[part 2 of 2: packages /MICROSAR/Csm_swc/Interfaces to /MICROSAR/Csm_swc/ComponentTypes]
AUTOSAR XML (schema 00049)
package /MICROSAR/Csm_swc/Interfaces  (continued)
  29 x client server interface, all with is-service=true, service-kind=CRYPTO-SERVICE-MANAGER:  (continued)
    CsmMacVerify_MacVerifyAesCmac  # A message authentication code (MAC) is a short piece of information used to authenticate a message. A MAC algorithm accepts as input a secret key and an arbitrary-length message to be authenticated, and outputs a MAC. The MAC value protects both a message's data integrity as well as its authenticity, by allowing verifiers (who also possess the secret key) to detect any changes to the message content.
      operation MacVerify: possible-error=[CsmMacVerify_MacVerifyAesCmac/E_NOT_OK, CsmMacVerify_MacVerifyAesCmac/CSM_E_BUSY, CsmMacVerify_MacVerifyAesCmac/CSM_E_SMALL_BUFFER, CsmMacVerify_MacVerifyAesCmac/CSM_E_KEY_NOT_VALID, CsmMacVerify_MacVerifyAesCmac/CSM_E_KEY_SIZE_MISMATCH, CsmMacVerify_MacVerifyAesCmac/CSM_E_KEY_EMPTY]  # This interface shall be used to start the MAC verification service of the CSM module.
        5 x arg:
          dataBuffer: type=Csm_MacVerifyDataType_MacVerifyAesCmac, direction=IN, server-argument-impl-policy=USE-ARRAY-BASE-TYPE  # Holds a pointer to the data for which a MAC shall be computed.
          dataLength: type=uint32, direction=IN  # Contains the number of bytes for which the MAC shall be computed.
          compareBuffer: type=Csm_MacVerifyCompareType_MacVerifyAesCmac, direction=IN, server-argument-impl-policy=USE-ARRAY-BASE-TYPE  # Contains the MAC to be verified.
          compareLength: type=uint32, direction=IN  # Contains the length of the MAC to be verified in BITS.
          verifyResult: type=Crypto_VerifyResultType, direction=OUT  # Holds a pointer to the memory location which will hold the result of the MAC verification
      operation CancelJob: possible-error=[CsmMacVerify_MacVerifyAesCmac/E_NOT_OK, CsmMacVerify_MacVerifyAesCmac/CSM_E_JOB_CANCELED]  # Cancels the Job.
      7 x error:
        E_NOT_OK: error-code=1  # The service request failed.
        CSM_E_BUSY: error-code=2  # The service request failed because the service is still busy.
        CSM_E_SMALL_BUFFER: error-code=3  # The service request failed because the provided buffer is too small to store the result.
        CSM_E_KEY_NOT_VALID: error-code=9  # The service request failed because the key is not valid.
        CSM_E_KEY_SIZE_MISMATCH: error-code=10  # The service request failed because the key element is not partially accessible and the provided key element length is too short or too long for that key element.
        CSM_E_KEY_EMPTY: error-code=13  # The service request failed because of uninitialized source key element.
        CSM_E_JOB_CANCELED: error-code=12  # The job has been marked to be aborted at the next opportunity. It will be further processed until the job finish notification.
    CsmDecrypt_AES128Decrypt  # This interface is used to perform the decryption.
      operation Decrypt: possible-error=[CsmDecrypt_AES128Decrypt/E_NOT_OK, CsmDecrypt_AES128Decrypt/CSM_E_BUSY, CsmDecrypt_AES128Decrypt/CSM_E_SMALL_BUFFER, CsmDecrypt_AES128Decrypt/CSM_E_KEY_NOT_VALID, CsmDecrypt_AES128Decrypt/CSM_E_KEY_SIZE_MISMATCH, CsmDecrypt_AES128Decrypt/CSM_E_KEY_EMPTY]  # This interface shall be used to start the Decrypt service of the CSM module.
        4 x arg:
          dataBuffer: type=Csm_DecryptDataType_AES128Decrypt, direction=IN, server-argument-impl-policy=USE-ARRAY-BASE-TYPE  # Holds a pointer to the data for which a plaintext shall be computed.
          dataLength: type=uint32, direction=IN  # Contains the number of bytes for which the plaintext shall be computed.
          resultBuffer: type=Csm_DecryptResultType_AES128Decrypt, direction=OUT, server-argument-impl-policy=USE-ARRAY-BASE-TYPE  # Holds a pointer to the memory location which will hold the plaintext. The memory location must have at least the given length.
          resultLength: type=uint32, direction=INOUT  # Holds a pointer to the memory location in which the length information is stored. On calling this function this parameter shall contain the size of the provided buffer. When the request has finished, the actual length of the returned plaintext shall be stored.
      operation CancelJob: possible-error=[CsmDecrypt_AES128Decrypt/E_NOT_OK, CsmDecrypt_AES128Decrypt/CSM_E_JOB_CANCELED]  # Cancels the Job.
      7 x error:
        E_NOT_OK: error-code=1  # The service request failed.
        CSM_E_BUSY: error-code=2  # The service request failed because the service is still busy.
        CSM_E_SMALL_BUFFER: error-code=3  # The service request failed because the provided buffer is too small to store the result.
        CSM_E_KEY_NOT_VALID: error-code=9  # The service request failed because the key is not valid.
        CSM_E_KEY_SIZE_MISMATCH: error-code=10  # The service request failed because the key element is not partially accessible and the provided key element length is too short or too long for that key element.
        CSM_E_KEY_EMPTY: error-code=13  # The service request failed because of uninitialized source key element.
        CSM_E_JOB_CANCELED: error-code=12  # The job has been marked to be aborted at the next opportunity. It will be further processed until the job finish notification.
    CsmMacGenerate_MacGenAesCmac  # A message authentication code (MAC) is a short piece of information used to authenticate a message. A MAC algorithm accepts as input a secret key and an arbitrary-length message to be authenticated, and outputs a MAC. The MAC value protects both a message's data integrity as well as its authenticity, by allowing verifiers (who also possess the secret key) to detect any changes to the message content.
      operation MacGenerate: possible-error=[CsmMacGenerate_MacGenAesCmac/E_NOT_OK, CsmMacGenerate_MacGenAesCmac/CSM_E_BUSY, CsmMacGenerate_MacGenAesCmac/CSM_E_SMALL_BUFFER, CsmMacGenerate_MacGenAesCmac/CSM_E_KEY_NOT_VALID, CsmMacGenerate_MacGenAesCmac/CSM_E_KEY_SIZE_MISMATCH, CsmMacGenerate_MacGenAesCmac/CSM_E_KEY_EMPTY]  # This interface shall be used to start the MAC generation service of the CSM module.
        4 x arg:
          dataBuffer: type=Csm_MacGenerateDataType_MacGenAesCmac, direction=IN, server-argument-impl-policy=USE-ARRAY-BASE-TYPE  # Holds a pointer to the data for which a MAC shall be computed.
          dataLength: type=uint32, direction=IN  # Contains the number of bytes for which the MAC shall be computed.
          resultBuffer: type=Csm_MacGenerateResultType_MacGenAesCmac, direction=OUT, server-argument-impl-policy=USE-ARRAY-BASE-TYPE  # Holds a pointer to the memory location which will hold the MAC. The memory location must have at least the given length.
          resultLength: type=uint32, direction=INOUT  # Holds a pointer to the memory location in which the length information is stored. On calling this function this parameter shall contain the size of the provided buffer. When the request has finished, the actual length of the returned MAC shall be stored.
      operation CancelJob: possible-error=[CsmMacGenerate_MacGenAesCmac/E_NOT_OK, CsmMacGenerate_MacGenAesCmac/CSM_E_JOB_CANCELED]  # Cancels the Job.
      7 x error:
        E_NOT_OK: error-code=1  # The service request failed.
        CSM_E_BUSY: error-code=2  # The service request failed because the service is still busy.
        CSM_E_SMALL_BUFFER: error-code=3  # The service request failed because the provided buffer is too small to store the result.
        CSM_E_KEY_NOT_VALID: error-code=9  # The service request failed because the key is not valid.
        CSM_E_KEY_SIZE_MISMATCH: error-code=10  # The service request failed because the key element is not partially accessible and the provided key element length is too short or too long for that key element.
        CSM_E_KEY_EMPTY: error-code=13  # The service request failed because of uninitialized source key element.
        CSM_E_JOB_CANCELED: error-code=12  # The job has been marked to be aborted at the next opportunity. It will be further processed until the job finish notification.
    CsmSignatureGenerate_SigGenEd25519  # A digital signature is a type of asymmetric cryptography. Digital signatures are equivalent to traditional handwritten signatures in many respects. Digital signatures can be used to authenticate the source of messages as well as to prove integrity of signed messages. If a message is digitally signed, any change in the message after signature will invalidate the signature. Furthermore, there is no efficient way to modify a message and its signature to produce a new message with a valid signature.
      operation SignatureGenerate: possible-error=[CsmSignatureGenerate_SigGenEd25519/E_NOT_OK, CsmSignatureGenerate_SigGenEd25519/CSM_E_BUSY, CsmSignatureGenerate_SigGenEd25519/CSM_E_SMALL_BUFFER, CsmSignatureGenerate_SigGenEd25519/CSM_E_KEY_NOT_VALID, CsmSignatureGenerate_SigGenEd25519/CSM_E_KEY_SIZE_MISMATCH, CsmSignatureGenerate_SigGenEd25519/CSM_E_KEY_EMPTY]  # This interface shall be used to start the signature generate service of the CSM module.
        4 x arg:
          dataBuffer: type=Csm_SignatureGenerateDataType_SigGenEd25519, direction=IN, server-argument-impl-policy=USE-ARRAY-BASE-TYPE  # Holds a pointer to the data for which a signature shall be computed.
          dataLength: type=uint32, direction=IN  # Contains the number of bytes for which the signature shall be computed.
          resultBuffer: type=Csm_SignatureGenerateResultType_SigGenEd25519, direction=OUT, server-argument-impl-policy=USE-ARRAY-BASE-TYPE  # Holds a pointer to the memory location which will hold the signature. The memory location must have at least the given length.
          resultLength: type=uint32, direction=INOUT  # Holds a pointer to the memory location in which the length information is stored. On calling this function this parameter shall contain the size of the provided buffer. When the request has finished, the actual length of the returned signature shall be stored.
      operation CancelJob: possible-error=[CsmSignatureGenerate_SigGenEd25519/E_NOT_OK, CsmSignatureGenerate_SigGenEd25519/CSM_E_JOB_CANCELED]  # Cancels the Job.
      7 x error:
        E_NOT_OK: error-code=1  # The service request failed.
        CSM_E_BUSY: error-code=2  # The service request failed because the service is still busy.
        CSM_E_SMALL_BUFFER: error-code=3  # The service request failed because the provided buffer is too small to store the result.
        CSM_E_KEY_NOT_VALID: error-code=9  # The service request failed because the key is not valid.
        CSM_E_KEY_SIZE_MISMATCH: error-code=10  # The service request failed because the key element is not partially accessible and the provided key element length is too short or too long for that key element.
        CSM_E_KEY_EMPTY: error-code=13  # The service request failed because of uninitialized source key element.
        CSM_E_JOB_CANCELED: error-code=12  # The job has been marked to be aborted at the next opportunity. It will be further processed until the job finish notification.
    CsmSignatureVerify_SigVerifyEd25519_SSA  # A digital signature is a type of asymmetric cryptography. Digital signatures are equivalent to traditional handwritten signatures in many respects. Digital signatures can be used to authenticate the source of messages as well as to prove integrity of signed messages. If a message is digitally signed, any change in the message after signature will invalidate the signature. Furthermore, there is no efficient way to modify a message and its signature to produce a new message with a valid signature.
      operation SignatureVerify: possible-error=[CsmSignatureVerify_SigVerifyEd25519_SSA/E_NOT_OK, CsmSignatureVerify_SigVerifyEd25519_SSA/CSM_E_BUSY, CsmSignatureVerify_SigVerifyEd25519_SSA/CSM_E_SMALL_BUFFER, CsmSignatureVerify_SigVerifyEd25519_SSA/CSM_E_KEY_NOT_VALID, CsmSignatureVerify_SigVerifyEd25519_SSA/CSM_E_KEY_SIZE_MISMATCH, CsmSignatureVerify_SigVerifyEd25519_SSA/CSM_E_KEY_EMPTY]  # This interface shall be used to start the signature verification service of the CSM module.
        5 x arg:
          dataBuffer: type=Csm_SignatureVerifyDataType_SigVerifyEd25519_SSA, direction=IN, server-argument-impl-policy=USE-ARRAY-BASE-TYPE  # Holds a pointer to the data for which a signature shall be computed.
          dataLength: type=uint32, direction=IN  # Contains the number of bytes for which the signature shall be computed.
          compareBuffer: type=Csm_SignatureVerifyCompareType_SigVerifyEd25519_SSA, direction=IN, server-argument-impl-policy=USE-ARRAY-BASE-TYPE  # Contains the signature to be verified.
          compareLength: type=uint32, direction=IN  # Contains the length of the signature to be verified in bytes.
          verifyResult: type=Crypto_VerifyResultType, direction=OUT  # Holds a pointer to the memory location which will hold the result of the signature verification
      operation CancelJob: possible-error=[CsmSignatureVerify_SigVerifyEd25519_SSA/E_NOT_OK, CsmSignatureVerify_SigVerifyEd25519_SSA/CSM_E_JOB_CANCELED]  # Cancels the Job.
      7 x error:
        E_NOT_OK: error-code=1  # The service request failed.
        CSM_E_BUSY: error-code=2  # The service request failed because the service is still busy.
        CSM_E_SMALL_BUFFER: error-code=3  # The service request failed because the provided buffer is too small to store the result.
        CSM_E_KEY_NOT_VALID: error-code=9  # The service request failed because the key is not valid.
        CSM_E_KEY_SIZE_MISMATCH: error-code=10  # The service request failed because the key element is not partially accessible and the provided key element length is too short or too long for that key element.
        CSM_E_KEY_EMPTY: error-code=13  # The service request failed because of uninitialized source key element.
        CSM_E_JOB_CANCELED: error-code=12  # The job has been marked to be aborted at the next opportunity. It will be further processed until the job finish notification.
    CsmKeyManagement_CsmKey_Ssa_TrustModelPrivateEcuUnique_StagingKey  # Interface to execute the key management functions.
      13 x operation:
        CertificateParse: possible-error=[CsmKeyManagement_CsmKey_Ssa_TrustModelPrivateEcuUnique_StagingKey/E_NOT_OK, CsmKeyManagement_CsmKey_Ssa_TrustModelPrivateEcuUnique_StagingKey/CSM_E_BUSY, CsmKeyManagement_CsmKey_Ssa_TrustModelPrivateEcuUnique_StagingKey/CSM_E_KEY_EMPTY]  # This function shall dispatch the certificate parse function to the CRYIF.
        CertificateVerify: possible-error=[CsmKeyManagement_CsmKey_Ssa_TrustModelPrivateEcuUnique_StagingKey/E_NOT_OK, CsmKeyManagement_CsmKey_Ssa_TrustModelPrivateEcuUnique_StagingKey/CSM_E_BUSY, CsmKeyManagement_CsmKey_Ssa_TrustModelPrivateEcuUnique_StagingKey/CSM_E_KEY_EMPTY]  # Verifies the certificate stored in the key referenced by verifyKeyId with the certificate stored in the key referenced by keyId. Note: Only certificates stored in the same Crypto Driver can be verified against each other. If the key element CRYPTO_KE_CERTIFICATE_CURRENT_TIME is used for the verification of the validity period of the certificate indentified by verifyKeyId, it shall have the same format as the timestamp in the certificate.
          arg verifyKeyId: type=uint32, direction=IN  # Holds the identifier of the key containing the certificate to be verified.
          arg verifyPtr: type=Crypto_VerifyResultType, direction=OUT  # Contains the result of the certificate verification.
        KeyCopy: possible-error=[CsmKeyManagement_CsmKey_Ssa_TrustModelPrivateEcuUnique_StagingKey/E_NOT_OK, CsmKeyManagement_CsmKey_Ssa_TrustModelPrivateEcuUnique_StagingKey/CSM_E_BUSY, CsmKeyManagement_CsmKey_Ssa_TrustModelPrivateEcuUnique_StagingKey/CSM_E_SMALL_BUFFER, CsmKeyManagement_CsmKey_Ssa_TrustModelPrivateEcuUnique_StagingKey/CSM_E_KEY_READ_FAIL, CsmKeyManagement_CsmKey_Ssa_TrustModelPrivateEcuUnique_StagingKey/CSM_E_KEY_WRITE_FAIL, CsmKeyManagement_CsmKey_Ssa_TrustModelPrivateEcuUnique_StagingKey/CSM_E_KEY_SIZE_MISMATCH, CsmKeyManagement_CsmKey_Ssa_TrustModelPrivateEcuUnique_StagingKey/CSM_E_KEY_EMPTY]  # This function shall copy all key elements from the source key to a target key.
          arg targetKeyId: type=uint32, direction=IN  # Holds the identifier of the key whose key element shall be the destination element.
        KeyDerive: possible-error=[CsmKeyManagement_CsmKey_Ssa_TrustModelPrivateEcuUnique_StagingKey/E_NOT_OK, CsmKeyManagement_CsmKey_Ssa_TrustModelPrivateEcuUnique_StagingKey/CSM_E_BUSY, CsmKeyManagement_CsmKey_Ssa_TrustModelPrivateEcuUnique_StagingKey/CSM_E_KEY_READ_FAIL, CsmKeyManagement_CsmKey_Ssa_TrustModelPrivateEcuUnique_StagingKey/CSM_E_KEY_WRITE_FAIL, CsmKeyManagement_CsmKey_Ssa_TrustModelPrivateEcuUnique_StagingKey/CSM_E_KEY_SIZE_MISMATCH, CsmKeyManagement_CsmKey_Ssa_TrustModelPrivateEcuUnique_StagingKey/CSM_E_KEY_EMPTY]  # Derives a new key by using the key elements in the given key. The given key contains the key elements for the password and salt. The derived key is stored in the key element with the id 1 of the key identified by targetCryptoKeyId.
          arg targetKeyId: type=uint32, direction=IN  # Holds the identifier of the key which is used to store the derived key.
        KeyElementCopy: possible-error=[CsmKeyManagement_CsmKey_Ssa_TrustModelPrivateEcuUnique_StagingKey/E_NOT_OK, CsmKeyManagement_CsmKey_Ssa_TrustModelPrivateEcuUnique_StagingKey/CSM_E_BUSY, CsmKeyManagement_CsmKey_Ssa_TrustModelPrivateEcuUnique_StagingKey/CSM_E_SMALL_BUFFER, CsmKeyManagement_CsmKey_Ssa_TrustModelPrivateEcuUnique_StagingKey/CSM_E_KEY_READ_FAIL, CsmKeyManagement_CsmKey_Ssa_TrustModelPrivateEcuUnique_StagingKey/CSM_E_KEY_WRITE_FAIL, CsmKeyManagement_CsmKey_Ssa_TrustModelPrivateEcuUnique_StagingKey/CSM_E_KEY_SIZE_MISMATCH, CsmKeyManagement_CsmKey_Ssa_TrustModelPrivateEcuUnique_StagingKey/CSM_E_KEY_EMPTY]  # This function shall copy a key elements from one key to a target key.
          arg keyElementId: type=uint32, direction=IN  # Holds the identifier of the key element which shall be the source for the copy operation.
          arg targetKeyId: type=uint32, direction=IN  # Holds the identifier of the key whose key element shall be the destination element.
          arg targetKeyElementId: type=uint32, direction=IN  # Holds the identifier of the key element which shall be the destination for the copy operation.
        KeyElementCopyPartial: possible-error=[CsmKeyManagement_CsmKey_Ssa_TrustModelPrivateEcuUnique_StagingKey/E_NOT_OK, CsmKeyManagement_CsmKey_Ssa_TrustModelPrivateEcuUnique_StagingKey/CSM_E_BUSY, CsmKeyManagement_CsmKey_Ssa_TrustModelPrivateEcuUnique_StagingKey/CSM_E_KEY_NOT_AVAILABLE, CsmKeyManagement_CsmKey_Ssa_TrustModelPrivateEcuUnique_StagingKey/CSM_E_KEY_READ_FAIL, CsmKeyManagement_CsmKey_Ssa_TrustModelPrivateEcuUnique_StagingKey/CSM_E_KEY_WRITE_FAIL, CsmKeyManagement_CsmKey_Ssa_TrustModelPrivateEcuUnique_StagingKey/CSM_E_KEY_SIZE_MISMATCH, CsmKeyManagement_CsmKey_Ssa_TrustModelPrivateEcuUnique_StagingKey/CSM_E_KEY_EMPTY]  # This function shall copy parts of a key element from one key to parts of a target key element of a target key.
          6 x arg, all with type=uint32, direction=IN:
            keyElementId  # Holds the identifier of the key element which shall be the source for the copy operation.
            keyElementSourceOffset  # This is the offset of the source key element indicating the start index of the copy operation.
            keyElementTargetOffset  # This is the offset of the destination key element indicating the start index of the copy operation.
            keyElementCopyLength  # Specifies the number of bytes that shall be copied.
            targetKeyId  # Holds the identifier of the key whose key element shall be the destination element.
            targetKeyElementId  # Holds the identifier of the key element which shall be the destination for the copy operation.
        KeyElementGet: possible-error=[CsmKeyManagement_CsmKey_Ssa_TrustModelPrivateEcuUnique_StagingKey/E_NOT_OK, CsmKeyManagement_CsmKey_Ssa_TrustModelPrivateEcuUnique_StagingKey/CSM_E_BUSY, CsmKeyManagement_CsmKey_Ssa_TrustModelPrivateEcuUnique_StagingKey/CSM_E_SMALL_BUFFER, CsmKeyManagement_CsmKey_Ssa_TrustModelPrivateEcuUnique_StagingKey/CSM_E_KEY_READ_FAIL, CsmKeyManagement_CsmKey_Ssa_TrustModelPrivateEcuUnique_StagingKey/CSM_E_KEY_NOT_AVAILABLE, CsmKeyManagement_CsmKey_Ssa_TrustModelPrivateEcuUnique_StagingKey/CSM_E_KEY_EMPTY]  # Retrieves the key element bytes from a specific key element of the key and stores the key element in the provided buffer.
          arg keyElementId: type=uint32, direction=IN  # Holds the identifier of the key element to be read.
          arg keyPtr: type=Csm_KeyDataType_CsmKey_Ssa_TrustModelPrivateEcuUnique_StagingKey, direction=OUT, server-argument-impl-policy=USE-ARRAY-BASE-TYPE  # Holds the data to the key element bytes to be written.
          arg keyLength: type=uint32, direction=INOUT  # Contains the number of key element bytes.
        KeyElementSet: possible-error=[CsmKeyManagement_CsmKey_Ssa_TrustModelPrivateEcuUnique_StagingKey/E_NOT_OK, CsmKeyManagement_CsmKey_Ssa_TrustModelPrivateEcuUnique_StagingKey/CSM_E_BUSY, CsmKeyManagement_CsmKey_Ssa_TrustModelPrivateEcuUnique_StagingKey/CSM_E_KEY_WRITE_FAIL, CsmKeyManagement_CsmKey_Ssa_TrustModelPrivateEcuUnique_StagingKey/CSM_E_KEY_NOT_AVAILABLE, CsmKeyManagement_CsmKey_Ssa_TrustModelPrivateEcuUnique_StagingKey/CSM_E_KEY_SIZE_MISMATCH]  # Sets the given key element bytes to the key.
          arg keyElementId: type=uint32, direction=IN  # Holds the identifier of the key element to be written.
          arg keyPtr: type=Csm_KeyDataType_CsmKey_Ssa_TrustModelPrivateEcuUnique_StagingKey, direction=IN, server-argument-impl-policy=USE-ARRAY-BASE-TYPE  # Holds the data to the key element bytes to be processed.
          arg keyLength: type=uint32, direction=IN  # Contains the number of key element bytes.
        KeyExchangeCalcPubVal: possible-error=[CsmKeyManagement_CsmKey_Ssa_TrustModelPrivateEcuUnique_StagingKey/E_NOT_OK, CsmKeyManagement_CsmKey_Ssa_TrustModelPrivateEcuUnique_StagingKey/CSM_E_BUSY, CsmKeyManagement_CsmKey_Ssa_TrustModelPrivateEcuUnique_StagingKey/CSM_E_SMALL_BUFFER, CsmKeyManagement_CsmKey_Ssa_TrustModelPrivateEcuUnique_StagingKey/CSM_E_KEY_EMPTY]  # Calculates the public value of the current user for the key exchange and stores the public key in the provided buffer.
          arg publicValuePtr: type=Csm_PublicValueDataType_CsmKey_Ssa_TrustModelPrivateEcuUnique_StagingKey, direction=OUT, server-argument-impl-policy=USE-ARRAY-BASE-TYPE  # Holds a pointer to the memory location in which the public value length in bytes is stored. On calling this function, this parameter shall contain the size of the buffer in bytes provided by publicValuePtr. When the request has finished, the actual length of the returned value shall be stored.
          arg publicValueLengthPtr: type=uint32, direction=INOUT  # Contains the pointer to the data where the public value shall be stored.
        KeyExchangeCalcSecret: possible-error=[CsmKeyManagement_CsmKey_Ssa_TrustModelPrivateEcuUnique_StagingKey/E_NOT_OK, CsmKeyManagement_CsmKey_Ssa_TrustModelPrivateEcuUnique_StagingKey/CSM_E_BUSY, CsmKeyManagement_CsmKey_Ssa_TrustModelPrivateEcuUnique_StagingKey/CSM_E_SMALL_BUFFER, CsmKeyManagement_CsmKey_Ssa_TrustModelPrivateEcuUnique_StagingKey/CSM_E_KEY_EMPTY]  # Calculates the shared secret key for the key exchange with the key material of the key identified by the keyId and the partner public key. The shared secret key is stored as a key element in the same key.
          arg partnerPublicValuePtr: type=Csm_PublicValueDataType_CsmKey_Ssa_TrustModelPrivateEcuUnique_StagingKey, direction=IN, server-argument-impl-policy=USE-ARRAY-BASE-TYPE  # Holds the pointer to the memory location containing the partner's public value.
          arg partnerPublicValueLength: type=uint32, direction=IN  # Contains the number of bytes of the partner public value.
        KeyGenerate: possible-error=[CsmKeyManagement_CsmKey_Ssa_TrustModelPrivateEcuUnique_StagingKey/E_NOT_OK, CsmKeyManagement_CsmKey_Ssa_TrustModelPrivateEcuUnique_StagingKey/CSM_E_BUSY, CsmKeyManagement_CsmKey_Ssa_TrustModelPrivateEcuUnique_StagingKey/CSM_E_KEY_EMPTY]  # Generates new key material and store it in the key identified by keyId.
        KeySetValid: possible-error=[CsmKeyManagement_CsmKey_Ssa_TrustModelPrivateEcuUnique_StagingKey/E_NOT_OK, CsmKeyManagement_CsmKey_Ssa_TrustModelPrivateEcuUnique_StagingKey/CSM_E_BUSY]  # Sets the given key element bytes to the key.
        RandomSeed: possible-error=[CsmKeyManagement_CsmKey_Ssa_TrustModelPrivateEcuUnique_StagingKey/E_NOT_OK, CsmKeyManagement_CsmKey_Ssa_TrustModelPrivateEcuUnique_StagingKey/CSM_E_BUSY]  # Feeds a key element with a random seed.
          arg seedPtr: type=Csm_SeedDataTypeCsmKey_Ssa_TrustModelPrivateEcuUnique_StagingKey, direction=IN, server-argument-impl-policy=USE-ARRAY-BASE-TYPE  # Holds the data which shall be used for the random seed initialization.
          arg seedLength: type=uint32, direction=IN  # Contains the length of the seed in bytes.
      8 x error:
        E_NOT_OK: error-code=1  # The service request failed.
        CSM_E_BUSY: error-code=2  # The service request failed because the service is still busy.
        CSM_E_SMALL_BUFFER: error-code=3  # The service request failed because the provided buffer is too small to store the result.
        CSM_E_KEY_READ_FAIL: error-code=6  # The service request failed because read access was denied.
        CSM_E_KEY_WRITE_FAIL: error-code=7  # The service request failed because write access was denied.
        CSM_E_KEY_NOT_AVAILABLE: error-code=8  # The service request failed because the key is not available.
        CSM_E_KEY_SIZE_MISMATCH: error-code=10  # The service request failed because the key element is not partially accessible and the provided key element length is too short or too long for that key element.
        CSM_E_KEY_EMPTY: error-code=13  # The service request failed because of uninitialized source key element.
    CsmKeyManagement_CsmKey_Ssa_TrustModelEcuPublic_LiveKey  # Interface to execute the key management functions.
      13 x operation:
        CertificateParse: possible-error=[CsmKeyManagement_CsmKey_Ssa_TrustModelEcuPublic_LiveKey/E_NOT_OK, CsmKeyManagement_CsmKey_Ssa_TrustModelEcuPublic_LiveKey/CSM_E_BUSY, CsmKeyManagement_CsmKey_Ssa_TrustModelEcuPublic_LiveKey/CSM_E_KEY_EMPTY]  # This function shall dispatch the certificate parse function to the CRYIF.
        CertificateVerify: possible-error=[CsmKeyManagement_CsmKey_Ssa_TrustModelEcuPublic_LiveKey/E_NOT_OK, CsmKeyManagement_CsmKey_Ssa_TrustModelEcuPublic_LiveKey/CSM_E_BUSY, CsmKeyManagement_CsmKey_Ssa_TrustModelEcuPublic_LiveKey/CSM_E_KEY_EMPTY]  # Verifies the certificate stored in the key referenced by verifyKeyId with the certificate stored in the key referenced by keyId. Note: Only certificates stored in the same Crypto Driver can be verified against each other. If the key element CRYPTO_KE_CERTIFICATE_CURRENT_TIME is used for the verification of the validity period of the certificate indentified by verifyKeyId, it shall have the same format as the timestamp in the certificate.
          arg verifyKeyId: type=uint32, direction=IN  # Holds the identifier of the key containing the certificate to be verified.
          arg verifyPtr: type=Crypto_VerifyResultType, direction=OUT  # Contains the result of the certificate verification.
        KeyCopy: possible-error=[CsmKeyManagement_CsmKey_Ssa_TrustModelEcuPublic_LiveKey/E_NOT_OK, CsmKeyManagement_CsmKey_Ssa_TrustModelEcuPublic_LiveKey/CSM_E_BUSY, CsmKeyManagement_CsmKey_Ssa_TrustModelEcuPublic_LiveKey/CSM_E_SMALL_BUFFER, CsmKeyManagement_CsmKey_Ssa_TrustModelEcuPublic_LiveKey/CSM_E_KEY_READ_FAIL, CsmKeyManagement_CsmKey_Ssa_TrustModelEcuPublic_LiveKey/CSM_E_KEY_WRITE_FAIL, CsmKeyManagement_CsmKey_Ssa_TrustModelEcuPublic_LiveKey/CSM_E_KEY_SIZE_MISMATCH, CsmKeyManagement_CsmKey_Ssa_TrustModelEcuPublic_LiveKey/CSM_E_KEY_EMPTY]  # This function shall copy all key elements from the source key to a target key.
          arg targetKeyId: type=uint32, direction=IN  # Holds the identifier of the key whose key element shall be the destination element.
        KeyDerive: possible-error=[CsmKeyManagement_CsmKey_Ssa_TrustModelEcuPublic_LiveKey/E_NOT_OK, CsmKeyManagement_CsmKey_Ssa_TrustModelEcuPublic_LiveKey/CSM_E_BUSY, CsmKeyManagement_CsmKey_Ssa_TrustModelEcuPublic_LiveKey/CSM_E_KEY_READ_FAIL, CsmKeyManagement_CsmKey_Ssa_TrustModelEcuPublic_LiveKey/CSM_E_KEY_WRITE_FAIL, CsmKeyManagement_CsmKey_Ssa_TrustModelEcuPublic_LiveKey/CSM_E_KEY_SIZE_MISMATCH, CsmKeyManagement_CsmKey_Ssa_TrustModelEcuPublic_LiveKey/CSM_E_KEY_EMPTY]  # Derives a new key by using the key elements in the given key. The given key contains the key elements for the password and salt. The derived key is stored in the key element with the id 1 of the key identified by targetCryptoKeyId.
          arg targetKeyId: type=uint32, direction=IN  # Holds the identifier of the key which is used to store the derived key.
        KeyElementCopy: possible-error=[CsmKeyManagement_CsmKey_Ssa_TrustModelEcuPublic_LiveKey/E_NOT_OK, CsmKeyManagement_CsmKey_Ssa_TrustModelEcuPublic_LiveKey/CSM_E_BUSY, CsmKeyManagement_CsmKey_Ssa_TrustModelEcuPublic_LiveKey/CSM_E_SMALL_BUFFER, CsmKeyManagement_CsmKey_Ssa_TrustModelEcuPublic_LiveKey/CSM_E_KEY_READ_FAIL, CsmKeyManagement_CsmKey_Ssa_TrustModelEcuPublic_LiveKey/CSM_E_KEY_WRITE_FAIL, CsmKeyManagement_CsmKey_Ssa_TrustModelEcuPublic_LiveKey/CSM_E_KEY_SIZE_MISMATCH, CsmKeyManagement_CsmKey_Ssa_TrustModelEcuPublic_LiveKey/CSM_E_KEY_EMPTY]  # This function shall copy a key elements from one key to a target key.
          arg keyElementId: type=uint32, direction=IN  # Holds the identifier of the key element which shall be the source for the copy operation.
          arg targetKeyId: type=uint32, direction=IN  # Holds the identifier of the key whose key element shall be the destination element.
          arg targetKeyElementId: type=uint32, direction=IN  # Holds the identifier of the key element which shall be the destination for the copy operation.
        KeyElementCopyPartial: possible-error=[CsmKeyManagement_CsmKey_Ssa_TrustModelEcuPublic_LiveKey/E_NOT_OK, CsmKeyManagement_CsmKey_Ssa_TrustModelEcuPublic_LiveKey/CSM_E_BUSY, CsmKeyManagement_CsmKey_Ssa_TrustModelEcuPublic_LiveKey/CSM_E_KEY_NOT_AVAILABLE, CsmKeyManagement_CsmKey_Ssa_TrustModelEcuPublic_LiveKey/CSM_E_KEY_READ_FAIL, CsmKeyManagement_CsmKey_Ssa_TrustModelEcuPublic_LiveKey/CSM_E_KEY_WRITE_FAIL, CsmKeyManagement_CsmKey_Ssa_TrustModelEcuPublic_LiveKey/CSM_E_KEY_SIZE_MISMATCH, CsmKeyManagement_CsmKey_Ssa_TrustModelEcuPublic_LiveKey/CSM_E_KEY_EMPTY]  # This function shall copy parts of a key element from one key to parts of a target key element of a target key.
          6 x arg, all with type=uint32, direction=IN:
            keyElementId  # Holds the identifier of the key element which shall be the source for the copy operation.
            keyElementSourceOffset  # This is the offset of the source key element indicating the start index of the copy operation.
            keyElementTargetOffset  # This is the offset of the destination key element indicating the start index of the copy operation.
            keyElementCopyLength  # Specifies the number of bytes that shall be copied.
            targetKeyId  # Holds the identifier of the key whose key element shall be the destination element.
            targetKeyElementId  # Holds the identifier of the key element which shall be the destination for the copy operation.
        KeyElementGet: possible-error=[CsmKeyManagement_CsmKey_Ssa_TrustModelEcuPublic_LiveKey/E_NOT_OK, CsmKeyManagement_CsmKey_Ssa_TrustModelEcuPublic_LiveKey/CSM_E_BUSY, CsmKeyManagement_CsmKey_Ssa_TrustModelEcuPublic_LiveKey/CSM_E_SMALL_BUFFER, CsmKeyManagement_CsmKey_Ssa_TrustModelEcuPublic_LiveKey/CSM_E_KEY_READ_FAIL, CsmKeyManagement_CsmKey_Ssa_TrustModelEcuPublic_LiveKey/CSM_E_KEY_NOT_AVAILABLE, CsmKeyManagement_CsmKey_Ssa_TrustModelEcuPublic_LiveKey/CSM_E_KEY_EMPTY]  # Retrieves the key element bytes from a specific key element of the key and stores the key element in the provided buffer.
          arg keyElementId: type=uint32, direction=IN  # Holds the identifier of the key element to be read.
          arg keyPtr: type=Csm_KeyDataType_CsmKey_Ssa_TrustModelEcuPublic_LiveKey, direction=OUT, server-argument-impl-policy=USE-ARRAY-BASE-TYPE  # Holds the data to the key element bytes to be written.
          arg keyLength: type=uint32, direction=INOUT  # Contains the number of key element bytes.
        KeyElementSet: possible-error=[CsmKeyManagement_CsmKey_Ssa_TrustModelEcuPublic_LiveKey/E_NOT_OK, CsmKeyManagement_CsmKey_Ssa_TrustModelEcuPublic_LiveKey/CSM_E_BUSY, CsmKeyManagement_CsmKey_Ssa_TrustModelEcuPublic_LiveKey/CSM_E_KEY_WRITE_FAIL, CsmKeyManagement_CsmKey_Ssa_TrustModelEcuPublic_LiveKey/CSM_E_KEY_NOT_AVAILABLE, CsmKeyManagement_CsmKey_Ssa_TrustModelEcuPublic_LiveKey/CSM_E_KEY_SIZE_MISMATCH]  # Sets the given key element bytes to the key.
          arg keyElementId: type=uint32, direction=IN  # Holds the identifier of the key element to be written.
          arg keyPtr: type=Csm_KeyDataType_CsmKey_Ssa_TrustModelEcuPublic_LiveKey, direction=IN, server-argument-impl-policy=USE-ARRAY-BASE-TYPE  # Holds the data to the key element bytes to be processed.
          arg keyLength: type=uint32, direction=IN  # Contains the number of key element bytes.
        KeyExchangeCalcPubVal: possible-error=[CsmKeyManagement_CsmKey_Ssa_TrustModelEcuPublic_LiveKey/E_NOT_OK, CsmKeyManagement_CsmKey_Ssa_TrustModelEcuPublic_LiveKey/CSM_E_BUSY, CsmKeyManagement_CsmKey_Ssa_TrustModelEcuPublic_LiveKey/CSM_E_SMALL_BUFFER, CsmKeyManagement_CsmKey_Ssa_TrustModelEcuPublic_LiveKey/CSM_E_KEY_EMPTY]  # Calculates the public value of the current user for the key exchange and stores the public key in the provided buffer.
          arg publicValuePtr: type=Csm_PublicValueDataType_CsmKey_Ssa_TrustModelEcuPublic_LiveKey, direction=OUT, server-argument-impl-policy=USE-ARRAY-BASE-TYPE  # Holds a pointer to the memory location in which the public value length in bytes is stored. On calling this function, this parameter shall contain the size of the buffer in bytes provided by publicValuePtr. When the request has finished, the actual length of the returned value shall be stored.
          arg publicValueLengthPtr: type=uint32, direction=INOUT  # Contains the pointer to the data where the public value shall be stored.
        KeyExchangeCalcSecret: possible-error=[CsmKeyManagement_CsmKey_Ssa_TrustModelEcuPublic_LiveKey/E_NOT_OK, CsmKeyManagement_CsmKey_Ssa_TrustModelEcuPublic_LiveKey/CSM_E_BUSY, CsmKeyManagement_CsmKey_Ssa_TrustModelEcuPublic_LiveKey/CSM_E_SMALL_BUFFER, CsmKeyManagement_CsmKey_Ssa_TrustModelEcuPublic_LiveKey/CSM_E_KEY_EMPTY]  # Calculates the shared secret key for the key exchange with the key material of the key identified by the keyId and the partner public key. The shared secret key is stored as a key element in the same key.
          arg partnerPublicValuePtr: type=Csm_PublicValueDataType_CsmKey_Ssa_TrustModelEcuPublic_LiveKey, direction=IN, server-argument-impl-policy=USE-ARRAY-BASE-TYPE  # Holds the pointer to the memory location containing the partner's public value.
          arg partnerPublicValueLength: type=uint32, direction=IN  # Contains the number of bytes of the partner public value.
        KeyGenerate: possible-error=[CsmKeyManagement_CsmKey_Ssa_TrustModelEcuPublic_LiveKey/E_NOT_OK, CsmKeyManagement_CsmKey_Ssa_TrustModelEcuPublic_LiveKey/CSM_E_BUSY, CsmKeyManagement_CsmKey_Ssa_TrustModelEcuPublic_LiveKey/CSM_E_KEY_EMPTY]  # Generates new key material and store it in the key identified by keyId.
        KeySetValid: possible-error=[CsmKeyManagement_CsmKey_Ssa_TrustModelEcuPublic_LiveKey/E_NOT_OK, CsmKeyManagement_CsmKey_Ssa_TrustModelEcuPublic_LiveKey/CSM_E_BUSY]  # Sets the given key element bytes to the key.
        RandomSeed: possible-error=[CsmKeyManagement_CsmKey_Ssa_TrustModelEcuPublic_LiveKey/E_NOT_OK, CsmKeyManagement_CsmKey_Ssa_TrustModelEcuPublic_LiveKey/CSM_E_BUSY]  # Feeds a key element with a random seed.
          arg seedPtr: type=Csm_SeedDataTypeCsmKey_Ssa_TrustModelEcuPublic_LiveKey, direction=IN, server-argument-impl-policy=USE-ARRAY-BASE-TYPE  # Holds the data which shall be used for the random seed initialization.
          arg seedLength: type=uint32, direction=IN  # Contains the length of the seed in bytes.
      8 x error:
        E_NOT_OK: error-code=1  # The service request failed.
        CSM_E_BUSY: error-code=2  # The service request failed because the service is still busy.
        CSM_E_SMALL_BUFFER: error-code=3  # The service request failed because the provided buffer is too small to store the result.
        CSM_E_KEY_READ_FAIL: error-code=6  # The service request failed because read access was denied.
        CSM_E_KEY_WRITE_FAIL: error-code=7  # The service request failed because write access was denied.
        CSM_E_KEY_NOT_AVAILABLE: error-code=8  # The service request failed because the key is not available.
        CSM_E_KEY_SIZE_MISMATCH: error-code=10  # The service request failed because the key element is not partially accessible and the provided key element length is too short or too long for that key element.
        CSM_E_KEY_EMPTY: error-code=13  # The service request failed because of uninitialized source key element.
    CsmKeyManagement_CsmKey_Ssa_TrustModelEcuPublicCsr_StagingKey  # Interface to execute the key management functions.
      13 x operation:
        CertificateParse: possible-error=[CsmKeyManagement_CsmKey_Ssa_TrustModelEcuPublicCsr_StagingKey/E_NOT_OK, CsmKeyManagement_CsmKey_Ssa_TrustModelEcuPublicCsr_StagingKey/CSM_E_BUSY, CsmKeyManagement_CsmKey_Ssa_TrustModelEcuPublicCsr_StagingKey/CSM_E_KEY_EMPTY]  # This function shall dispatch the certificate parse function to the CRYIF.
        CertificateVerify: possible-error=[CsmKeyManagement_CsmKey_Ssa_TrustModelEcuPublicCsr_StagingKey/E_NOT_OK, CsmKeyManagement_CsmKey_Ssa_TrustModelEcuPublicCsr_StagingKey/CSM_E_BUSY, CsmKeyManagement_CsmKey_Ssa_TrustModelEcuPublicCsr_StagingKey/CSM_E_KEY_EMPTY]  # Verifies the certificate stored in the key referenced by verifyKeyId with the certificate stored in the key referenced by keyId. Note: Only certificates stored in the same Crypto Driver can be verified against each other. If the key element CRYPTO_KE_CERTIFICATE_CURRENT_TIME is used for the verification of the validity period of the certificate indentified by verifyKeyId, it shall have the same format as the timestamp in the certificate.
          arg verifyKeyId: type=uint32, direction=IN  # Holds the identifier of the key containing the certificate to be verified.
          arg verifyPtr: type=Crypto_VerifyResultType, direction=OUT  # Contains the result of the certificate verification.
        KeyCopy: possible-error=[CsmKeyManagement_CsmKey_Ssa_TrustModelEcuPublicCsr_StagingKey/E_NOT_OK, CsmKeyManagement_CsmKey_Ssa_TrustModelEcuPublicCsr_StagingKey/CSM_E_BUSY, CsmKeyManagement_CsmKey_Ssa_TrustModelEcuPublicCsr_StagingKey/CSM_E_SMALL_BUFFER, CsmKeyManagement_CsmKey_Ssa_TrustModelEcuPublicCsr_StagingKey/CSM_E_KEY_READ_FAIL, CsmKeyManagement_CsmKey_Ssa_TrustModelEcuPublicCsr_StagingKey/CSM_E_KEY_WRITE_FAIL, CsmKeyManagement_CsmKey_Ssa_TrustModelEcuPublicCsr_StagingKey/CSM_E_KEY_SIZE_MISMATCH, CsmKeyManagement_CsmKey_Ssa_TrustModelEcuPublicCsr_StagingKey/CSM_E_KEY_EMPTY]  # This function shall copy all key elements from the source key to a target key.
          arg targetKeyId: type=uint32, direction=IN  # Holds the identifier of the key whose key element shall be the destination element.
        KeyDerive: possible-error=[CsmKeyManagement_CsmKey_Ssa_TrustModelEcuPublicCsr_StagingKey/E_NOT_OK, CsmKeyManagement_CsmKey_Ssa_TrustModelEcuPublicCsr_StagingKey/CSM_E_BUSY, CsmKeyManagement_CsmKey_Ssa_TrustModelEcuPublicCsr_StagingKey/CSM_E_KEY_READ_FAIL, CsmKeyManagement_CsmKey_Ssa_TrustModelEcuPublicCsr_StagingKey/CSM_E_KEY_WRITE_FAIL, CsmKeyManagement_CsmKey_Ssa_TrustModelEcuPublicCsr_StagingKey/CSM_E_KEY_SIZE_MISMATCH, CsmKeyManagement_CsmKey_Ssa_TrustModelEcuPublicCsr_StagingKey/CSM_E_KEY_EMPTY]  # Derives a new key by using the key elements in the given key. The given key contains the key elements for the password and salt. The derived key is stored in the key element with the id 1 of the key identified by targetCryptoKeyId.
          arg targetKeyId: type=uint32, direction=IN  # Holds the identifier of the key which is used to store the derived key.
        KeyElementCopy: possible-error=[CsmKeyManagement_CsmKey_Ssa_TrustModelEcuPublicCsr_StagingKey/E_NOT_OK, CsmKeyManagement_CsmKey_Ssa_TrustModelEcuPublicCsr_StagingKey/CSM_E_BUSY, CsmKeyManagement_CsmKey_Ssa_TrustModelEcuPublicCsr_StagingKey/CSM_E_SMALL_BUFFER, CsmKeyManagement_CsmKey_Ssa_TrustModelEcuPublicCsr_StagingKey/CSM_E_KEY_READ_FAIL, CsmKeyManagement_CsmKey_Ssa_TrustModelEcuPublicCsr_StagingKey/CSM_E_KEY_WRITE_FAIL, CsmKeyManagement_CsmKey_Ssa_TrustModelEcuPublicCsr_StagingKey/CSM_E_KEY_SIZE_MISMATCH, CsmKeyManagement_CsmKey_Ssa_TrustModelEcuPublicCsr_StagingKey/CSM_E_KEY_EMPTY]  # This function shall copy a key elements from one key to a target key.
          arg keyElementId: type=uint32, direction=IN  # Holds the identifier of the key element which shall be the source for the copy operation.
          arg targetKeyId: type=uint32, direction=IN  # Holds the identifier of the key whose key element shall be the destination element.
          arg targetKeyElementId: type=uint32, direction=IN  # Holds the identifier of the key element which shall be the destination for the copy operation.
        KeyElementCopyPartial: possible-error=[CsmKeyManagement_CsmKey_Ssa_TrustModelEcuPublicCsr_StagingKey/E_NOT_OK, CsmKeyManagement_CsmKey_Ssa_TrustModelEcuPublicCsr_StagingKey/CSM_E_BUSY, CsmKeyManagement_CsmKey_Ssa_TrustModelEcuPublicCsr_StagingKey/CSM_E_KEY_NOT_AVAILABLE, CsmKeyManagement_CsmKey_Ssa_TrustModelEcuPublicCsr_StagingKey/CSM_E_KEY_READ_FAIL, CsmKeyManagement_CsmKey_Ssa_TrustModelEcuPublicCsr_StagingKey/CSM_E_KEY_WRITE_FAIL, CsmKeyManagement_CsmKey_Ssa_TrustModelEcuPublicCsr_StagingKey/CSM_E_KEY_SIZE_MISMATCH, CsmKeyManagement_CsmKey_Ssa_TrustModelEcuPublicCsr_StagingKey/CSM_E_KEY_EMPTY]  # This function shall copy parts of a key element from one key to parts of a target key element of a target key.
          6 x arg, all with type=uint32, direction=IN:
            keyElementId  # Holds the identifier of the key element which shall be the source for the copy operation.
            keyElementSourceOffset  # This is the offset of the source key element indicating the start index of the copy operation.
            keyElementTargetOffset  # This is the offset of the destination key element indicating the start index of the copy operation.
            keyElementCopyLength  # Specifies the number of bytes that shall be copied.
            targetKeyId  # Holds the identifier of the key whose key element shall be the destination element.
            targetKeyElementId  # Holds the identifier of the key element which shall be the destination for the copy operation.
        KeyElementGet: possible-error=[CsmKeyManagement_CsmKey_Ssa_TrustModelEcuPublicCsr_StagingKey/E_NOT_OK, CsmKeyManagement_CsmKey_Ssa_TrustModelEcuPublicCsr_StagingKey/CSM_E_BUSY, CsmKeyManagement_CsmKey_Ssa_TrustModelEcuPublicCsr_StagingKey/CSM_E_SMALL_BUFFER, CsmKeyManagement_CsmKey_Ssa_TrustModelEcuPublicCsr_StagingKey/CSM_E_KEY_READ_FAIL, CsmKeyManagement_CsmKey_Ssa_TrustModelEcuPublicCsr_StagingKey/CSM_E_KEY_NOT_AVAILABLE, CsmKeyManagement_CsmKey_Ssa_TrustModelEcuPublicCsr_StagingKey/CSM_E_KEY_EMPTY]  # Retrieves the key element bytes from a specific key element of the key and stores the key element in the provided buffer.
          arg keyElementId: type=uint32, direction=IN  # Holds the identifier of the key element to be read.
          arg keyPtr: type=Csm_KeyDataType_CsmKey_Ssa_TrustModelEcuPublicCsr_StagingKey, direction=OUT, server-argument-impl-policy=USE-ARRAY-BASE-TYPE  # Holds the data to the key element bytes to be written.
          arg keyLength: type=uint32, direction=INOUT  # Contains the number of key element bytes.
        KeyElementSet: possible-error=[CsmKeyManagement_CsmKey_Ssa_TrustModelEcuPublicCsr_StagingKey/E_NOT_OK, CsmKeyManagement_CsmKey_Ssa_TrustModelEcuPublicCsr_StagingKey/CSM_E_BUSY, CsmKeyManagement_CsmKey_Ssa_TrustModelEcuPublicCsr_StagingKey/CSM_E_KEY_WRITE_FAIL, CsmKeyManagement_CsmKey_Ssa_TrustModelEcuPublicCsr_StagingKey/CSM_E_KEY_NOT_AVAILABLE, CsmKeyManagement_CsmKey_Ssa_TrustModelEcuPublicCsr_StagingKey/CSM_E_KEY_SIZE_MISMATCH]  # Sets the given key element bytes to the key.
          arg keyElementId: type=uint32, direction=IN  # Holds the identifier of the key element to be written.
          arg keyPtr: type=Csm_KeyDataType_CsmKey_Ssa_TrustModelEcuPublicCsr_StagingKey, direction=IN, server-argument-impl-policy=USE-ARRAY-BASE-TYPE  # Holds the data to the key element bytes to be processed.
          arg keyLength: type=uint32, direction=IN  # Contains the number of key element bytes.
        KeyExchangeCalcPubVal: possible-error=[CsmKeyManagement_CsmKey_Ssa_TrustModelEcuPublicCsr_StagingKey/E_NOT_OK, CsmKeyManagement_CsmKey_Ssa_TrustModelEcuPublicCsr_StagingKey/CSM_E_BUSY, CsmKeyManagement_CsmKey_Ssa_TrustModelEcuPublicCsr_StagingKey/CSM_E_SMALL_BUFFER, CsmKeyManagement_CsmKey_Ssa_TrustModelEcuPublicCsr_StagingKey/CSM_E_KEY_EMPTY]  # Calculates the public value of the current user for the key exchange and stores the public key in the provided buffer.
          arg publicValuePtr: type=Csm_PublicValueDataType_CsmKey_Ssa_TrustModelEcuPublicCsr_StagingKey, direction=OUT, server-argument-impl-policy=USE-ARRAY-BASE-TYPE  # Holds a pointer to the memory location in which the public value length in bytes is stored. On calling this function, this parameter shall contain the size of the buffer in bytes provided by publicValuePtr. When the request has finished, the actual length of the returned value shall be stored.
          arg publicValueLengthPtr: type=uint32, direction=INOUT  # Contains the pointer to the data where the public value shall be stored.
        KeyExchangeCalcSecret: possible-error=[CsmKeyManagement_CsmKey_Ssa_TrustModelEcuPublicCsr_StagingKey/E_NOT_OK, CsmKeyManagement_CsmKey_Ssa_TrustModelEcuPublicCsr_StagingKey/CSM_E_BUSY, CsmKeyManagement_CsmKey_Ssa_TrustModelEcuPublicCsr_StagingKey/CSM_E_SMALL_BUFFER, CsmKeyManagement_CsmKey_Ssa_TrustModelEcuPublicCsr_StagingKey/CSM_E_KEY_EMPTY]  # Calculates the shared secret key for the key exchange with the key material of the key identified by the keyId and the partner public key. The shared secret key is stored as a key element in the same key.
          arg partnerPublicValuePtr: type=Csm_PublicValueDataType_CsmKey_Ssa_TrustModelEcuPublicCsr_StagingKey, direction=IN, server-argument-impl-policy=USE-ARRAY-BASE-TYPE  # Holds the pointer to the memory location containing the partner's public value.
          arg partnerPublicValueLength: type=uint32, direction=IN  # Contains the number of bytes of the partner public value.
        KeyGenerate: possible-error=[CsmKeyManagement_CsmKey_Ssa_TrustModelEcuPublicCsr_StagingKey/E_NOT_OK, CsmKeyManagement_CsmKey_Ssa_TrustModelEcuPublicCsr_StagingKey/CSM_E_BUSY, CsmKeyManagement_CsmKey_Ssa_TrustModelEcuPublicCsr_StagingKey/CSM_E_KEY_EMPTY]  # Generates new key material and store it in the key identified by keyId.
        KeySetValid: possible-error=[CsmKeyManagement_CsmKey_Ssa_TrustModelEcuPublicCsr_StagingKey/E_NOT_OK, CsmKeyManagement_CsmKey_Ssa_TrustModelEcuPublicCsr_StagingKey/CSM_E_BUSY]  # Sets the given key element bytes to the key.
        RandomSeed: possible-error=[CsmKeyManagement_CsmKey_Ssa_TrustModelEcuPublicCsr_StagingKey/E_NOT_OK, CsmKeyManagement_CsmKey_Ssa_TrustModelEcuPublicCsr_StagingKey/CSM_E_BUSY]  # Feeds a key element with a random seed.
          arg seedPtr: type=Csm_SeedDataTypeCsmKey_Ssa_TrustModelEcuPublicCsr_StagingKey, direction=IN, server-argument-impl-policy=USE-ARRAY-BASE-TYPE  # Holds the data which shall be used for the random seed initialization.
          arg seedLength: type=uint32, direction=IN  # Contains the length of the seed in bytes.
      8 x error:
        E_NOT_OK: error-code=1  # The service request failed.
        CSM_E_BUSY: error-code=2  # The service request failed because the service is still busy.
        CSM_E_SMALL_BUFFER: error-code=3  # The service request failed because the provided buffer is too small to store the result.
        CSM_E_KEY_READ_FAIL: error-code=6  # The service request failed because read access was denied.
        CSM_E_KEY_WRITE_FAIL: error-code=7  # The service request failed because write access was denied.
        CSM_E_KEY_NOT_AVAILABLE: error-code=8  # The service request failed because the key is not available.
        CSM_E_KEY_SIZE_MISMATCH: error-code=10  # The service request failed because the key element is not partially accessible and the provided key element length is too short or too long for that key element.
        CSM_E_KEY_EMPTY: error-code=13  # The service request failed because of uninitialized source key element.
    CsmKeyManagement_CsmKey_Ssa_TrustModelPrivateEcu_LiveKey  # Interface to execute the key management functions.
      13 x operation:
        CertificateParse: possible-error=[CsmKeyManagement_CsmKey_Ssa_TrustModelPrivateEcu_LiveKey/E_NOT_OK, CsmKeyManagement_CsmKey_Ssa_TrustModelPrivateEcu_LiveKey/CSM_E_BUSY, CsmKeyManagement_CsmKey_Ssa_TrustModelPrivateEcu_LiveKey/CSM_E_KEY_EMPTY]  # This function shall dispatch the certificate parse function to the CRYIF.
        CertificateVerify: possible-error=[CsmKeyManagement_CsmKey_Ssa_TrustModelPrivateEcu_LiveKey/E_NOT_OK, CsmKeyManagement_CsmKey_Ssa_TrustModelPrivateEcu_LiveKey/CSM_E_BUSY, CsmKeyManagement_CsmKey_Ssa_TrustModelPrivateEcu_LiveKey/CSM_E_KEY_EMPTY]  # Verifies the certificate stored in the key referenced by verifyKeyId with the certificate stored in the key referenced by keyId. Note: Only certificates stored in the same Crypto Driver can be verified against each other. If the key element CRYPTO_KE_CERTIFICATE_CURRENT_TIME is used for the verification of the validity period of the certificate indentified by verifyKeyId, it shall have the same format as the timestamp in the certificate.
          arg verifyKeyId: type=uint32, direction=IN  # Holds the identifier of the key containing the certificate to be verified.
          arg verifyPtr: type=Crypto_VerifyResultType, direction=OUT  # Contains the result of the certificate verification.
        KeyCopy: possible-error=[CsmKeyManagement_CsmKey_Ssa_TrustModelPrivateEcu_LiveKey/E_NOT_OK, CsmKeyManagement_CsmKey_Ssa_TrustModelPrivateEcu_LiveKey/CSM_E_BUSY, CsmKeyManagement_CsmKey_Ssa_TrustModelPrivateEcu_LiveKey/CSM_E_SMALL_BUFFER, CsmKeyManagement_CsmKey_Ssa_TrustModelPrivateEcu_LiveKey/CSM_E_KEY_READ_FAIL, CsmKeyManagement_CsmKey_Ssa_TrustModelPrivateEcu_LiveKey/CSM_E_KEY_WRITE_FAIL, CsmKeyManagement_CsmKey_Ssa_TrustModelPrivateEcu_LiveKey/CSM_E_KEY_SIZE_MISMATCH, CsmKeyManagement_CsmKey_Ssa_TrustModelPrivateEcu_LiveKey/CSM_E_KEY_EMPTY]  # This function shall copy all key elements from the source key to a target key.
          arg targetKeyId: type=uint32, direction=IN  # Holds the identifier of the key whose key element shall be the destination element.
        KeyDerive: possible-error=[CsmKeyManagement_CsmKey_Ssa_TrustModelPrivateEcu_LiveKey/E_NOT_OK, CsmKeyManagement_CsmKey_Ssa_TrustModelPrivateEcu_LiveKey/CSM_E_BUSY, CsmKeyManagement_CsmKey_Ssa_TrustModelPrivateEcu_LiveKey/CSM_E_KEY_READ_FAIL, CsmKeyManagement_CsmKey_Ssa_TrustModelPrivateEcu_LiveKey/CSM_E_KEY_WRITE_FAIL, CsmKeyManagement_CsmKey_Ssa_TrustModelPrivateEcu_LiveKey/CSM_E_KEY_SIZE_MISMATCH, CsmKeyManagement_CsmKey_Ssa_TrustModelPrivateEcu_LiveKey/CSM_E_KEY_EMPTY]  # Derives a new key by using the key elements in the given key. The given key contains the key elements for the password and salt. The derived key is stored in the key element with the id 1 of the key identified by targetCryptoKeyId.
          arg targetKeyId: type=uint32, direction=IN  # Holds the identifier of the key which is used to store the derived key.
        KeyElementCopy: possible-error=[CsmKeyManagement_CsmKey_Ssa_TrustModelPrivateEcu_LiveKey/E_NOT_OK, CsmKeyManagement_CsmKey_Ssa_TrustModelPrivateEcu_LiveKey/CSM_E_BUSY, CsmKeyManagement_CsmKey_Ssa_TrustModelPrivateEcu_LiveKey/CSM_E_SMALL_BUFFER, CsmKeyManagement_CsmKey_Ssa_TrustModelPrivateEcu_LiveKey/CSM_E_KEY_READ_FAIL, CsmKeyManagement_CsmKey_Ssa_TrustModelPrivateEcu_LiveKey/CSM_E_KEY_WRITE_FAIL, CsmKeyManagement_CsmKey_Ssa_TrustModelPrivateEcu_LiveKey/CSM_E_KEY_SIZE_MISMATCH, CsmKeyManagement_CsmKey_Ssa_TrustModelPrivateEcu_LiveKey/CSM_E_KEY_EMPTY]  # This function shall copy a key elements from one key to a target key.
          arg keyElementId: type=uint32, direction=IN  # Holds the identifier of the key element which shall be the source for the copy operation.
          arg targetKeyId: type=uint32, direction=IN  # Holds the identifier of the key whose key element shall be the destination element.
          arg targetKeyElementId: type=uint32, direction=IN  # Holds the identifier of the key element which shall be the destination for the copy operation.
        KeyElementCopyPartial: possible-error=[CsmKeyManagement_CsmKey_Ssa_TrustModelPrivateEcu_LiveKey/E_NOT_OK, CsmKeyManagement_CsmKey_Ssa_TrustModelPrivateEcu_LiveKey/CSM_E_BUSY, CsmKeyManagement_CsmKey_Ssa_TrustModelPrivateEcu_LiveKey/CSM_E_KEY_NOT_AVAILABLE, CsmKeyManagement_CsmKey_Ssa_TrustModelPrivateEcu_LiveKey/CSM_E_KEY_READ_FAIL, CsmKeyManagement_CsmKey_Ssa_TrustModelPrivateEcu_LiveKey/CSM_E_KEY_WRITE_FAIL, CsmKeyManagement_CsmKey_Ssa_TrustModelPrivateEcu_LiveKey/CSM_E_KEY_SIZE_MISMATCH, CsmKeyManagement_CsmKey_Ssa_TrustModelPrivateEcu_LiveKey/CSM_E_KEY_EMPTY]  # This function shall copy parts of a key element from one key to parts of a target key element of a target key.
          6 x arg, all with type=uint32, direction=IN:
            keyElementId  # Holds the identifier of the key element which shall be the source for the copy operation.
            keyElementSourceOffset  # This is the offset of the source key element indicating the start index of the copy operation.
            keyElementTargetOffset  # This is the offset of the destination key element indicating the start index of the copy operation.
            keyElementCopyLength  # Specifies the number of bytes that shall be copied.
            targetKeyId  # Holds the identifier of the key whose key element shall be the destination element.
            targetKeyElementId  # Holds the identifier of the key element which shall be the destination for the copy operation.
        KeyElementGet: possible-error=[CsmKeyManagement_CsmKey_Ssa_TrustModelPrivateEcu_LiveKey/E_NOT_OK, CsmKeyManagement_CsmKey_Ssa_TrustModelPrivateEcu_LiveKey/CSM_E_BUSY, CsmKeyManagement_CsmKey_Ssa_TrustModelPrivateEcu_LiveKey/CSM_E_SMALL_BUFFER, CsmKeyManagement_CsmKey_Ssa_TrustModelPrivateEcu_LiveKey/CSM_E_KEY_READ_FAIL, CsmKeyManagement_CsmKey_Ssa_TrustModelPrivateEcu_LiveKey/CSM_E_KEY_NOT_AVAILABLE, CsmKeyManagement_CsmKey_Ssa_TrustModelPrivateEcu_LiveKey/CSM_E_KEY_EMPTY]  # Retrieves the key element bytes from a specific key element of the key and stores the key element in the provided buffer.
          arg keyElementId: type=uint32, direction=IN  # Holds the identifier of the key element to be read.
          arg keyPtr: type=Csm_KeyDataType_CsmKey_Ssa_TrustModelPrivateEcu_LiveKey, direction=OUT, server-argument-impl-policy=USE-ARRAY-BASE-TYPE  # Holds the data to the key element bytes to be written.
          arg keyLength: type=uint32, direction=INOUT  # Contains the number of key element bytes.
        KeyElementSet: possible-error=[CsmKeyManagement_CsmKey_Ssa_TrustModelPrivateEcu_LiveKey/E_NOT_OK, CsmKeyManagement_CsmKey_Ssa_TrustModelPrivateEcu_LiveKey/CSM_E_BUSY, CsmKeyManagement_CsmKey_Ssa_TrustModelPrivateEcu_LiveKey/CSM_E_KEY_WRITE_FAIL, CsmKeyManagement_CsmKey_Ssa_TrustModelPrivateEcu_LiveKey/CSM_E_KEY_NOT_AVAILABLE, CsmKeyManagement_CsmKey_Ssa_TrustModelPrivateEcu_LiveKey/CSM_E_KEY_SIZE_MISMATCH]  # Sets the given key element bytes to the key.
          arg keyElementId: type=uint32, direction=IN  # Holds the identifier of the key element to be written.
          arg keyPtr: type=Csm_KeyDataType_CsmKey_Ssa_TrustModelPrivateEcu_LiveKey, direction=IN, server-argument-impl-policy=USE-ARRAY-BASE-TYPE  # Holds the data to the key element bytes to be processed.
          arg keyLength: type=uint32, direction=IN  # Contains the number of key element bytes.
        KeyExchangeCalcPubVal: possible-error=[CsmKeyManagement_CsmKey_Ssa_TrustModelPrivateEcu_LiveKey/E_NOT_OK, CsmKeyManagement_CsmKey_Ssa_TrustModelPrivateEcu_LiveKey/CSM_E_BUSY, CsmKeyManagement_CsmKey_Ssa_TrustModelPrivateEcu_LiveKey/CSM_E_SMALL_BUFFER, CsmKeyManagement_CsmKey_Ssa_TrustModelPrivateEcu_LiveKey/CSM_E_KEY_EMPTY]  # Calculates the public value of the current user for the key exchange and stores the public key in the provided buffer.
          arg publicValuePtr: type=Csm_PublicValueDataType_CsmKey_Ssa_TrustModelPrivateEcu_LiveKey, direction=OUT, server-argument-impl-policy=USE-ARRAY-BASE-TYPE  # Holds a pointer to the memory location in which the public value length in bytes is stored. On calling this function, this parameter shall contain the size of the buffer in bytes provided by publicValuePtr. When the request has finished, the actual length of the returned value shall be stored.
          arg publicValueLengthPtr: type=uint32, direction=INOUT  # Contains the pointer to the data where the public value shall be stored.
        KeyExchangeCalcSecret: possible-error=[CsmKeyManagement_CsmKey_Ssa_TrustModelPrivateEcu_LiveKey/E_NOT_OK, CsmKeyManagement_CsmKey_Ssa_TrustModelPrivateEcu_LiveKey/CSM_E_BUSY, CsmKeyManagement_CsmKey_Ssa_TrustModelPrivateEcu_LiveKey/CSM_E_SMALL_BUFFER, CsmKeyManagement_CsmKey_Ssa_TrustModelPrivateEcu_LiveKey/CSM_E_KEY_EMPTY]  # Calculates the shared secret key for the key exchange with the key material of the key identified by the keyId and the partner public key. The shared secret key is stored as a key element in the same key.
          arg partnerPublicValuePtr: type=Csm_PublicValueDataType_CsmKey_Ssa_TrustModelPrivateEcu_LiveKey, direction=IN, server-argument-impl-policy=USE-ARRAY-BASE-TYPE  # Holds the pointer to the memory location containing the partner's public value.
          arg partnerPublicValueLength: type=uint32, direction=IN  # Contains the number of bytes of the partner public value.
        KeyGenerate: possible-error=[CsmKeyManagement_CsmKey_Ssa_TrustModelPrivateEcu_LiveKey/E_NOT_OK, CsmKeyManagement_CsmKey_Ssa_TrustModelPrivateEcu_LiveKey/CSM_E_BUSY, CsmKeyManagement_CsmKey_Ssa_TrustModelPrivateEcu_LiveKey/CSM_E_KEY_EMPTY]  # Generates new key material and store it in the key identified by keyId.
        KeySetValid: possible-error=[CsmKeyManagement_CsmKey_Ssa_TrustModelPrivateEcu_LiveKey/E_NOT_OK, CsmKeyManagement_CsmKey_Ssa_TrustModelPrivateEcu_LiveKey/CSM_E_BUSY]  # Sets the given key element bytes to the key.
        RandomSeed: possible-error=[CsmKeyManagement_CsmKey_Ssa_TrustModelPrivateEcu_LiveKey/E_NOT_OK, CsmKeyManagement_CsmKey_Ssa_TrustModelPrivateEcu_LiveKey/CSM_E_BUSY]  # Feeds a key element with a random seed.
          arg seedPtr: type=Csm_SeedDataTypeCsmKey_Ssa_TrustModelPrivateEcu_LiveKey, direction=IN, server-argument-impl-policy=USE-ARRAY-BASE-TYPE  # Holds the data which shall be used for the random seed initialization.
          arg seedLength: type=uint32, direction=IN  # Contains the length of the seed in bytes.
      8 x error:
        E_NOT_OK: error-code=1  # The service request failed.
        CSM_E_BUSY: error-code=2  # The service request failed because the service is still busy.
        CSM_E_SMALL_BUFFER: error-code=3  # The service request failed because the provided buffer is too small to store the result.
        CSM_E_KEY_READ_FAIL: error-code=6  # The service request failed because read access was denied.
        CSM_E_KEY_WRITE_FAIL: error-code=7  # The service request failed because write access was denied.
        CSM_E_KEY_NOT_AVAILABLE: error-code=8  # The service request failed because the key is not available.
        CSM_E_KEY_SIZE_MISMATCH: error-code=10  # The service request failed because the key element is not partially accessible and the provided key element length is too short or too long for that key element.
        CSM_E_KEY_EMPTY: error-code=13  # The service request failed because of uninitialized source key element.
    CsmKeyManagement_CsmKey_Ssa_TrustModel_Ecu_CsrPrivateKey  # Interface to execute the key management functions.
      13 x operation:
        CertificateParse: possible-error=[CsmKeyManagement_CsmKey_Ssa_TrustModel_Ecu_CsrPrivateKey/E_NOT_OK, CsmKeyManagement_CsmKey_Ssa_TrustModel_Ecu_CsrPrivateKey/CSM_E_BUSY, CsmKeyManagement_CsmKey_Ssa_TrustModel_Ecu_CsrPrivateKey/CSM_E_KEY_EMPTY]  # This function shall dispatch the certificate parse function to the CRYIF.
        CertificateVerify: possible-error=[CsmKeyManagement_CsmKey_Ssa_TrustModel_Ecu_CsrPrivateKey/E_NOT_OK, CsmKeyManagement_CsmKey_Ssa_TrustModel_Ecu_CsrPrivateKey/CSM_E_BUSY, CsmKeyManagement_CsmKey_Ssa_TrustModel_Ecu_CsrPrivateKey/CSM_E_KEY_EMPTY]  # Verifies the certificate stored in the key referenced by verifyKeyId with the certificate stored in the key referenced by keyId. Note: Only certificates stored in the same Crypto Driver can be verified against each other. If the key element CRYPTO_KE_CERTIFICATE_CURRENT_TIME is used for the verification of the validity period of the certificate indentified by verifyKeyId, it shall have the same format as the timestamp in the certificate.
          arg verifyKeyId: type=uint32, direction=IN  # Holds the identifier of the key containing the certificate to be verified.
          arg verifyPtr: type=Crypto_VerifyResultType, direction=OUT  # Contains the result of the certificate verification.
        KeyCopy: possible-error=[CsmKeyManagement_CsmKey_Ssa_TrustModel_Ecu_CsrPrivateKey/E_NOT_OK, CsmKeyManagement_CsmKey_Ssa_TrustModel_Ecu_CsrPrivateKey/CSM_E_BUSY, CsmKeyManagement_CsmKey_Ssa_TrustModel_Ecu_CsrPrivateKey/CSM_E_SMALL_BUFFER, CsmKeyManagement_CsmKey_Ssa_TrustModel_Ecu_CsrPrivateKey/CSM_E_KEY_READ_FAIL, CsmKeyManagement_CsmKey_Ssa_TrustModel_Ecu_CsrPrivateKey/CSM_E_KEY_WRITE_FAIL, CsmKeyManagement_CsmKey_Ssa_TrustModel_Ecu_CsrPrivateKey/CSM_E_KEY_SIZE_MISMATCH, CsmKeyManagement_CsmKey_Ssa_TrustModel_Ecu_CsrPrivateKey/CSM_E_KEY_EMPTY]  # This function shall copy all key elements from the source key to a target key.
          arg targetKeyId: type=uint32, direction=IN  # Holds the identifier of the key whose key element shall be the destination element.
        KeyDerive: possible-error=[CsmKeyManagement_CsmKey_Ssa_TrustModel_Ecu_CsrPrivateKey/E_NOT_OK, CsmKeyManagement_CsmKey_Ssa_TrustModel_Ecu_CsrPrivateKey/CSM_E_BUSY, CsmKeyManagement_CsmKey_Ssa_TrustModel_Ecu_CsrPrivateKey/CSM_E_KEY_READ_FAIL, CsmKeyManagement_CsmKey_Ssa_TrustModel_Ecu_CsrPrivateKey/CSM_E_KEY_WRITE_FAIL, CsmKeyManagement_CsmKey_Ssa_TrustModel_Ecu_CsrPrivateKey/CSM_E_KEY_SIZE_MISMATCH, CsmKeyManagement_CsmKey_Ssa_TrustModel_Ecu_CsrPrivateKey/CSM_E_KEY_EMPTY]  # Derives a new key by using the key elements in the given key. The given key contains the key elements for the password and salt. The derived key is stored in the key element with the id 1 of the key identified by targetCryptoKeyId.
          arg targetKeyId: type=uint32, direction=IN  # Holds the identifier of the key which is used to store the derived key.
        KeyElementCopy: possible-error=[CsmKeyManagement_CsmKey_Ssa_TrustModel_Ecu_CsrPrivateKey/E_NOT_OK, CsmKeyManagement_CsmKey_Ssa_TrustModel_Ecu_CsrPrivateKey/CSM_E_BUSY, CsmKeyManagement_CsmKey_Ssa_TrustModel_Ecu_CsrPrivateKey/CSM_E_SMALL_BUFFER, CsmKeyManagement_CsmKey_Ssa_TrustModel_Ecu_CsrPrivateKey/CSM_E_KEY_READ_FAIL, CsmKeyManagement_CsmKey_Ssa_TrustModel_Ecu_CsrPrivateKey/CSM_E_KEY_WRITE_FAIL, CsmKeyManagement_CsmKey_Ssa_TrustModel_Ecu_CsrPrivateKey/CSM_E_KEY_SIZE_MISMATCH, CsmKeyManagement_CsmKey_Ssa_TrustModel_Ecu_CsrPrivateKey/CSM_E_KEY_EMPTY]  # This function shall copy a key elements from one key to a target key.
          arg keyElementId: type=uint32, direction=IN  # Holds the identifier of the key element which shall be the source for the copy operation.
          arg targetKeyId: type=uint32, direction=IN  # Holds the identifier of the key whose key element shall be the destination element.
          arg targetKeyElementId: type=uint32, direction=IN  # Holds the identifier of the key element which shall be the destination for the copy operation.
        KeyElementCopyPartial: possible-error=[CsmKeyManagement_CsmKey_Ssa_TrustModel_Ecu_CsrPrivateKey/E_NOT_OK, CsmKeyManagement_CsmKey_Ssa_TrustModel_Ecu_CsrPrivateKey/CSM_E_BUSY, CsmKeyManagement_CsmKey_Ssa_TrustModel_Ecu_CsrPrivateKey/CSM_E_KEY_NOT_AVAILABLE, CsmKeyManagement_CsmKey_Ssa_TrustModel_Ecu_CsrPrivateKey/CSM_E_KEY_READ_FAIL, CsmKeyManagement_CsmKey_Ssa_TrustModel_Ecu_CsrPrivateKey/CSM_E_KEY_WRITE_FAIL, CsmKeyManagement_CsmKey_Ssa_TrustModel_Ecu_CsrPrivateKey/CSM_E_KEY_SIZE_MISMATCH, CsmKeyManagement_CsmKey_Ssa_TrustModel_Ecu_CsrPrivateKey/CSM_E_KEY_EMPTY]  # This function shall copy parts of a key element from one key to parts of a target key element of a target key.
          6 x arg, all with type=uint32, direction=IN:
            keyElementId  # Holds the identifier of the key element which shall be the source for the copy operation.
            keyElementSourceOffset  # This is the offset of the source key element indicating the start index of the copy operation.
            keyElementTargetOffset  # This is the offset of the destination key element indicating the start index of the copy operation.
            keyElementCopyLength  # Specifies the number of bytes that shall be copied.
            targetKeyId  # Holds the identifier of the key whose key element shall be the destination element.
            targetKeyElementId  # Holds the identifier of the key element which shall be the destination for the copy operation.
        KeyElementGet: possible-error=[CsmKeyManagement_CsmKey_Ssa_TrustModel_Ecu_CsrPrivateKey/E_NOT_OK, CsmKeyManagement_CsmKey_Ssa_TrustModel_Ecu_CsrPrivateKey/CSM_E_BUSY, CsmKeyManagement_CsmKey_Ssa_TrustModel_Ecu_CsrPrivateKey/CSM_E_SMALL_BUFFER, CsmKeyManagement_CsmKey_Ssa_TrustModel_Ecu_CsrPrivateKey/CSM_E_KEY_READ_FAIL, CsmKeyManagement_CsmKey_Ssa_TrustModel_Ecu_CsrPrivateKey/CSM_E_KEY_NOT_AVAILABLE, CsmKeyManagement_CsmKey_Ssa_TrustModel_Ecu_CsrPrivateKey/CSM_E_KEY_EMPTY]  # Retrieves the key element bytes from a specific key element of the key and stores the key element in the provided buffer.
          arg keyElementId: type=uint32, direction=IN  # Holds the identifier of the key element to be read.
          arg keyPtr: type=Csm_KeyDataType_CsmKey_Ssa_TrustModel_Ecu_CsrPrivateKey, direction=OUT, server-argument-impl-policy=USE-ARRAY-BASE-TYPE  # Holds the data to the key element bytes to be written.
          arg keyLength: type=uint32, direction=INOUT  # Contains the number of key element bytes.
        KeyElementSet: possible-error=[CsmKeyManagement_CsmKey_Ssa_TrustModel_Ecu_CsrPrivateKey/E_NOT_OK, CsmKeyManagement_CsmKey_Ssa_TrustModel_Ecu_CsrPrivateKey/CSM_E_BUSY, CsmKeyManagement_CsmKey_Ssa_TrustModel_Ecu_CsrPrivateKey/CSM_E_KEY_WRITE_FAIL, CsmKeyManagement_CsmKey_Ssa_TrustModel_Ecu_CsrPrivateKey/CSM_E_KEY_NOT_AVAILABLE, CsmKeyManagement_CsmKey_Ssa_TrustModel_Ecu_CsrPrivateKey/CSM_E_KEY_SIZE_MISMATCH]  # Sets the given key element bytes to the key.
          arg keyElementId: type=uint32, direction=IN  # Holds the identifier of the key element to be written.
          arg keyPtr: type=Csm_KeyDataType_CsmKey_Ssa_TrustModel_Ecu_CsrPrivateKey, direction=IN, server-argument-impl-policy=USE-ARRAY-BASE-TYPE  # Holds the data to the key element bytes to be processed.
          arg keyLength: type=uint32, direction=IN  # Contains the number of key element bytes.
        KeyExchangeCalcPubVal: possible-error=[CsmKeyManagement_CsmKey_Ssa_TrustModel_Ecu_CsrPrivateKey/E_NOT_OK, CsmKeyManagement_CsmKey_Ssa_TrustModel_Ecu_CsrPrivateKey/CSM_E_BUSY, CsmKeyManagement_CsmKey_Ssa_TrustModel_Ecu_CsrPrivateKey/CSM_E_SMALL_BUFFER, CsmKeyManagement_CsmKey_Ssa_TrustModel_Ecu_CsrPrivateKey/CSM_E_KEY_EMPTY]  # Calculates the public value of the current user for the key exchange and stores the public key in the provided buffer.
          arg publicValuePtr: type=Csm_PublicValueDataType_CsmKey_Ssa_TrustModel_Ecu_CsrPrivateKey, direction=OUT, server-argument-impl-policy=USE-ARRAY-BASE-TYPE  # Holds a pointer to the memory location in which the public value length in bytes is stored. On calling this function, this parameter shall contain the size of the buffer in bytes provided by publicValuePtr. When the request has finished, the actual length of the returned value shall be stored.
          arg publicValueLengthPtr: type=uint32, direction=INOUT  # Contains the pointer to the data where the public value shall be stored.
        KeyExchangeCalcSecret: possible-error=[CsmKeyManagement_CsmKey_Ssa_TrustModel_Ecu_CsrPrivateKey/E_NOT_OK, CsmKeyManagement_CsmKey_Ssa_TrustModel_Ecu_CsrPrivateKey/CSM_E_BUSY, CsmKeyManagement_CsmKey_Ssa_TrustModel_Ecu_CsrPrivateKey/CSM_E_SMALL_BUFFER, CsmKeyManagement_CsmKey_Ssa_TrustModel_Ecu_CsrPrivateKey/CSM_E_KEY_EMPTY]  # Calculates the shared secret key for the key exchange with the key material of the key identified by the keyId and the partner public key. The shared secret key is stored as a key element in the same key.
          arg partnerPublicValuePtr: type=Csm_PublicValueDataType_CsmKey_Ssa_TrustModel_Ecu_CsrPrivateKey, direction=IN, server-argument-impl-policy=USE-ARRAY-BASE-TYPE  # Holds the pointer to the memory location containing the partner's public value.
          arg partnerPublicValueLength: type=uint32, direction=IN  # Contains the number of bytes of the partner public value.
        KeyGenerate: possible-error=[CsmKeyManagement_CsmKey_Ssa_TrustModel_Ecu_CsrPrivateKey/E_NOT_OK, CsmKeyManagement_CsmKey_Ssa_TrustModel_Ecu_CsrPrivateKey/CSM_E_BUSY, CsmKeyManagement_CsmKey_Ssa_TrustModel_Ecu_CsrPrivateKey/CSM_E_KEY_EMPTY]  # Generates new key material and store it in the key identified by keyId.
        KeySetValid: possible-error=[CsmKeyManagement_CsmKey_Ssa_TrustModel_Ecu_CsrPrivateKey/E_NOT_OK, CsmKeyManagement_CsmKey_Ssa_TrustModel_Ecu_CsrPrivateKey/CSM_E_BUSY]  # Sets the given key element bytes to the key.
        RandomSeed: possible-error=[CsmKeyManagement_CsmKey_Ssa_TrustModel_Ecu_CsrPrivateKey/E_NOT_OK, CsmKeyManagement_CsmKey_Ssa_TrustModel_Ecu_CsrPrivateKey/CSM_E_BUSY]  # Feeds a key element with a random seed.
          arg seedPtr: type=Csm_SeedDataTypeCsmKey_Ssa_TrustModel_Ecu_CsrPrivateKey, direction=IN, server-argument-impl-policy=USE-ARRAY-BASE-TYPE  # Holds the data which shall be used for the random seed initialization.
          arg seedLength: type=uint32, direction=IN  # Contains the length of the seed in bytes.
      8 x error:
        E_NOT_OK: error-code=1  # The service request failed.
        CSM_E_BUSY: error-code=2  # The service request failed because the service is still busy.
        CSM_E_SMALL_BUFFER: error-code=3  # The service request failed because the provided buffer is too small to store the result.
        CSM_E_KEY_READ_FAIL: error-code=6  # The service request failed because read access was denied.
        CSM_E_KEY_WRITE_FAIL: error-code=7  # The service request failed because write access was denied.
        CSM_E_KEY_NOT_AVAILABLE: error-code=8  # The service request failed because the key is not available.
        CSM_E_KEY_SIZE_MISMATCH: error-code=10  # The service request failed because the key element is not partially accessible and the provided key element length is too short or too long for that key element.
        CSM_E_KEY_EMPTY: error-code=13  # The service request failed because of uninitialized source key element.
    CsmKeyManagement_CsmKey_Ssa_TrustModel_Ecu_CsrPublicKey  # Interface to execute the key management functions.
      13 x operation:
        CertificateParse: possible-error=[CsmKeyManagement_CsmKey_Ssa_TrustModel_Ecu_CsrPublicKey/E_NOT_OK, CsmKeyManagement_CsmKey_Ssa_TrustModel_Ecu_CsrPublicKey/CSM_E_BUSY, CsmKeyManagement_CsmKey_Ssa_TrustModel_Ecu_CsrPublicKey/CSM_E_KEY_EMPTY]  # This function shall dispatch the certificate parse function to the CRYIF.
        CertificateVerify: possible-error=[CsmKeyManagement_CsmKey_Ssa_TrustModel_Ecu_CsrPublicKey/E_NOT_OK, CsmKeyManagement_CsmKey_Ssa_TrustModel_Ecu_CsrPublicKey/CSM_E_BUSY, CsmKeyManagement_CsmKey_Ssa_TrustModel_Ecu_CsrPublicKey/CSM_E_KEY_EMPTY]  # Verifies the certificate stored in the key referenced by verifyKeyId with the certificate stored in the key referenced by keyId. Note: Only certificates stored in the same Crypto Driver can be verified against each other. If the key element CRYPTO_KE_CERTIFICATE_CURRENT_TIME is used for the verification of the validity period of the certificate indentified by verifyKeyId, it shall have the same format as the timestamp in the certificate.
          arg verifyKeyId: type=uint32, direction=IN  # Holds the identifier of the key containing the certificate to be verified.
          arg verifyPtr: type=Crypto_VerifyResultType, direction=OUT  # Contains the result of the certificate verification.
        KeyCopy: possible-error=[CsmKeyManagement_CsmKey_Ssa_TrustModel_Ecu_CsrPublicKey/E_NOT_OK, CsmKeyManagement_CsmKey_Ssa_TrustModel_Ecu_CsrPublicKey/CSM_E_BUSY, CsmKeyManagement_CsmKey_Ssa_TrustModel_Ecu_CsrPublicKey/CSM_E_SMALL_BUFFER, CsmKeyManagement_CsmKey_Ssa_TrustModel_Ecu_CsrPublicKey/CSM_E_KEY_READ_FAIL, CsmKeyManagement_CsmKey_Ssa_TrustModel_Ecu_CsrPublicKey/CSM_E_KEY_WRITE_FAIL, CsmKeyManagement_CsmKey_Ssa_TrustModel_Ecu_CsrPublicKey/CSM_E_KEY_SIZE_MISMATCH, CsmKeyManagement_CsmKey_Ssa_TrustModel_Ecu_CsrPublicKey/CSM_E_KEY_EMPTY]  # This function shall copy all key elements from the source key to a target key.
          arg targetKeyId: type=uint32, direction=IN  # Holds the identifier of the key whose key element shall be the destination element.
        KeyDerive: possible-error=[CsmKeyManagement_CsmKey_Ssa_TrustModel_Ecu_CsrPublicKey/E_NOT_OK, CsmKeyManagement_CsmKey_Ssa_TrustModel_Ecu_CsrPublicKey/CSM_E_BUSY, CsmKeyManagement_CsmKey_Ssa_TrustModel_Ecu_CsrPublicKey/CSM_E_KEY_READ_FAIL, CsmKeyManagement_CsmKey_Ssa_TrustModel_Ecu_CsrPublicKey/CSM_E_KEY_WRITE_FAIL, CsmKeyManagement_CsmKey_Ssa_TrustModel_Ecu_CsrPublicKey/CSM_E_KEY_SIZE_MISMATCH, CsmKeyManagement_CsmKey_Ssa_TrustModel_Ecu_CsrPublicKey/CSM_E_KEY_EMPTY]  # Derives a new key by using the key elements in the given key. The given key contains the key elements for the password and salt. The derived key is stored in the key element with the id 1 of the key identified by targetCryptoKeyId.
          arg targetKeyId: type=uint32, direction=IN  # Holds the identifier of the key which is used to store the derived key.
        KeyElementCopy: possible-error=[CsmKeyManagement_CsmKey_Ssa_TrustModel_Ecu_CsrPublicKey/E_NOT_OK, CsmKeyManagement_CsmKey_Ssa_TrustModel_Ecu_CsrPublicKey/CSM_E_BUSY, CsmKeyManagement_CsmKey_Ssa_TrustModel_Ecu_CsrPublicKey/CSM_E_SMALL_BUFFER, CsmKeyManagement_CsmKey_Ssa_TrustModel_Ecu_CsrPublicKey/CSM_E_KEY_READ_FAIL, CsmKeyManagement_CsmKey_Ssa_TrustModel_Ecu_CsrPublicKey/CSM_E_KEY_WRITE_FAIL, CsmKeyManagement_CsmKey_Ssa_TrustModel_Ecu_CsrPublicKey/CSM_E_KEY_SIZE_MISMATCH, CsmKeyManagement_CsmKey_Ssa_TrustModel_Ecu_CsrPublicKey/CSM_E_KEY_EMPTY]  # This function shall copy a key elements from one key to a target key.
          arg keyElementId: type=uint32, direction=IN  # Holds the identifier of the key element which shall be the source for the copy operation.
          arg targetKeyId: type=uint32, direction=IN  # Holds the identifier of the key whose key element shall be the destination element.
          arg targetKeyElementId: type=uint32, direction=IN  # Holds the identifier of the key element which shall be the destination for the copy operation.
        KeyElementCopyPartial: possible-error=[CsmKeyManagement_CsmKey_Ssa_TrustModel_Ecu_CsrPublicKey/E_NOT_OK, CsmKeyManagement_CsmKey_Ssa_TrustModel_Ecu_CsrPublicKey/CSM_E_BUSY, CsmKeyManagement_CsmKey_Ssa_TrustModel_Ecu_CsrPublicKey/CSM_E_KEY_NOT_AVAILABLE, CsmKeyManagement_CsmKey_Ssa_TrustModel_Ecu_CsrPublicKey/CSM_E_KEY_READ_FAIL, CsmKeyManagement_CsmKey_Ssa_TrustModel_Ecu_CsrPublicKey/CSM_E_KEY_WRITE_FAIL, CsmKeyManagement_CsmKey_Ssa_TrustModel_Ecu_CsrPublicKey/CSM_E_KEY_SIZE_MISMATCH, CsmKeyManagement_CsmKey_Ssa_TrustModel_Ecu_CsrPublicKey/CSM_E_KEY_EMPTY]  # This function shall copy parts of a key element from one key to parts of a target key element of a target key.
          6 x arg, all with type=uint32, direction=IN:
            keyElementId  # Holds the identifier of the key element which shall be the source for the copy operation.
            keyElementSourceOffset  # This is the offset of the source key element indicating the start index of the copy operation.
            keyElementTargetOffset  # This is the offset of the destination key element indicating the start index of the copy operation.
            keyElementCopyLength  # Specifies the number of bytes that shall be copied.
            targetKeyId  # Holds the identifier of the key whose key element shall be the destination element.
            targetKeyElementId  # Holds the identifier of the key element which shall be the destination for the copy operation.
        KeyElementGet: possible-error=[CsmKeyManagement_CsmKey_Ssa_TrustModel_Ecu_CsrPublicKey/E_NOT_OK, CsmKeyManagement_CsmKey_Ssa_TrustModel_Ecu_CsrPublicKey/CSM_E_BUSY, CsmKeyManagement_CsmKey_Ssa_TrustModel_Ecu_CsrPublicKey/CSM_E_SMALL_BUFFER, CsmKeyManagement_CsmKey_Ssa_TrustModel_Ecu_CsrPublicKey/CSM_E_KEY_READ_FAIL, CsmKeyManagement_CsmKey_Ssa_TrustModel_Ecu_CsrPublicKey/CSM_E_KEY_NOT_AVAILABLE, CsmKeyManagement_CsmKey_Ssa_TrustModel_Ecu_CsrPublicKey/CSM_E_KEY_EMPTY]  # Retrieves the key element bytes from a specific key element of the key and stores the key element in the provided buffer.
          arg keyElementId: type=uint32, direction=IN  # Holds the identifier of the key element to be read.
          arg keyPtr: type=Csm_KeyDataType_CsmKey_Ssa_TrustModel_Ecu_CsrPublicKey, direction=OUT, server-argument-impl-policy=USE-ARRAY-BASE-TYPE  # Holds the data to the key element bytes to be written.
          arg keyLength: type=uint32, direction=INOUT  # Contains the number of key element bytes.
        KeyElementSet: possible-error=[CsmKeyManagement_CsmKey_Ssa_TrustModel_Ecu_CsrPublicKey/E_NOT_OK, CsmKeyManagement_CsmKey_Ssa_TrustModel_Ecu_CsrPublicKey/CSM_E_BUSY, CsmKeyManagement_CsmKey_Ssa_TrustModel_Ecu_CsrPublicKey/CSM_E_KEY_WRITE_FAIL, CsmKeyManagement_CsmKey_Ssa_TrustModel_Ecu_CsrPublicKey/CSM_E_KEY_NOT_AVAILABLE, CsmKeyManagement_CsmKey_Ssa_TrustModel_Ecu_CsrPublicKey/CSM_E_KEY_SIZE_MISMATCH]  # Sets the given key element bytes to the key.
          arg keyElementId: type=uint32, direction=IN  # Holds the identifier of the key element to be written.
          arg keyPtr: type=Csm_KeyDataType_CsmKey_Ssa_TrustModel_Ecu_CsrPublicKey, direction=IN, server-argument-impl-policy=USE-ARRAY-BASE-TYPE  # Holds the data to the key element bytes to be processed.
          arg keyLength: type=uint32, direction=IN  # Contains the number of key element bytes.
        KeyExchangeCalcPubVal: possible-error=[CsmKeyManagement_CsmKey_Ssa_TrustModel_Ecu_CsrPublicKey/E_NOT_OK, CsmKeyManagement_CsmKey_Ssa_TrustModel_Ecu_CsrPublicKey/CSM_E_BUSY, CsmKeyManagement_CsmKey_Ssa_TrustModel_Ecu_CsrPublicKey/CSM_E_SMALL_BUFFER, CsmKeyManagement_CsmKey_Ssa_TrustModel_Ecu_CsrPublicKey/CSM_E_KEY_EMPTY]  # Calculates the public value of the current user for the key exchange and stores the public key in the provided buffer.
          arg publicValuePtr: type=Csm_PublicValueDataType_CsmKey_Ssa_TrustModel_Ecu_CsrPublicKey, direction=OUT, server-argument-impl-policy=USE-ARRAY-BASE-TYPE  # Holds a pointer to the memory location in which the public value length in bytes is stored. On calling this function, this parameter shall contain the size of the buffer in bytes provided by publicValuePtr. When the request has finished, the actual length of the returned value shall be stored.
          arg publicValueLengthPtr: type=uint32, direction=INOUT  # Contains the pointer to the data where the public value shall be stored.
        KeyExchangeCalcSecret: possible-error=[CsmKeyManagement_CsmKey_Ssa_TrustModel_Ecu_CsrPublicKey/E_NOT_OK, CsmKeyManagement_CsmKey_Ssa_TrustModel_Ecu_CsrPublicKey/CSM_E_BUSY, CsmKeyManagement_CsmKey_Ssa_TrustModel_Ecu_CsrPublicKey/CSM_E_SMALL_BUFFER, CsmKeyManagement_CsmKey_Ssa_TrustModel_Ecu_CsrPublicKey/CSM_E_KEY_EMPTY]  # Calculates the shared secret key for the key exchange with the key material of the key identified by the keyId and the partner public key. The shared secret key is stored as a key element in the same key.
          arg partnerPublicValuePtr: type=Csm_PublicValueDataType_CsmKey_Ssa_TrustModel_Ecu_CsrPublicKey, direction=IN, server-argument-impl-policy=USE-ARRAY-BASE-TYPE  # Holds the pointer to the memory location containing the partner's public value.
          arg partnerPublicValueLength: type=uint32, direction=IN  # Contains the number of bytes of the partner public value.
        KeyGenerate: possible-error=[CsmKeyManagement_CsmKey_Ssa_TrustModel_Ecu_CsrPublicKey/E_NOT_OK, CsmKeyManagement_CsmKey_Ssa_TrustModel_Ecu_CsrPublicKey/CSM_E_BUSY, CsmKeyManagement_CsmKey_Ssa_TrustModel_Ecu_CsrPublicKey/CSM_E_KEY_EMPTY]  # Generates new key material and store it in the key identified by keyId.
        KeySetValid: possible-error=[CsmKeyManagement_CsmKey_Ssa_TrustModel_Ecu_CsrPublicKey/E_NOT_OK, CsmKeyManagement_CsmKey_Ssa_TrustModel_Ecu_CsrPublicKey/CSM_E_BUSY]  # Sets the given key element bytes to the key.
        RandomSeed: possible-error=[CsmKeyManagement_CsmKey_Ssa_TrustModel_Ecu_CsrPublicKey/E_NOT_OK, CsmKeyManagement_CsmKey_Ssa_TrustModel_Ecu_CsrPublicKey/CSM_E_BUSY]  # Feeds a key element with a random seed.
          arg seedPtr: type=Csm_SeedDataTypeCsmKey_Ssa_TrustModel_Ecu_CsrPublicKey, direction=IN, server-argument-impl-policy=USE-ARRAY-BASE-TYPE  # Holds the data which shall be used for the random seed initialization.
          arg seedLength: type=uint32, direction=IN  # Contains the length of the seed in bytes.
      8 x error:
        E_NOT_OK: error-code=1  # The service request failed.
        CSM_E_BUSY: error-code=2  # The service request failed because the service is still busy.
        CSM_E_SMALL_BUFFER: error-code=3  # The service request failed because the provided buffer is too small to store the result.
        CSM_E_KEY_READ_FAIL: error-code=6  # The service request failed because read access was denied.
        CSM_E_KEY_WRITE_FAIL: error-code=7  # The service request failed because write access was denied.
        CSM_E_KEY_NOT_AVAILABLE: error-code=8  # The service request failed because the key is not available.
        CSM_E_KEY_SIZE_MISMATCH: error-code=10  # The service request failed because the key element is not partially accessible and the provided key element length is too short or too long for that key element.
        CSM_E_KEY_EMPTY: error-code=13  # The service request failed because of uninitialized source key element.
    CsmKeyManagement_CsmKey_Ssa_SignatureRamKey_replacementAuthority  # Interface to execute the key management functions.
      13 x operation:
        CertificateParse: possible-error=[CsmKeyManagement_CsmKey_Ssa_SignatureRamKey_replacementAuthority/E_NOT_OK, CsmKeyManagement_CsmKey_Ssa_SignatureRamKey_replacementAuthority/CSM_E_BUSY, CsmKeyManagement_CsmKey_Ssa_SignatureRamKey_replacementAuthority/CSM_E_KEY_EMPTY]  # This function shall dispatch the certificate parse function to the CRYIF.
        CertificateVerify: possible-error=[CsmKeyManagement_CsmKey_Ssa_SignatureRamKey_replacementAuthority/E_NOT_OK, CsmKeyManagement_CsmKey_Ssa_SignatureRamKey_replacementAuthority/CSM_E_BUSY, CsmKeyManagement_CsmKey_Ssa_SignatureRamKey_replacementAuthority/CSM_E_KEY_EMPTY]  # Verifies the certificate stored in the key referenced by verifyKeyId with the certificate stored in the key referenced by keyId. Note: Only certificates stored in the same Crypto Driver can be verified against each other. If the key element CRYPTO_KE_CERTIFICATE_CURRENT_TIME is used for the verification of the validity period of the certificate indentified by verifyKeyId, it shall have the same format as the timestamp in the certificate.
          arg verifyKeyId: type=uint32, direction=IN  # Holds the identifier of the key containing the certificate to be verified.
          arg verifyPtr: type=Crypto_VerifyResultType, direction=OUT  # Contains the result of the certificate verification.
        KeyCopy: possible-error=[CsmKeyManagement_CsmKey_Ssa_SignatureRamKey_replacementAuthority/E_NOT_OK, CsmKeyManagement_CsmKey_Ssa_SignatureRamKey_replacementAuthority/CSM_E_BUSY, CsmKeyManagement_CsmKey_Ssa_SignatureRamKey_replacementAuthority/CSM_E_SMALL_BUFFER, CsmKeyManagement_CsmKey_Ssa_SignatureRamKey_replacementAuthority/CSM_E_KEY_READ_FAIL, CsmKeyManagement_CsmKey_Ssa_SignatureRamKey_replacementAuthority/CSM_E_KEY_WRITE_FAIL, CsmKeyManagement_CsmKey_Ssa_SignatureRamKey_replacementAuthority/CSM_E_KEY_SIZE_MISMATCH, CsmKeyManagement_CsmKey_Ssa_SignatureRamKey_replacementAuthority/CSM_E_KEY_EMPTY]  # This function shall copy all key elements from the source key to a target key.
          arg targetKeyId: type=uint32, direction=IN  # Holds the identifier of the key whose key element shall be the destination element.
        KeyDerive: possible-error=[CsmKeyManagement_CsmKey_Ssa_SignatureRamKey_replacementAuthority/E_NOT_OK, CsmKeyManagement_CsmKey_Ssa_SignatureRamKey_replacementAuthority/CSM_E_BUSY, CsmKeyManagement_CsmKey_Ssa_SignatureRamKey_replacementAuthority/CSM_E_KEY_READ_FAIL, CsmKeyManagement_CsmKey_Ssa_SignatureRamKey_replacementAuthority/CSM_E_KEY_WRITE_FAIL, CsmKeyManagement_CsmKey_Ssa_SignatureRamKey_replacementAuthority/CSM_E_KEY_SIZE_MISMATCH, CsmKeyManagement_CsmKey_Ssa_SignatureRamKey_replacementAuthority/CSM_E_KEY_EMPTY]  # Derives a new key by using the key elements in the given key. The given key contains the key elements for the password and salt. The derived key is stored in the key element with the id 1 of the key identified by targetCryptoKeyId.
          arg targetKeyId: type=uint32, direction=IN  # Holds the identifier of the key which is used to store the derived key.
        KeyElementCopy: possible-error=[CsmKeyManagement_CsmKey_Ssa_SignatureRamKey_replacementAuthority/E_NOT_OK, CsmKeyManagement_CsmKey_Ssa_SignatureRamKey_replacementAuthority/CSM_E_BUSY, CsmKeyManagement_CsmKey_Ssa_SignatureRamKey_replacementAuthority/CSM_E_SMALL_BUFFER, CsmKeyManagement_CsmKey_Ssa_SignatureRamKey_replacementAuthority/CSM_E_KEY_READ_FAIL, CsmKeyManagement_CsmKey_Ssa_SignatureRamKey_replacementAuthority/CSM_E_KEY_WRITE_FAIL, CsmKeyManagement_CsmKey_Ssa_SignatureRamKey_replacementAuthority/CSM_E_KEY_SIZE_MISMATCH, CsmKeyManagement_CsmKey_Ssa_SignatureRamKey_replacementAuthority/CSM_E_KEY_EMPTY]  # This function shall copy a key elements from one key to a target key.
          arg keyElementId: type=uint32, direction=IN  # Holds the identifier of the key element which shall be the source for the copy operation.
          arg targetKeyId: type=uint32, direction=IN  # Holds the identifier of the key whose key element shall be the destination element.
          arg targetKeyElementId: type=uint32, direction=IN  # Holds the identifier of the key element which shall be the destination for the copy operation.
        KeyElementCopyPartial: possible-error=[CsmKeyManagement_CsmKey_Ssa_SignatureRamKey_replacementAuthority/E_NOT_OK, CsmKeyManagement_CsmKey_Ssa_SignatureRamKey_replacementAuthority/CSM_E_BUSY, CsmKeyManagement_CsmKey_Ssa_SignatureRamKey_replacementAuthority/CSM_E_KEY_NOT_AVAILABLE, CsmKeyManagement_CsmKey_Ssa_SignatureRamKey_replacementAuthority/CSM_E_KEY_READ_FAIL, CsmKeyManagement_CsmKey_Ssa_SignatureRamKey_replacementAuthority/CSM_E_KEY_WRITE_FAIL, CsmKeyManagement_CsmKey_Ssa_SignatureRamKey_replacementAuthority/CSM_E_KEY_SIZE_MISMATCH, CsmKeyManagement_CsmKey_Ssa_SignatureRamKey_replacementAuthority/CSM_E_KEY_EMPTY]  # This function shall copy parts of a key element from one key to parts of a target key element of a target key.
          6 x arg, all with type=uint32, direction=IN:
            keyElementId  # Holds the identifier of the key element which shall be the source for the copy operation.
            keyElementSourceOffset  # This is the offset of the source key element indicating the start index of the copy operation.
            keyElementTargetOffset  # This is the offset of the destination key element indicating the start index of the copy operation.
            keyElementCopyLength  # Specifies the number of bytes that shall be copied.
            targetKeyId  # Holds the identifier of the key whose key element shall be the destination element.
            targetKeyElementId  # Holds the identifier of the key element which shall be the destination for the copy operation.
        KeyElementGet: possible-error=[CsmKeyManagement_CsmKey_Ssa_SignatureRamKey_replacementAuthority/E_NOT_OK, CsmKeyManagement_CsmKey_Ssa_SignatureRamKey_replacementAuthority/CSM_E_BUSY, CsmKeyManagement_CsmKey_Ssa_SignatureRamKey_replacementAuthority/CSM_E_SMALL_BUFFER, CsmKeyManagement_CsmKey_Ssa_SignatureRamKey_replacementAuthority/CSM_E_KEY_READ_FAIL, CsmKeyManagement_CsmKey_Ssa_SignatureRamKey_replacementAuthority/CSM_E_KEY_NOT_AVAILABLE, CsmKeyManagement_CsmKey_Ssa_SignatureRamKey_replacementAuthority/CSM_E_KEY_EMPTY]  # Retrieves the key element bytes from a specific key element of the key and stores the key element in the provided buffer.
          arg keyElementId: type=uint32, direction=IN  # Holds the identifier of the key element to be read.
          arg keyPtr: type=Csm_KeyDataType_CsmKey_Ssa_SignatureRamKey_replacementAuthority, direction=OUT, server-argument-impl-policy=USE-ARRAY-BASE-TYPE  # Holds the data to the key element bytes to be written.
          arg keyLength: type=uint32, direction=INOUT  # Contains the number of key element bytes.
        KeyElementSet: possible-error=[CsmKeyManagement_CsmKey_Ssa_SignatureRamKey_replacementAuthority/E_NOT_OK, CsmKeyManagement_CsmKey_Ssa_SignatureRamKey_replacementAuthority/CSM_E_BUSY, CsmKeyManagement_CsmKey_Ssa_SignatureRamKey_replacementAuthority/CSM_E_KEY_WRITE_FAIL, CsmKeyManagement_CsmKey_Ssa_SignatureRamKey_replacementAuthority/CSM_E_KEY_NOT_AVAILABLE, CsmKeyManagement_CsmKey_Ssa_SignatureRamKey_replacementAuthority/CSM_E_KEY_SIZE_MISMATCH]  # Sets the given key element bytes to the key.
          arg keyElementId: type=uint32, direction=IN  # Holds the identifier of the key element to be written.
          arg keyPtr: type=Csm_KeyDataType_CsmKey_Ssa_SignatureRamKey_replacementAuthority, direction=IN, server-argument-impl-policy=USE-ARRAY-BASE-TYPE  # Holds the data to the key element bytes to be processed.
          arg keyLength: type=uint32, direction=IN  # Contains the number of key element bytes.
        KeyExchangeCalcPubVal: possible-error=[CsmKeyManagement_CsmKey_Ssa_SignatureRamKey_replacementAuthority/E_NOT_OK, CsmKeyManagement_CsmKey_Ssa_SignatureRamKey_replacementAuthority/CSM_E_BUSY, CsmKeyManagement_CsmKey_Ssa_SignatureRamKey_replacementAuthority/CSM_E_SMALL_BUFFER, CsmKeyManagement_CsmKey_Ssa_SignatureRamKey_replacementAuthority/CSM_E_KEY_EMPTY]  # Calculates the public value of the current user for the key exchange and stores the public key in the provided buffer.
          arg publicValuePtr: type=Csm_PublicValueDataType_CsmKey_Ssa_SignatureRamKey_replacementAuthority, direction=OUT, server-argument-impl-policy=USE-ARRAY-BASE-TYPE  # Holds a pointer to the memory location in which the public value length in bytes is stored. On calling this function, this parameter shall contain the size of the buffer in bytes provided by publicValuePtr. When the request has finished, the actual length of the returned value shall be stored.
          arg publicValueLengthPtr: type=uint32, direction=INOUT  # Contains the pointer to the data where the public value shall be stored.
        KeyExchangeCalcSecret: possible-error=[CsmKeyManagement_CsmKey_Ssa_SignatureRamKey_replacementAuthority/E_NOT_OK, CsmKeyManagement_CsmKey_Ssa_SignatureRamKey_replacementAuthority/CSM_E_BUSY, CsmKeyManagement_CsmKey_Ssa_SignatureRamKey_replacementAuthority/CSM_E_SMALL_BUFFER, CsmKeyManagement_CsmKey_Ssa_SignatureRamKey_replacementAuthority/CSM_E_KEY_EMPTY]  # Calculates the shared secret key for the key exchange with the key material of the key identified by the keyId and the partner public key. The shared secret key is stored as a key element in the same key.
          arg partnerPublicValuePtr: type=Csm_PublicValueDataType_CsmKey_Ssa_SignatureRamKey_replacementAuthority, direction=IN, server-argument-impl-policy=USE-ARRAY-BASE-TYPE  # Holds the pointer to the memory location containing the partner's public value.
          arg partnerPublicValueLength: type=uint32, direction=IN  # Contains the number of bytes of the partner public value.
        KeyGenerate: possible-error=[CsmKeyManagement_CsmKey_Ssa_SignatureRamKey_replacementAuthority/E_NOT_OK, CsmKeyManagement_CsmKey_Ssa_SignatureRamKey_replacementAuthority/CSM_E_BUSY, CsmKeyManagement_CsmKey_Ssa_SignatureRamKey_replacementAuthority/CSM_E_KEY_EMPTY]  # Generates new key material and store it in the key identified by keyId.
        KeySetValid: possible-error=[CsmKeyManagement_CsmKey_Ssa_SignatureRamKey_replacementAuthority/E_NOT_OK, CsmKeyManagement_CsmKey_Ssa_SignatureRamKey_replacementAuthority/CSM_E_BUSY]  # Sets the given key element bytes to the key.
        RandomSeed: possible-error=[CsmKeyManagement_CsmKey_Ssa_SignatureRamKey_replacementAuthority/E_NOT_OK, CsmKeyManagement_CsmKey_Ssa_SignatureRamKey_replacementAuthority/CSM_E_BUSY]  # Feeds a key element with a random seed.
          arg seedPtr: type=Csm_SeedDataTypeCsmKey_Ssa_SignatureRamKey_replacementAuthority, direction=IN, server-argument-impl-policy=USE-ARRAY-BASE-TYPE  # Holds the data which shall be used for the random seed initialization.
          arg seedLength: type=uint32, direction=IN  # Contains the length of the seed in bytes.
      8 x error:
        E_NOT_OK: error-code=1  # The service request failed.
        CSM_E_BUSY: error-code=2  # The service request failed because the service is still busy.
        CSM_E_SMALL_BUFFER: error-code=3  # The service request failed because the provided buffer is too small to store the result.
        CSM_E_KEY_READ_FAIL: error-code=6  # The service request failed because read access was denied.
        CSM_E_KEY_WRITE_FAIL: error-code=7  # The service request failed because write access was denied.
        CSM_E_KEY_NOT_AVAILABLE: error-code=8  # The service request failed because the key is not available.
        CSM_E_KEY_SIZE_MISMATCH: error-code=10  # The service request failed because the key element is not partially accessible and the provided key element length is too short or too long for that key element.
        CSM_E_KEY_EMPTY: error-code=13  # The service request failed because of uninitialized source key element.
    CsmRandomGenerate_Random_TRNG  # Starts the random number generation service of the CSM module.
      operation RandomGenerate: possible-error=[CsmRandomGenerate_Random_TRNG/E_NOT_OK, CsmRandomGenerate_Random_TRNG/CSM_E_BUSY, CSM_E_ENTROPY_EXHAUSTION]  # This interface shall be used to start the random generate service of the CSM module.
        arg resultBuffer: type=Csm_RandomGenerateResultType_Random_TRNG, direction=OUT, server-argument-impl-policy=USE-ARRAY-BASE-TYPE  # Holds a pointer to the memory location which will hold the random number. The memory location must have at least the given length.
        arg resultLength: type=uint32, direction=INOUT  # Holds a pointer to the memory location in which the length information is stored. On calling this function this parameter shall contain the size of the provided buffer. When the request has finished, the actual length of the returned random number shall be stored.
      operation CancelJob: possible-error=[CsmRandomGenerate_Random_TRNG/E_NOT_OK, CsmRandomGenerate_Random_TRNG/CSM_E_JOB_CANCELED]  # Cancels the Job.
      4 x error:
        E_NOT_OK: error-code=1  # The service request failed.
        CSM_E_BUSY: error-code=2  # The service request failed because the service is still busy.
        CSM_E_ENTROPY_EXHAUSTION: error-code=4  # The service request failed because the entropy of the random number generator is exhausted.
        CSM_E_JOB_CANCELED: error-code=12  # The job has been marked to be aborted at the next opportunity. It will be further processed until the job finish notification.
    CsmSignatureVerify_SigVerifyEd25519ph_SyncAsync_HWA  # A digital signature is a type of asymmetric cryptography. Digital signatures are equivalent to traditional handwritten signatures in many respects. Digital signatures can be used to authenticate the source of messages as well as to prove integrity of signed messages. If a message is digitally signed, any change in the message after signature will invalidate the signature. Furthermore, there is no efficient way to modify a message and its signature to produce a new message with a valid signature.
      operation SignatureVerify: possible-error=[CsmSignatureVerify_SigVerifyEd25519ph_SyncAsync_HWA/E_NOT_OK, CsmSignatureVerify_SigVerifyEd25519ph_SyncAsync_HWA/CSM_E_BUSY, CsmSignatureVerify_SigVerifyEd25519ph_SyncAsync_HWA/CSM_E_SMALL_BUFFER, CsmSignatureVerify_SigVerifyEd25519ph_SyncAsync_HWA/CSM_E_KEY_NOT_VALID, CsmSignatureVerify_SigVerifyEd25519ph_SyncAsync_HWA/CSM_E_KEY_SIZE_MISMATCH, CsmSignatureVerify_SigVerifyEd25519ph_SyncAsync_HWA/CSM_E_KEY_EMPTY]  # This interface shall be used to start the signature verification service of the CSM module.
        5 x arg:
          dataBuffer: type=Csm_SignatureVerifyDataType_SigVerifyEd25519ph_SyncAsync_HWA, direction=IN, server-argument-impl-policy=USE-ARRAY-BASE-TYPE  # Holds a pointer to the data for which a signature shall be computed.
          dataLength: type=uint32, direction=IN  # Contains the number of bytes for which the signature shall be computed.
          compareBuffer: type=Csm_SignatureVerifyCompareType_SigVerifyEd25519ph_SyncAsync_HWA, direction=IN, server-argument-impl-policy=USE-ARRAY-BASE-TYPE  # Contains the signature to be verified.
          compareLength: type=uint32, direction=IN  # Contains the length of the signature to be verified in bytes.
          verifyResult: type=Crypto_VerifyResultType, direction=OUT  # Holds a pointer to the memory location which will hold the result of the signature verification
      operation CancelJob: possible-error=[CsmSignatureVerify_SigVerifyEd25519ph_SyncAsync_HWA/E_NOT_OK, CsmSignatureVerify_SigVerifyEd25519ph_SyncAsync_HWA/CSM_E_JOB_CANCELED]  # Cancels the Job.
      7 x error:
        E_NOT_OK: error-code=1  # The service request failed.
        CSM_E_BUSY: error-code=2  # The service request failed because the service is still busy.
        CSM_E_SMALL_BUFFER: error-code=3  # The service request failed because the provided buffer is too small to store the result.
        CSM_E_KEY_NOT_VALID: error-code=9  # The service request failed because the key is not valid.
        CSM_E_KEY_SIZE_MISMATCH: error-code=10  # The service request failed because the key element is not partially accessible and the provided key element length is too short or too long for that key element.
        CSM_E_KEY_EMPTY: error-code=13  # The service request failed because of uninitialized source key element.
        CSM_E_JOB_CANCELED: error-code=12  # The job has been marked to be aborted at the next opportunity. It will be further processed until the job finish notification.
package /MICROSAR/Csm_swc/ComponentTypes
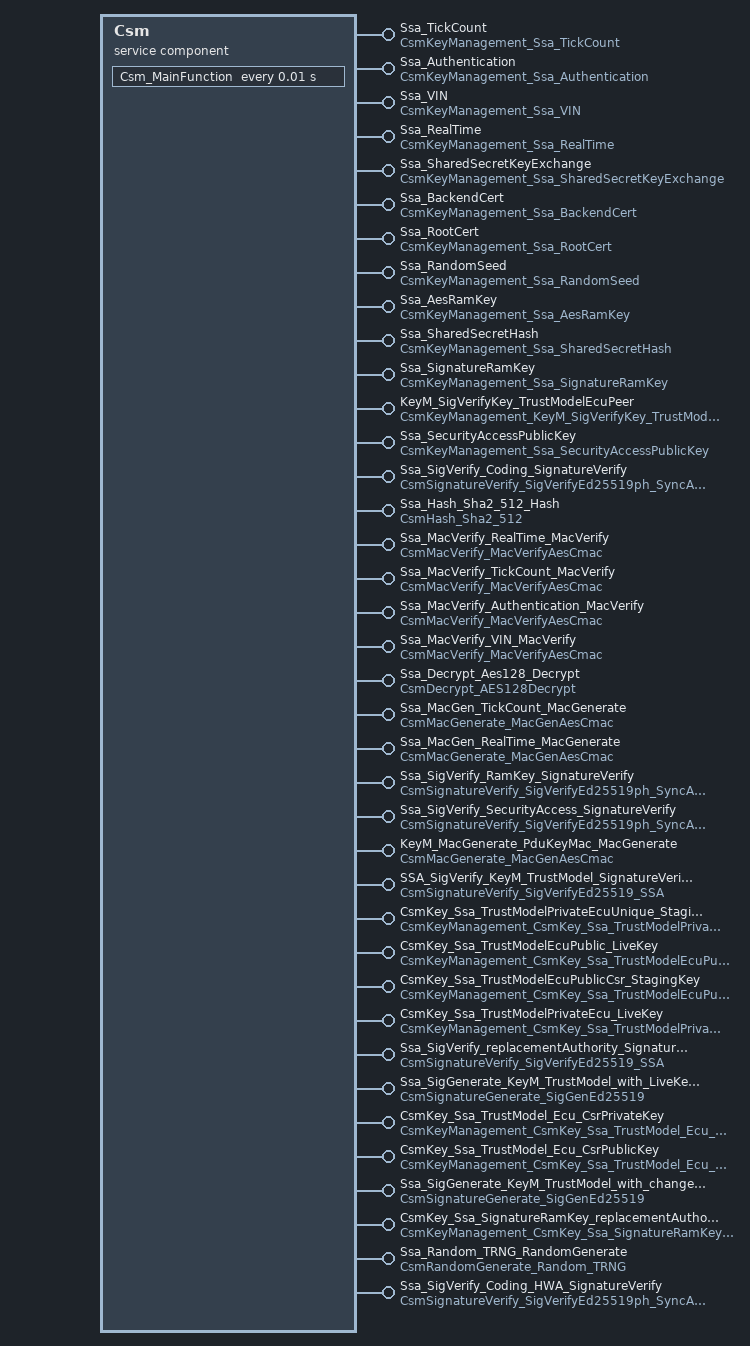
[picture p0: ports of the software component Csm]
  service sw component type Csm: category=SERVICE_COMPONENT
    38 x provide port:
      Ssa_TickCount: provided-interface=CsmKeyManagement_Ssa_TickCount
      Ssa_Authentication: provided-interface=CsmKeyManagement_Ssa_Authentication
      Ssa_VIN: provided-interface=CsmKeyManagement_Ssa_VIN
      Ssa_RealTime: provided-interface=CsmKeyManagement_Ssa_RealTime
      Ssa_SharedSecretKeyExchange: provided-interface=CsmKeyManagement_Ssa_SharedSecretKeyExchange
      Ssa_BackendCert: provided-interface=CsmKeyManagement_Ssa_BackendCert
      Ssa_RootCert: provided-interface=CsmKeyManagement_Ssa_RootCert
      Ssa_RandomSeed: provided-interface=CsmKeyManagement_Ssa_RandomSeed
      Ssa_AesRamKey: provided-interface=CsmKeyManagement_Ssa_AesRamKey
      Ssa_SharedSecretHash: provided-interface=CsmKeyManagement_Ssa_SharedSecretHash
      Ssa_SignatureRamKey: provided-interface=CsmKeyManagement_Ssa_SignatureRamKey
      KeyM_SigVerifyKey_TrustModelEcuPeer: provided-interface=CsmKeyManagement_KeyM_SigVerifyKey_TrustModelEcuPeer
      Ssa_SecurityAccessPublicKey: provided-interface=CsmKeyManagement_Ssa_SecurityAccessPublicKey
      Ssa_SigVerify_Coding_SignatureVerify: provided-interface=CsmSignatureVerify_SigVerifyEd25519ph_SyncAsync
      Ssa_Hash_Sha2_512_Hash: provided-interface=CsmHash_Sha2_512
      Ssa_MacVerify_RealTime_MacVerify: provided-interface=CsmMacVerify_MacVerifyAesCmac
      Ssa_MacVerify_TickCount_MacVerify: provided-interface=CsmMacVerify_MacVerifyAesCmac
      Ssa_MacVerify_Authentication_MacVerify: provided-interface=CsmMacVerify_MacVerifyAesCmac
      Ssa_MacVerify_VIN_MacVerify: provided-interface=CsmMacVerify_MacVerifyAesCmac
      Ssa_Decrypt_Aes128_Decrypt: provided-interface=CsmDecrypt_AES128Decrypt
      Ssa_MacGen_TickCount_MacGenerate: provided-interface=CsmMacGenerate_MacGenAesCmac
      Ssa_MacGen_RealTime_MacGenerate: provided-interface=CsmMacGenerate_MacGenAesCmac
      Ssa_SigVerify_RamKey_SignatureVerify: provided-interface=CsmSignatureVerify_SigVerifyEd25519ph_SyncAsync
      Ssa_SigVerify_SecurityAccess_SignatureVerify: provided-interface=CsmSignatureVerify_SigVerifyEd25519ph_SyncAsync
      KeyM_MacGenerate_PduKeyMac_MacGenerate: provided-interface=CsmMacGenerate_MacGenAesCmac
      SSA_SigVerify_KeyM_TrustModel_SignatureVerify: provided-interface=CsmSignatureVerify_SigVerifyEd25519_SSA
      CsmKey_Ssa_TrustModelPrivateEcuUnique_StagingKey: provided-interface=CsmKeyManagement_CsmKey_Ssa_TrustModelPrivateEcuUnique_StagingKey
      CsmKey_Ssa_TrustModelEcuPublic_LiveKey: provided-interface=CsmKeyManagement_CsmKey_Ssa_TrustModelEcuPublic_LiveKey
      CsmKey_Ssa_TrustModelEcuPublicCsr_StagingKey: provided-interface=CsmKeyManagement_CsmKey_Ssa_TrustModelEcuPublicCsr_StagingKey
      CsmKey_Ssa_TrustModelPrivateEcu_LiveKey: provided-interface=CsmKeyManagement_CsmKey_Ssa_TrustModelPrivateEcu_LiveKey
      Ssa_SigVerify_replacementAuthority_SignatureVerify: provided-interface=CsmSignatureVerify_SigVerifyEd25519_SSA
      Ssa_SigGenerate_KeyM_TrustModel_with_LiveKey_SignatureGenerate: provided-interface=CsmSignatureGenerate_SigGenEd25519
      CsmKey_Ssa_TrustModel_Ecu_CsrPrivateKey: provided-interface=CsmKeyManagement_CsmKey_Ssa_TrustModel_Ecu_CsrPrivateKey
      CsmKey_Ssa_TrustModel_Ecu_CsrPublicKey: provided-interface=CsmKeyManagement_CsmKey_Ssa_TrustModel_Ecu_CsrPublicKey
      Ssa_SigGenerate_KeyM_TrustModel_with_changeableKey_SignatureGenerate: provided-interface=CsmSignatureGenerate_SigGenEd25519
      CsmKey_Ssa_SignatureRamKey_replacementAuthority: provided-interface=CsmKeyManagement_CsmKey_Ssa_SignatureRamKey_replacementAuthority
      Ssa_Random_TRNG_RandomGenerate: provided-interface=CsmRandomGenerate_Random_TRNG
      Ssa_SigVerify_Coding_HWA_SignatureVerify: provided-interface=CsmSignatureVerify_SigVerifyEd25519ph_SyncAsync_HWA
    behavior CsmInternalBehavior: handle-termination-and-restart=NO-SUPPORT, included-data-type-set=data-type=[Csm_VerifyResultType, Csm_ConfigIdType, Crypto_OperationModeType, Crypto_VerifyResultType, Csm_KeyElementEnumType, Csm_ResultType, Crypto_ResultType, Csm_KeyDataType_Ssa_TickCount, Csm_PublicValueDataType_Ssa_TickCount, Csm_SeedDataTypeSsa_TickCount, Csm_KeyDataType_Ssa_Authentication, Csm_PublicValueDataType_Ssa_Authentication, Csm_SeedDataTypeSsa_Authentication, Csm_KeyDataType_Ssa_VIN, Csm_PublicValueDataType_Ssa_VIN, Csm_SeedDataTypeSsa_VIN, Csm_KeyDataType_Ssa_RealTime, Csm_PublicValueDataType_Ssa_RealTime, Csm_SeedDataTypeSsa_RealTime, Csm_KeyDataType_Ssa_SharedSecretKeyExchange, Csm_PublicValueDataType_Ssa_SharedSecretKeyExchange, Csm_SeedDataTypeSsa_SharedSecretKeyExchange, Csm_KeyDataType_Ssa_BackendCert, Csm_PublicValueDataType_Ssa_BackendCert, Csm_SeedDataTypeSsa_BackendCert, Csm_KeyDataType_Ssa_RootCert, Csm_PublicValueDataType_Ssa_RootCert, Csm_SeedDataTypeSsa_RootCert, Csm_KeyDataType_Ssa_RandomSeed, Csm_PublicValueDataType_Ssa_RandomSeed, Csm_SeedDataTypeSsa_RandomSeed, Csm_KeyDataType_Ssa_AesRamKey, Csm_PublicValueDataType_Ssa_AesRamKey, Csm_SeedDataTypeSsa_AesRamKey, Csm_KeyDataType_Ssa_SharedSecretHash, Csm_PublicValueDataType_Ssa_SharedSecretHash, Csm_SeedDataTypeSsa_SharedSecretHash, Csm_KeyDataType_Ssa_SignatureRamKey, Csm_PublicValueDataType_Ssa_SignatureRamKey, Csm_SeedDataTypeSsa_SignatureRamKey, Csm_KeyDataType_KeyM_SigVerifyKey_TrustModelEcuPeer, Csm_PublicValueDataType_KeyM_SigVerifyKey_TrustModelEcuPeer, Csm_SeedDataTypeKeyM_SigVerifyKey_TrustModelEcuPeer, Csm_KeyDataType_Ssa_SecurityAccessPublicKey, Csm_PublicValueDataType_Ssa_SecurityAccessPublicKey, Csm_SeedDataTypeSsa_SecurityAccessPublicKey, Csm_KeyDataType_CsmKey_Ssa_SignatureRamKey_replacementAuthority, Csm_PublicValueDataType_CsmKey_Ssa_SignatureRamKey_replacementAuthority, Csm_SeedDataTypeCsmKey_Ssa_SignatureRamKey_replacementAuthority, Csm_KeyDataType_CsmKey_Ssa_TrustModelPrivateEcuUnique_StagingKey, Csm_PublicValueDataType_CsmKey_Ssa_TrustModelPrivateEcuUnique_StagingKey, Csm_SeedDataTypeCsmKey_Ssa_TrustModelPrivateEcuUnique_StagingKey, Csm_KeyDataType_CsmKey_Ssa_TrustModelEcuPublic_LiveKey, Csm_PublicValueDataType_CsmKey_Ssa_TrustModelEcuPublic_LiveKey, Csm_SeedDataTypeCsmKey_Ssa_TrustModelEcuPublic_LiveKey, Csm_KeyDataType_CsmKey_Ssa_TrustModelEcuPublicCsr_StagingKey, Csm_PublicValueDataType_CsmKey_Ssa_TrustModelEcuPublicCsr_StagingKey, Csm_SeedDataTypeCsmKey_Ssa_TrustModelEcuPublicCsr_StagingKey, Csm_KeyDataType_CsmKey_Ssa_TrustModelPrivateEcu_LiveKey, Csm_PublicValueDataType_CsmKey_Ssa_TrustModelPrivateEcu_LiveKey, Csm_SeedDataTypeCsmKey_Ssa_TrustModelPrivateEcu_LiveKey, Csm_KeyDataType_CsmKey_Ssa_TrustModel_Ecu_CsrPrivateKey, Csm_PublicValueDataType_CsmKey_Ssa_TrustModel_Ecu_CsrPrivateKey, Csm_SeedDataTypeCsmKey_Ssa_TrustModel_Ecu_CsrPrivateKey, Csm_KeyDataType_CsmKey_Ssa_TrustModel_Ecu_CsrPublicKey, Csm_PublicValueDataType_CsmKey_Ssa_TrustModel_Ecu_CsrPublicKey, Csm_SeedDataTypeCsmKey_Ssa_TrustModel_Ecu_CsrPublicKey, Csm_SignatureVerifyDataType_SigVerifyEd25519ph_SyncAsync, Csm_SignatureVerifyCompareType_SigVerifyEd25519ph_SyncAsync, Csm_HashDataType_Sha2_512, Csm_HashResultType_Sha2_512, Csm_MacVerifyDataType_MacVerifyAesCmac, Csm_MacVerifyCompareType_MacVerifyAesCmac, Csm_DecryptDataType_AES128Decrypt, Csm_DecryptResultType_AES128Decrypt, Csm_MacGenerateDataType_MacGenAesCmac, Csm_MacGenerateResultType_MacGenAesCmac, Csm_SignatureVerifyDataType_SigVerifyEd25519_SSA, Csm_SignatureVerifyCompareType_SigVerifyEd25519_SSA, Csm_SignatureGenerateDataType_SigGenEd25519, Csm_SignatureGenerateResultType_SigGenEd25519, Csm_RandomGenerateResultType_Random_TRNG, Csm_SignatureVerifyDataType_SigVerifyEd25519ph_SyncAsync_HWA, Csm_SignatureVerifyCompareType_SigVerifyEd25519ph_SyncAsync_HWA]
      timing event Timer_Csm_MainFunction: start-on-event=Csm_MainFunction, period=0.01
      296 x operation invoked event:
        OpEventKeySetValid_KeySetValid_Ssa_RootCert: start-on-event=KeySetValid, operation=Ssa_RootCert.KeySetValid
        OpEventKeySetValid_KeySetValid_Ssa_TickCount: start-on-event=KeySetValid, operation=Ssa_TickCount.KeySetValid
        OpEventKeySetValid_KeySetValid_Ssa_SecurityAccessPublicKey: start-on-event=KeySetValid, operation=Ssa_SecurityAccessPublicKey.KeySetValid
        OpEventKeySetValid_KeySetValid_Ssa_VIN: start-on-event=KeySetValid, operation=Ssa_VIN.KeySetValid
        OpEventKeySetValid_KeySetValid_KeyM_SigVerifyKey_TrustModelEcuPeer: start-on-event=KeySetValid, operation=KeyM_SigVerifyKey_TrustModelEcuPeer.KeySetValid
        OpEventKeySetValid_KeySetValid_Ssa_SharedSecretHash: start-on-event=KeySetValid, operation=Ssa_SharedSecretHash.KeySetValid
        OpEventKeySetValid_KeySetValid_Ssa_SignatureRamKey: start-on-event=KeySetValid, operation=Ssa_SignatureRamKey.KeySetValid
        OpEventKeySetValid_KeySetValid_Ssa_Authentication: start-on-event=KeySetValid, operation=Ssa_Authentication.KeySetValid
        OpEventKeySetValid_KeySetValid_Ssa_RealTime: start-on-event=KeySetValid, operation=Ssa_RealTime.KeySetValid
        OpEventKeySetValid_KeySetValid_Ssa_AesRamKey: start-on-event=KeySetValid, operation=Ssa_AesRamKey.KeySetValid
        OpEventKeySetValid_KeySetValid_Ssa_SharedSecretKeyExchange: start-on-event=KeySetValid, operation=Ssa_SharedSecretKeyExchange.KeySetValid
        OpEventKeySetValid_KeySetValid_Ssa_RandomSeed: start-on-event=KeySetValid, operation=Ssa_RandomSeed.KeySetValid
        OpEventKeySetValid_KeySetValid_Ssa_BackendCert: start-on-event=KeySetValid, operation=Ssa_BackendCert.KeySetValid
        OpEventRandomSeed_RandomSeed_Ssa_BackendCert: start-on-event=RandomSeed, operation=Ssa_BackendCert.RandomSeed
        OpEventRandomSeed_RandomSeed_Ssa_RootCert: start-on-event=RandomSeed, operation=Ssa_RootCert.RandomSeed
        OpEventRandomSeed_RandomSeed_Ssa_VIN: start-on-event=RandomSeed, operation=Ssa_VIN.RandomSeed
        OpEventRandomSeed_RandomSeed_Ssa_RealTime: start-on-event=RandomSeed, operation=Ssa_RealTime.RandomSeed
        OpEventRandomSeed_RandomSeed_Ssa_SharedSecretKeyExchange: start-on-event=RandomSeed, operation=Ssa_SharedSecretKeyExchange.RandomSeed
        OpEventRandomSeed_RandomSeed_Ssa_TickCount: start-on-event=RandomSeed, operation=Ssa_TickCount.RandomSeed
        OpEventRandomSeed_RandomSeed_Ssa_SharedSecretHash: start-on-event=RandomSeed, operation=Ssa_SharedSecretHash.RandomSeed
        OpEventRandomSeed_RandomSeed_Ssa_Authentication: start-on-event=RandomSeed, operation=Ssa_Authentication.RandomSeed
        OpEventRandomSeed_RandomSeed_Ssa_AesRamKey: start-on-event=RandomSeed, operation=Ssa_AesRamKey.RandomSeed
        OpEventRandomSeed_RandomSeed_Ssa_RandomSeed: start-on-event=RandomSeed, operation=Ssa_RandomSeed.RandomSeed
        OpEventRandomSeed_RandomSeed_Ssa_SecurityAccessPublicKey: start-on-event=RandomSeed, operation=Ssa_SecurityAccessPublicKey.RandomSeed
        OpEventRandomSeed_RandomSeed_KeyM_SigVerifyKey_TrustModelEcuPeer: start-on-event=RandomSeed, operation=KeyM_SigVerifyKey_TrustModelEcuPeer.RandomSeed
        OpEventRandomSeed_RandomSeed_Ssa_SignatureRamKey: start-on-event=RandomSeed, operation=Ssa_SignatureRamKey.RandomSeed
        OpEventKeyElementCopyPartial_KeyElementCopyPartial_Ssa_SignatureRamKey: start-on-event=KeyElementCopyPartial, operation=Ssa_SignatureRamKey.KeyElementCopyPartial
        OpEventKeyElementCopyPartial_KeyElementCopyPartial_Ssa_SharedSecretKeyExchange: start-on-event=KeyElementCopyPartial, operation=Ssa_SharedSecretKeyExchange.KeyElementCopyPartial
        OpEventKeyElementCopyPartial_KeyElementCopyPartial_Ssa_SharedSecretHash: start-on-event=KeyElementCopyPartial, operation=Ssa_SharedSecretHash.KeyElementCopyPartial
        OpEventKeyElementCopyPartial_KeyElementCopyPartial_Ssa_RootCert: start-on-event=KeyElementCopyPartial, operation=Ssa_RootCert.KeyElementCopyPartial
        OpEventKeyElementCopyPartial_KeyElementCopyPartial_Ssa_SecurityAccessPublicKey: start-on-event=KeyElementCopyPartial, operation=Ssa_SecurityAccessPublicKey.KeyElementCopyPartial
        OpEventKeyElementCopyPartial_KeyElementCopyPartial_Ssa_Authentication: start-on-event=KeyElementCopyPartial, operation=Ssa_Authentication.KeyElementCopyPartial
        OpEventKeyElementCopyPartial_KeyElementCopyPartial_Ssa_VIN: start-on-event=KeyElementCopyPartial, operation=Ssa_VIN.KeyElementCopyPartial
        OpEventKeyElementCopyPartial_KeyElementCopyPartial_Ssa_RealTime: start-on-event=KeyElementCopyPartial, operation=Ssa_RealTime.KeyElementCopyPartial
        OpEventKeyElementCopyPartial_KeyElementCopyPartial_Ssa_TickCount: start-on-event=KeyElementCopyPartial, operation=Ssa_TickCount.KeyElementCopyPartial
        OpEventKeyElementCopyPartial_KeyElementCopyPartial_Ssa_RandomSeed: start-on-event=KeyElementCopyPartial, operation=Ssa_RandomSeed.KeyElementCopyPartial
        OpEventKeyElementCopyPartial_KeyElementCopyPartial_KeyM_SigVerifyKey_TrustModelEcuPeer: start-on-event=KeyElementCopyPartial, operation=KeyM_SigVerifyKey_TrustModelEcuPeer.KeyElementCopyPartial
        OpEventKeyElementCopyPartial_KeyElementCopyPartial_Ssa_AesRamKey: start-on-event=KeyElementCopyPartial, operation=Ssa_AesRamKey.KeyElementCopyPartial
        OpEventKeyElementCopyPartial_KeyElementCopyPartial_Ssa_BackendCert: start-on-event=KeyElementCopyPartial, operation=Ssa_BackendCert.KeyElementCopyPartial
        OpEventKeyElementSet_KeyElementSet_Ssa_TickCount: start-on-event=KeyElementSet, operation=Ssa_TickCount.KeyElementSet
        OpEventKeyElementSet_KeyElementSet_KeyM_SigVerifyKey_TrustModelEcuPeer: start-on-event=KeyElementSet, operation=KeyM_SigVerifyKey_TrustModelEcuPeer.KeyElementSet
        OpEventKeyElementSet_KeyElementSet_Ssa_SharedSecretKeyExchange: start-on-event=KeyElementSet, operation=Ssa_SharedSecretKeyExchange.KeyElementSet
        OpEventKeyElementSet_KeyElementSet_Ssa_AesRamKey: start-on-event=KeyElementSet, operation=Ssa_AesRamKey.KeyElementSet
        OpEventKeyElementSet_KeyElementSet_Ssa_SignatureRamKey: start-on-event=KeyElementSet, operation=Ssa_SignatureRamKey.KeyElementSet
        OpEventKeyElementSet_KeyElementSet_Ssa_VIN: start-on-event=KeyElementSet, operation=Ssa_VIN.KeyElementSet
        OpEventKeyElementSet_KeyElementSet_Ssa_RealTime: start-on-event=KeyElementSet, operation=Ssa_RealTime.KeyElementSet
        OpEventKeyElementSet_KeyElementSet_Ssa_RandomSeed: start-on-event=KeyElementSet, operation=Ssa_RandomSeed.KeyElementSet
        OpEventKeyElementSet_KeyElementSet_Ssa_RootCert: start-on-event=KeyElementSet, operation=Ssa_RootCert.KeyElementSet
        OpEventKeyElementSet_KeyElementSet_Ssa_SecurityAccessPublicKey: start-on-event=KeyElementSet, operation=Ssa_SecurityAccessPublicKey.KeyElementSet
        OpEventKeyElementSet_KeyElementSet_Ssa_Authentication: start-on-event=KeyElementSet, operation=Ssa_Authentication.KeyElementSet
        OpEventKeyElementSet_KeyElementSet_Ssa_BackendCert: start-on-event=KeyElementSet, operation=Ssa_BackendCert.KeyElementSet
        OpEventKeyElementSet_KeyElementSet_Ssa_SharedSecretHash: start-on-event=KeyElementSet, operation=Ssa_SharedSecretHash.KeyElementSet
        OpEventHash_Hash_Ssa_Hash_Sha2_512_Hash: start-on-event=Hash, operation=Ssa_Hash_Sha2_512_Hash.Hash
        OpEventKeyCopy_KeyCopy_Ssa_BackendCert: start-on-event=KeyCopy, operation=Ssa_BackendCert.KeyCopy
        OpEventKeyCopy_KeyCopy_Ssa_SharedSecretKeyExchange: start-on-event=KeyCopy, operation=Ssa_SharedSecretKeyExchange.KeyCopy
        OpEventKeyCopy_KeyCopy_Ssa_RootCert: start-on-event=KeyCopy, operation=Ssa_RootCert.KeyCopy
        OpEventKeyCopy_KeyCopy_Ssa_RandomSeed: start-on-event=KeyCopy, operation=Ssa_RandomSeed.KeyCopy
        OpEventKeyCopy_KeyCopy_Ssa_AesRamKey: start-on-event=KeyCopy, operation=Ssa_AesRamKey.KeyCopy
        OpEventKeyCopy_KeyCopy_Ssa_SignatureRamKey: start-on-event=KeyCopy, operation=Ssa_SignatureRamKey.KeyCopy
        OpEventKeyCopy_KeyCopy_KeyM_SigVerifyKey_TrustModelEcuPeer: start-on-event=KeyCopy, operation=KeyM_SigVerifyKey_TrustModelEcuPeer.KeyCopy
        OpEventKeyCopy_KeyCopy_Ssa_VIN: start-on-event=KeyCopy, operation=Ssa_VIN.KeyCopy
        OpEventKeyCopy_KeyCopy_Ssa_SharedSecretHash: start-on-event=KeyCopy, operation=Ssa_SharedSecretHash.KeyCopy
        OpEventKeyCopy_KeyCopy_Ssa_SecurityAccessPublicKey: start-on-event=KeyCopy, operation=Ssa_SecurityAccessPublicKey.KeyCopy
        OpEventKeyCopy_KeyCopy_Ssa_RealTime: start-on-event=KeyCopy, operation=Ssa_RealTime.KeyCopy
        OpEventKeyCopy_KeyCopy_Ssa_Authentication: start-on-event=KeyCopy, operation=Ssa_Authentication.KeyCopy
        OpEventKeyCopy_KeyCopy_Ssa_TickCount: start-on-event=KeyCopy, operation=Ssa_TickCount.KeyCopy
        OpEventCertificateParse_CertificateParse_Ssa_TickCount: start-on-event=CertificateParse, operation=Ssa_TickCount.CertificateParse
        OpEventCertificateParse_CertificateParse_Ssa_SignatureRamKey: start-on-event=CertificateParse, operation=Ssa_SignatureRamKey.CertificateParse
        OpEventCertificateParse_CertificateParse_Ssa_VIN: start-on-event=CertificateParse, operation=Ssa_VIN.CertificateParse
        OpEventCertificateParse_CertificateParse_Ssa_Authentication: start-on-event=CertificateParse, operation=Ssa_Authentication.CertificateParse
        OpEventCertificateParse_CertificateParse_Ssa_RandomSeed: start-on-event=CertificateParse, operation=Ssa_RandomSeed.CertificateParse
        OpEventCertificateParse_CertificateParse_Ssa_RealTime: start-on-event=CertificateParse, operation=Ssa_RealTime.CertificateParse
        OpEventCertificateParse_CertificateParse_KeyM_SigVerifyKey_TrustModelEcuPeer: start-on-event=CertificateParse, operation=KeyM_SigVerifyKey_TrustModelEcuPeer.CertificateParse
        OpEventCertificateParse_CertificateParse_Ssa_SharedSecretKeyExchange: start-on-event=CertificateParse, operation=Ssa_SharedSecretKeyExchange.CertificateParse
        OpEventCertificateParse_CertificateParse_Ssa_RootCert: start-on-event=CertificateParse, operation=Ssa_RootCert.CertificateParse
        OpEventCertificateParse_CertificateParse_Ssa_AesRamKey: start-on-event=CertificateParse, operation=Ssa_AesRamKey.CertificateParse
        OpEventCertificateParse_CertificateParse_Ssa_SharedSecretHash: start-on-event=CertificateParse, operation=Ssa_SharedSecretHash.CertificateParse
        OpEventCertificateParse_CertificateParse_Ssa_BackendCert: start-on-event=CertificateParse, operation=Ssa_BackendCert.CertificateParse
        OpEventCertificateParse_CertificateParse_Ssa_SecurityAccessPublicKey: start-on-event=CertificateParse, operation=Ssa_SecurityAccessPublicKey.CertificateParse
        OpEventCertificateVerify_CertificateVerify_Ssa_RandomSeed: start-on-event=CertificateVerify, operation=Ssa_RandomSeed.CertificateVerify
        OpEventCertificateVerify_CertificateVerify_Ssa_SharedSecretKeyExchange: start-on-event=CertificateVerify, operation=Ssa_SharedSecretKeyExchange.CertificateVerify
        OpEventCertificateVerify_CertificateVerify_Ssa_TickCount: start-on-event=CertificateVerify, operation=Ssa_TickCount.CertificateVerify
        OpEventCertificateVerify_CertificateVerify_Ssa_AesRamKey: start-on-event=CertificateVerify, operation=Ssa_AesRamKey.CertificateVerify
        OpEventCertificateVerify_CertificateVerify_Ssa_SharedSecretHash: start-on-event=CertificateVerify, operation=Ssa_SharedSecretHash.CertificateVerify
        OpEventCertificateVerify_CertificateVerify_Ssa_RealTime: start-on-event=CertificateVerify, operation=Ssa_RealTime.CertificateVerify
        OpEventCertificateVerify_CertificateVerify_Ssa_VIN: start-on-event=CertificateVerify, operation=Ssa_VIN.CertificateVerify
        OpEventCertificateVerify_CertificateVerify_Ssa_SecurityAccessPublicKey: start-on-event=CertificateVerify, operation=Ssa_SecurityAccessPublicKey.CertificateVerify
        OpEventCertificateVerify_CertificateVerify_Ssa_Authentication: start-on-event=CertificateVerify, operation=Ssa_Authentication.CertificateVerify
        OpEventCertificateVerify_CertificateVerify_KeyM_SigVerifyKey_TrustModelEcuPeer: start-on-event=CertificateVerify, operation=KeyM_SigVerifyKey_TrustModelEcuPeer.CertificateVerify
        OpEventCertificateVerify_CertificateVerify_Ssa_SignatureRamKey: start-on-event=CertificateVerify, operation=Ssa_SignatureRamKey.CertificateVerify
        OpEventCertificateVerify_CertificateVerify_Ssa_BackendCert: start-on-event=CertificateVerify, operation=Ssa_BackendCert.CertificateVerify
        OpEventCertificateVerify_CertificateVerify_Ssa_RootCert: start-on-event=CertificateVerify, operation=Ssa_RootCert.CertificateVerify
        OpEventKeyDerive_KeyDerive_KeyM_SigVerifyKey_TrustModelEcuPeer: start-on-event=KeyDerive, operation=KeyM_SigVerifyKey_TrustModelEcuPeer.KeyDerive
        OpEventKeyDerive_KeyDerive_Ssa_SharedSecretHash: start-on-event=KeyDerive, operation=Ssa_SharedSecretHash.KeyDerive
        OpEventKeyDerive_KeyDerive_Ssa_SharedSecretKeyExchange: start-on-event=KeyDerive, operation=Ssa_SharedSecretKeyExchange.KeyDerive
        OpEventKeyDerive_KeyDerive_Ssa_RootCert: start-on-event=KeyDerive, operation=Ssa_RootCert.KeyDerive
        OpEventKeyDerive_KeyDerive_Ssa_RandomSeed: start-on-event=KeyDerive, operation=Ssa_RandomSeed.KeyDerive
        OpEventKeyDerive_KeyDerive_Ssa_BackendCert: start-on-event=KeyDerive, operation=Ssa_BackendCert.KeyDerive
        OpEventKeyDerive_KeyDerive_Ssa_SecurityAccessPublicKey: start-on-event=KeyDerive, operation=Ssa_SecurityAccessPublicKey.KeyDerive
        OpEventKeyDerive_KeyDerive_Ssa_SignatureRamKey: start-on-event=KeyDerive, operation=Ssa_SignatureRamKey.KeyDerive
        OpEventKeyDerive_KeyDerive_Ssa_Authentication: start-on-event=KeyDerive, operation=Ssa_Authentication.KeyDerive
        OpEventKeyDerive_KeyDerive_Ssa_RealTime: start-on-event=KeyDerive, operation=Ssa_RealTime.KeyDerive
        OpEventKeyDerive_KeyDerive_Ssa_TickCount: start-on-event=KeyDerive, operation=Ssa_TickCount.KeyDerive
        OpEventKeyDerive_KeyDerive_Ssa_AesRamKey: start-on-event=KeyDerive, operation=Ssa_AesRamKey.KeyDerive
        OpEventKeyDerive_KeyDerive_Ssa_VIN: start-on-event=KeyDerive, operation=Ssa_VIN.KeyDerive
        OpEventKeyGenerate_KeyGenerate_Ssa_VIN: start-on-event=KeyGenerate, operation=Ssa_VIN.KeyGenerate
        OpEventKeyGenerate_KeyGenerate_Ssa_RealTime: start-on-event=KeyGenerate, operation=Ssa_RealTime.KeyGenerate
        OpEventKeyGenerate_KeyGenerate_Ssa_RandomSeed: start-on-event=KeyGenerate, operation=Ssa_RandomSeed.KeyGenerate
        OpEventKeyGenerate_KeyGenerate_Ssa_AesRamKey: start-on-event=KeyGenerate, operation=Ssa_AesRamKey.KeyGenerate
        OpEventKeyGenerate_KeyGenerate_Ssa_TickCount: start-on-event=KeyGenerate, operation=Ssa_TickCount.KeyGenerate
        OpEventKeyGenerate_KeyGenerate_Ssa_SharedSecretKeyExchange: start-on-event=KeyGenerate, operation=Ssa_SharedSecretKeyExchange.KeyGenerate
        OpEventKeyGenerate_KeyGenerate_KeyM_SigVerifyKey_TrustModelEcuPeer: start-on-event=KeyGenerate, operation=KeyM_SigVerifyKey_TrustModelEcuPeer.KeyGenerate
        OpEventKeyGenerate_KeyGenerate_Ssa_SignatureRamKey: start-on-event=KeyGenerate, operation=Ssa_SignatureRamKey.KeyGenerate
        OpEventKeyGenerate_KeyGenerate_Ssa_Authentication: start-on-event=KeyGenerate, operation=Ssa_Authentication.KeyGenerate
        OpEventKeyGenerate_KeyGenerate_Ssa_SecurityAccessPublicKey: start-on-event=KeyGenerate, operation=Ssa_SecurityAccessPublicKey.KeyGenerate
        OpEventKeyGenerate_KeyGenerate_Ssa_BackendCert: start-on-event=KeyGenerate, operation=Ssa_BackendCert.KeyGenerate
        OpEventKeyGenerate_KeyGenerate_Ssa_RootCert: start-on-event=KeyGenerate, operation=Ssa_RootCert.KeyGenerate
        OpEventKeyGenerate_KeyGenerate_Ssa_SharedSecretHash: start-on-event=KeyGenerate, operation=Ssa_SharedSecretHash.KeyGenerate
        OpEventCancelJob_CancelJob_Ssa_MacGen_TickCount_MacGenerate: start-on-event=CancelJob, operation=Ssa_MacGen_TickCount_MacGenerate.CancelJob
        OpEventCancelJob_CancelJob_Ssa_MacGen_RealTime_MacGenerate: start-on-event=CancelJob, operation=Ssa_MacGen_RealTime_MacGenerate.CancelJob
        OpEventCancelJob_CancelJob_KeyM_MacGenerate_PduKeyMac_MacGenerate: start-on-event=CancelJob, operation=KeyM_MacGenerate_PduKeyMac_MacGenerate.CancelJob
        OpEventCancelJob_CancelJob_SSA_SigVerify_KeyM_TrustModel_SignatureVerify: start-on-event=CancelJob, operation=SSA_SigVerify_KeyM_TrustModel_SignatureVerify.CancelJob
        OpEventCancelJob_CancelJob_Ssa_Hash_Sha2_512_Hash: start-on-event=CancelJob, operation=Ssa_Hash_Sha2_512_Hash.CancelJob
        OpEventCancelJob_CancelJob_Ssa_MacVerify_RealTime_MacVerify: start-on-event=CancelJob, operation=Ssa_MacVerify_RealTime_MacVerify.CancelJob
        OpEventCancelJob_CancelJob_Ssa_MacVerify_TickCount_MacVerify: start-on-event=CancelJob, operation=Ssa_MacVerify_TickCount_MacVerify.CancelJob
        OpEventCancelJob_CancelJob_Ssa_MacVerify_Authentication_MacVerify: start-on-event=CancelJob, operation=Ssa_MacVerify_Authentication_MacVerify.CancelJob
        OpEventCancelJob_CancelJob_Ssa_MacVerify_VIN_MacVerify: start-on-event=CancelJob, operation=Ssa_MacVerify_VIN_MacVerify.CancelJob
        OpEventCancelJob_CancelJob_Ssa_Decrypt_Aes128_Decrypt: start-on-event=CancelJob, operation=Ssa_Decrypt_Aes128_Decrypt.CancelJob
        OpEventCancelJob_CancelJob_Ssa_SigVerify_Coding_SignatureVerify: start-on-event=CancelJob, operation=Ssa_SigVerify_Coding_SignatureVerify.CancelJob
        OpEventCancelJob_CancelJob_Ssa_SigVerify_RamKey_SignatureVerify: start-on-event=CancelJob, operation=Ssa_SigVerify_RamKey_SignatureVerify.CancelJob
        OpEventCancelJob_CancelJob_Ssa_SigVerify_SecurityAccess_SignatureVerify: start-on-event=CancelJob, operation=Ssa_SigVerify_SecurityAccess_SignatureVerify.CancelJob
        OpEventKeyElementGet_KeyElementGet_Ssa_RandomSeed: start-on-event=KeyElementGet, operation=Ssa_RandomSeed.KeyElementGet
        OpEventKeyElementGet_KeyElementGet_Ssa_SignatureRamKey: start-on-event=KeyElementGet, operation=Ssa_SignatureRamKey.KeyElementGet
        OpEventKeyElementGet_KeyElementGet_Ssa_TickCount: start-on-event=KeyElementGet, operation=Ssa_TickCount.KeyElementGet
        OpEventKeyElementGet_KeyElementGet_Ssa_SharedSecretKeyExchange: start-on-event=KeyElementGet, operation=Ssa_SharedSecretKeyExchange.KeyElementGet
        OpEventKeyElementGet_KeyElementGet_Ssa_RootCert: start-on-event=KeyElementGet, operation=Ssa_RootCert.KeyElementGet
        OpEventKeyElementGet_KeyElementGet_KeyM_SigVerifyKey_TrustModelEcuPeer: start-on-event=KeyElementGet, operation=KeyM_SigVerifyKey_TrustModelEcuPeer.KeyElementGet
        OpEventKeyElementGet_KeyElementGet_Ssa_AesRamKey: start-on-event=KeyElementGet, operation=Ssa_AesRamKey.KeyElementGet
        OpEventKeyElementGet_KeyElementGet_Ssa_SharedSecretHash: start-on-event=KeyElementGet, operation=Ssa_SharedSecretHash.KeyElementGet
        OpEventKeyElementGet_KeyElementGet_Ssa_BackendCert: start-on-event=KeyElementGet, operation=Ssa_BackendCert.KeyElementGet
        OpEventKeyElementGet_KeyElementGet_Ssa_Authentication: start-on-event=KeyElementGet, operation=Ssa_Authentication.KeyElementGet
        OpEventKeyElementGet_KeyElementGet_Ssa_SecurityAccessPublicKey: start-on-event=KeyElementGet, operation=Ssa_SecurityAccessPublicKey.KeyElementGet
        OpEventKeyElementGet_KeyElementGet_Ssa_VIN: start-on-event=KeyElementGet, operation=Ssa_VIN.KeyElementGet
        OpEventKeyElementGet_KeyElementGet_Ssa_RealTime: start-on-event=KeyElementGet, operation=Ssa_RealTime.KeyElementGet
        OpEventKeyExchangeCalcSecret_KeyExchangeCalcSecret_Ssa_AesRamKey: start-on-event=KeyExchangeCalcSecret, operation=Ssa_AesRamKey.KeyExchangeCalcSecret
        OpEventKeyExchangeCalcSecret_KeyExchangeCalcSecret_Ssa_SecurityAccessPublicKey: start-on-event=KeyExchangeCalcSecret, operation=Ssa_SecurityAccessPublicKey.KeyExchangeCalcSecret
        OpEventKeyExchangeCalcSecret_KeyExchangeCalcSecret_Ssa_SharedSecretKeyExchange: start-on-event=KeyExchangeCalcSecret, operation=Ssa_SharedSecretKeyExchange.KeyExchangeCalcSecret
        OpEventKeyExchangeCalcSecret_KeyExchangeCalcSecret_Ssa_RootCert: start-on-event=KeyExchangeCalcSecret, operation=Ssa_RootCert.KeyExchangeCalcSecret
        OpEventKeyExchangeCalcSecret_KeyExchangeCalcSecret_Ssa_Authentication: start-on-event=KeyExchangeCalcSecret, operation=Ssa_Authentication.KeyExchangeCalcSecret
        OpEventKeyExchangeCalcSecret_KeyExchangeCalcSecret_Ssa_RandomSeed: start-on-event=KeyExchangeCalcSecret, operation=Ssa_RandomSeed.KeyExchangeCalcSecret
        OpEventKeyExchangeCalcSecret_KeyExchangeCalcSecret_Ssa_SharedSecretHash: start-on-event=KeyExchangeCalcSecret, operation=Ssa_SharedSecretHash.KeyExchangeCalcSecret
        OpEventKeyExchangeCalcSecret_KeyExchangeCalcSecret_Ssa_RealTime: start-on-event=KeyExchangeCalcSecret, operation=Ssa_RealTime.KeyExchangeCalcSecret
        OpEventKeyExchangeCalcSecret_KeyExchangeCalcSecret_Ssa_SignatureRamKey: start-on-event=KeyExchangeCalcSecret, operation=Ssa_SignatureRamKey.KeyExchangeCalcSecret
        OpEventKeyExchangeCalcSecret_KeyExchangeCalcSecret_Ssa_TickCount: start-on-event=KeyExchangeCalcSecret, operation=Ssa_TickCount.KeyExchangeCalcSecret
        OpEventKeyExchangeCalcSecret_KeyExchangeCalcSecret_KeyM_SigVerifyKey_TrustModelEcuPeer: start-on-event=KeyExchangeCalcSecret, operation=KeyM_SigVerifyKey_TrustModelEcuPeer.KeyExchangeCalcSecret
        OpEventKeyExchangeCalcSecret_KeyExchangeCalcSecret_Ssa_BackendCert: start-on-event=KeyExchangeCalcSecret, operation=Ssa_BackendCert.KeyExchangeCalcSecret
        OpEventKeyExchangeCalcSecret_KeyExchangeCalcSecret_Ssa_VIN: start-on-event=KeyExchangeCalcSecret, operation=Ssa_VIN.KeyExchangeCalcSecret
        OpEventKeyExchangeCalcPubVal_KeyExchangeCalcPubVal_Ssa_RandomSeed: start-on-event=KeyExchangeCalcPubVal, operation=Ssa_RandomSeed.KeyExchangeCalcPubVal
        OpEventKeyExchangeCalcPubVal_KeyExchangeCalcPubVal_Ssa_AesRamKey: start-on-event=KeyExchangeCalcPubVal, operation=Ssa_AesRamKey.KeyExchangeCalcPubVal
        OpEventKeyExchangeCalcPubVal_KeyExchangeCalcPubVal_Ssa_SharedSecretKeyExchange: start-on-event=KeyExchangeCalcPubVal, operation=Ssa_SharedSecretKeyExchange.KeyExchangeCalcPubVal
        OpEventKeyExchangeCalcPubVal_KeyExchangeCalcPubVal_Ssa_BackendCert: start-on-event=KeyExchangeCalcPubVal, operation=Ssa_BackendCert.KeyExchangeCalcPubVal
        OpEventKeyExchangeCalcPubVal_KeyExchangeCalcPubVal_Ssa_RealTime: start-on-event=KeyExchangeCalcPubVal, operation=Ssa_RealTime.KeyExchangeCalcPubVal
        OpEventKeyExchangeCalcPubVal_KeyExchangeCalcPubVal_Ssa_SharedSecretHash: start-on-event=KeyExchangeCalcPubVal, operation=Ssa_SharedSecretHash.KeyExchangeCalcPubVal
        OpEventKeyExchangeCalcPubVal_KeyExchangeCalcPubVal_Ssa_SignatureRamKey: start-on-event=KeyExchangeCalcPubVal, operation=Ssa_SignatureRamKey.KeyExchangeCalcPubVal
        OpEventKeyExchangeCalcPubVal_KeyExchangeCalcPubVal_Ssa_Authentication: start-on-event=KeyExchangeCalcPubVal, operation=Ssa_Authentication.KeyExchangeCalcPubVal
        OpEventKeyExchangeCalcPubVal_KeyExchangeCalcPubVal_KeyM_SigVerifyKey_TrustModelEcuPeer: start-on-event=KeyExchangeCalcPubVal, operation=KeyM_SigVerifyKey_TrustModelEcuPeer.KeyExchangeCalcPubVal
        OpEventKeyExchangeCalcPubVal_KeyExchangeCalcPubVal_Ssa_RootCert: start-on-event=KeyExchangeCalcPubVal, operation=Ssa_RootCert.KeyExchangeCalcPubVal
        OpEventKeyExchangeCalcPubVal_KeyExchangeCalcPubVal_Ssa_VIN: start-on-event=KeyExchangeCalcPubVal, operation=Ssa_VIN.KeyExchangeCalcPubVal
        OpEventKeyExchangeCalcPubVal_KeyExchangeCalcPubVal_Ssa_SecurityAccessPublicKey: start-on-event=KeyExchangeCalcPubVal, operation=Ssa_SecurityAccessPublicKey.KeyExchangeCalcPubVal
        OpEventKeyExchangeCalcPubVal_KeyExchangeCalcPubVal_Ssa_TickCount: start-on-event=KeyExchangeCalcPubVal, operation=Ssa_TickCount.KeyExchangeCalcPubVal
        OpEventKeyElementCopy_KeyElementCopy_Ssa_AesRamKey: start-on-event=KeyElementCopy, operation=Ssa_AesRamKey.KeyElementCopy
        OpEventKeyElementCopy_KeyElementCopy_Ssa_RealTime: start-on-event=KeyElementCopy, operation=Ssa_RealTime.KeyElementCopy
        OpEventKeyElementCopy_KeyElementCopy_Ssa_RandomSeed: start-on-event=KeyElementCopy, operation=Ssa_RandomSeed.KeyElementCopy
        OpEventKeyElementCopy_KeyElementCopy_Ssa_SharedSecretKeyExchange: start-on-event=KeyElementCopy, operation=Ssa_SharedSecretKeyExchange.KeyElementCopy
        OpEventKeyElementCopy_KeyElementCopy_KeyM_SigVerifyKey_TrustModelEcuPeer: start-on-event=KeyElementCopy, operation=KeyM_SigVerifyKey_TrustModelEcuPeer.KeyElementCopy
        OpEventKeyElementCopy_KeyElementCopy_Ssa_SecurityAccessPublicKey: start-on-event=KeyElementCopy, operation=Ssa_SecurityAccessPublicKey.KeyElementCopy
        OpEventKeyElementCopy_KeyElementCopy_Ssa_SignatureRamKey: start-on-event=KeyElementCopy, operation=Ssa_SignatureRamKey.KeyElementCopy
        OpEventKeyElementCopy_KeyElementCopy_Ssa_TickCount: start-on-event=KeyElementCopy, operation=Ssa_TickCount.KeyElementCopy
        OpEventKeyElementCopy_KeyElementCopy_Ssa_Authentication: start-on-event=KeyElementCopy, operation=Ssa_Authentication.KeyElementCopy
        OpEventKeyElementCopy_KeyElementCopy_Ssa_SharedSecretHash: start-on-event=KeyElementCopy, operation=Ssa_SharedSecretHash.KeyElementCopy
        OpEventKeyElementCopy_KeyElementCopy_Ssa_BackendCert: start-on-event=KeyElementCopy, operation=Ssa_BackendCert.KeyElementCopy
        OpEventKeyElementCopy_KeyElementCopy_Ssa_VIN: start-on-event=KeyElementCopy, operation=Ssa_VIN.KeyElementCopy
        OpEventKeyElementCopy_KeyElementCopy_Ssa_RootCert: start-on-event=KeyElementCopy, operation=Ssa_RootCert.KeyElementCopy
        OpEventMacGenerate_MacGenerate_Ssa_MacGen_TickCount_MacGenerate: start-on-event=MacGenerate, operation=Ssa_MacGen_TickCount_MacGenerate.MacGenerate
        OpEventMacGenerate_MacGenerate_Ssa_MacGen_RealTime_MacGenerate: start-on-event=MacGenerate, operation=Ssa_MacGen_RealTime_MacGenerate.MacGenerate
        OpEventMacGenerate_MacGenerate_KeyM_MacGenerate_PduKeyMac_MacGenerate: start-on-event=MacGenerate, operation=KeyM_MacGenerate_PduKeyMac_MacGenerate.MacGenerate
        OpEventDecrypt_Decrypt_Ssa_Decrypt_Aes128_Decrypt: start-on-event=Decrypt, operation=Ssa_Decrypt_Aes128_Decrypt.Decrypt
        OpEventSignatureVerify_SignatureVerify_Ssa_SigVerify_Coding_SignatureVerify: start-on-event=SignatureVerify, operation=Ssa_SigVerify_Coding_SignatureVerify.SignatureVerify
        OpEventSignatureVerify_SignatureVerify_Ssa_SigVerify_RamKey_SignatureVerify: start-on-event=SignatureVerify, operation=Ssa_SigVerify_RamKey_SignatureVerify.SignatureVerify
        OpEventSignatureVerify_SignatureVerify_Ssa_SigVerify_SecurityAccess_SignatureVerify: start-on-event=SignatureVerify, operation=Ssa_SigVerify_SecurityAccess_SignatureVerify.SignatureVerify
        OpEventSignatureVerify_SignatureVerify_SSA_SigVerify_KeyM_TrustModel_SignatureVerify: start-on-event=SignatureVerify, operation=SSA_SigVerify_KeyM_TrustModel_SignatureVerify.SignatureVerify
        OpEventMacVerify_MacVerify_Ssa_MacVerify_RealTime_MacVerify: start-on-event=MacVerify, operation=Ssa_MacVerify_RealTime_MacVerify.MacVerify
        OpEventMacVerify_MacVerify_Ssa_MacVerify_TickCount_MacVerify: start-on-event=MacVerify, operation=Ssa_MacVerify_TickCount_MacVerify.MacVerify
        OpEventMacVerify_MacVerify_Ssa_MacVerify_Authentication_MacVerify: start-on-event=MacVerify, operation=Ssa_MacVerify_Authentication_MacVerify.MacVerify
        OpEventMacVerify_MacVerify_Ssa_MacVerify_VIN_MacVerify: start-on-event=MacVerify, operation=Ssa_MacVerify_VIN_MacVerify.MacVerify
        OpEventRandomSeed_RandomSeed_CsmKey_Ssa_TrustModelPrivateEcu_LiveKey: start-on-event=RandomSeed, operation=CsmKey_Ssa_TrustModelPrivateEcu_LiveKey.RandomSeed
        OpEventRandomSeed_RandomSeed_CsmKey_Ssa_TrustModelEcuPublic_LiveKey: start-on-event=RandomSeed, operation=CsmKey_Ssa_TrustModelEcuPublic_LiveKey.RandomSeed
        OpEventRandomSeed_RandomSeed_CsmKey_Ssa_TrustModelPrivateEcuUnique_StagingKey: start-on-event=RandomSeed, operation=CsmKey_Ssa_TrustModelPrivateEcuUnique_StagingKey.RandomSeed
        OpEventRandomSeed_RandomSeed_CsmKey_Ssa_TrustModelEcuPublicCsr_StagingKey: start-on-event=RandomSeed, operation=CsmKey_Ssa_TrustModelEcuPublicCsr_StagingKey.RandomSeed
        OpEventKeyExchangeCalcSecret_KeyExchangeCalcSecret_CsmKey_Ssa_TrustModelEcuPublicCsr_StagingKey: start-on-event=KeyExchangeCalcSecret, operation=CsmKey_Ssa_TrustModelEcuPublicCsr_StagingKey.KeyExchangeCalcSecret
        OpEventKeyExchangeCalcSecret_KeyExchangeCalcSecret_CsmKey_Ssa_TrustModelPrivateEcuUnique_StagingKey: start-on-event=KeyExchangeCalcSecret, operation=CsmKey_Ssa_TrustModelPrivateEcuUnique_StagingKey.KeyExchangeCalcSecret
        OpEventKeyExchangeCalcSecret_KeyExchangeCalcSecret_CsmKey_Ssa_TrustModelEcuPublic_LiveKey: start-on-event=KeyExchangeCalcSecret, operation=CsmKey_Ssa_TrustModelEcuPublic_LiveKey.KeyExchangeCalcSecret
        OpEventKeyExchangeCalcSecret_KeyExchangeCalcSecret_CsmKey_Ssa_TrustModelPrivateEcu_LiveKey: start-on-event=KeyExchangeCalcSecret, operation=CsmKey_Ssa_TrustModelPrivateEcu_LiveKey.KeyExchangeCalcSecret
        OpEventKeySetValid_KeySetValid_CsmKey_Ssa_TrustModelEcuPublic_LiveKey: start-on-event=KeySetValid, operation=CsmKey_Ssa_TrustModelEcuPublic_LiveKey.KeySetValid
        OpEventKeySetValid_KeySetValid_CsmKey_Ssa_TrustModelPrivateEcu_LiveKey: start-on-event=KeySetValid, operation=CsmKey_Ssa_TrustModelPrivateEcu_LiveKey.KeySetValid
        OpEventKeySetValid_KeySetValid_CsmKey_Ssa_TrustModelEcuPublicCsr_StagingKey: start-on-event=KeySetValid, operation=CsmKey_Ssa_TrustModelEcuPublicCsr_StagingKey.KeySetValid
        OpEventKeySetValid_KeySetValid_CsmKey_Ssa_TrustModelPrivateEcuUnique_StagingKey: start-on-event=KeySetValid, operation=CsmKey_Ssa_TrustModelPrivateEcuUnique_StagingKey.KeySetValid
        OpEventKeyCopy_KeyCopy_CsmKey_Ssa_TrustModelPrivateEcuUnique_StagingKey: start-on-event=KeyCopy, operation=CsmKey_Ssa_TrustModelPrivateEcuUnique_StagingKey.KeyCopy
        OpEventKeyCopy_KeyCopy_CsmKey_Ssa_TrustModelPrivateEcu_LiveKey: start-on-event=KeyCopy, operation=CsmKey_Ssa_TrustModelPrivateEcu_LiveKey.KeyCopy
        OpEventKeyCopy_KeyCopy_CsmKey_Ssa_TrustModelEcuPublic_LiveKey: start-on-event=KeyCopy, operation=CsmKey_Ssa_TrustModelEcuPublic_LiveKey.KeyCopy
        OpEventKeyCopy_KeyCopy_CsmKey_Ssa_TrustModelEcuPublicCsr_StagingKey: start-on-event=KeyCopy, operation=CsmKey_Ssa_TrustModelEcuPublicCsr_StagingKey.KeyCopy
        OpEventKeyDerive_KeyDerive_CsmKey_Ssa_TrustModelPrivateEcuUnique_StagingKey: start-on-event=KeyDerive, operation=CsmKey_Ssa_TrustModelPrivateEcuUnique_StagingKey.KeyDerive
        OpEventKeyDerive_KeyDerive_CsmKey_Ssa_TrustModelEcuPublicCsr_StagingKey: start-on-event=KeyDerive, operation=CsmKey_Ssa_TrustModelEcuPublicCsr_StagingKey.KeyDerive
        OpEventKeyDerive_KeyDerive_CsmKey_Ssa_TrustModelEcuPublic_LiveKey: start-on-event=KeyDerive, operation=CsmKey_Ssa_TrustModelEcuPublic_LiveKey.KeyDerive
        OpEventKeyDerive_KeyDerive_CsmKey_Ssa_TrustModelPrivateEcu_LiveKey: start-on-event=KeyDerive, operation=CsmKey_Ssa_TrustModelPrivateEcu_LiveKey.KeyDerive
        OpEventCertificateVerify_CertificateVerify_CsmKey_Ssa_TrustModelEcuPublicCsr_StagingKey: start-on-event=CertificateVerify, operation=CsmKey_Ssa_TrustModelEcuPublicCsr_StagingKey.CertificateVerify
        OpEventCertificateVerify_CertificateVerify_CsmKey_Ssa_TrustModelPrivateEcu_LiveKey: start-on-event=CertificateVerify, operation=CsmKey_Ssa_TrustModelPrivateEcu_LiveKey.CertificateVerify
        OpEventCertificateVerify_CertificateVerify_CsmKey_Ssa_TrustModelEcuPublic_LiveKey: start-on-event=CertificateVerify, operation=CsmKey_Ssa_TrustModelEcuPublic_LiveKey.CertificateVerify
        OpEventCertificateVerify_CertificateVerify_CsmKey_Ssa_TrustModelPrivateEcuUnique_StagingKey: start-on-event=CertificateVerify, operation=CsmKey_Ssa_TrustModelPrivateEcuUnique_StagingKey.CertificateVerify
        OpEventCertificateParse_CertificateParse_CsmKey_Ssa_TrustModelEcuPublic_LiveKey: start-on-event=CertificateParse, operation=CsmKey_Ssa_TrustModelEcuPublic_LiveKey.CertificateParse
        OpEventCertificateParse_CertificateParse_CsmKey_Ssa_TrustModelPrivateEcuUnique_StagingKey: start-on-event=CertificateParse, operation=CsmKey_Ssa_TrustModelPrivateEcuUnique_StagingKey.CertificateParse
        OpEventCertificateParse_CertificateParse_CsmKey_Ssa_TrustModelPrivateEcu_LiveKey: start-on-event=CertificateParse, operation=CsmKey_Ssa_TrustModelPrivateEcu_LiveKey.CertificateParse
        OpEventCertificateParse_CertificateParse_CsmKey_Ssa_TrustModelEcuPublicCsr_StagingKey: start-on-event=CertificateParse, operation=CsmKey_Ssa_TrustModelEcuPublicCsr_StagingKey.CertificateParse
        OpEventKeyElementCopy_KeyElementCopy_CsmKey_Ssa_TrustModelPrivateEcuUnique_StagingKey: start-on-event=KeyElementCopy, operation=CsmKey_Ssa_TrustModelPrivateEcuUnique_StagingKey.KeyElementCopy
        OpEventKeyElementCopy_KeyElementCopy_CsmKey_Ssa_TrustModelPrivateEcu_LiveKey: start-on-event=KeyElementCopy, operation=CsmKey_Ssa_TrustModelPrivateEcu_LiveKey.KeyElementCopy
        OpEventKeyElementCopy_KeyElementCopy_CsmKey_Ssa_TrustModelEcuPublic_LiveKey: start-on-event=KeyElementCopy, operation=CsmKey_Ssa_TrustModelEcuPublic_LiveKey.KeyElementCopy
        OpEventKeyElementCopy_KeyElementCopy_CsmKey_Ssa_TrustModelEcuPublicCsr_StagingKey: start-on-event=KeyElementCopy, operation=CsmKey_Ssa_TrustModelEcuPublicCsr_StagingKey.KeyElementCopy
        OpEventKeyElementGet_KeyElementGet_CsmKey_Ssa_TrustModelEcuPublic_LiveKey: start-on-event=KeyElementGet, operation=CsmKey_Ssa_TrustModelEcuPublic_LiveKey.KeyElementGet
        OpEventKeyElementGet_KeyElementGet_CsmKey_Ssa_TrustModelPrivateEcuUnique_StagingKey: start-on-event=KeyElementGet, operation=CsmKey_Ssa_TrustModelPrivateEcuUnique_StagingKey.KeyElementGet
        OpEventKeyElementGet_KeyElementGet_CsmKey_Ssa_TrustModelEcuPublicCsr_StagingKey: start-on-event=KeyElementGet, operation=CsmKey_Ssa_TrustModelEcuPublicCsr_StagingKey.KeyElementGet
        OpEventKeyElementGet_KeyElementGet_CsmKey_Ssa_TrustModelPrivateEcu_LiveKey: start-on-event=KeyElementGet, operation=CsmKey_Ssa_TrustModelPrivateEcu_LiveKey.KeyElementGet
        OpEventKeyGenerate_KeyGenerate_CsmKey_Ssa_TrustModelEcuPublic_LiveKey: start-on-event=KeyGenerate, operation=CsmKey_Ssa_TrustModelEcuPublic_LiveKey.KeyGenerate
        OpEventKeyGenerate_KeyGenerate_CsmKey_Ssa_TrustModelPrivateEcuUnique_StagingKey: start-on-event=KeyGenerate, operation=CsmKey_Ssa_TrustModelPrivateEcuUnique_StagingKey.KeyGenerate
        OpEventKeyGenerate_KeyGenerate_CsmKey_Ssa_TrustModelEcuPublicCsr_StagingKey: start-on-event=KeyGenerate, operation=CsmKey_Ssa_TrustModelEcuPublicCsr_StagingKey.KeyGenerate
        OpEventKeyGenerate_KeyGenerate_CsmKey_Ssa_TrustModelPrivateEcu_LiveKey: start-on-event=KeyGenerate, operation=CsmKey_Ssa_TrustModelPrivateEcu_LiveKey.KeyGenerate
        OpEventKeyExchangeCalcPubVal_KeyExchangeCalcPubVal_CsmKey_Ssa_TrustModelEcuPublicCsr_StagingKey: start-on-event=KeyExchangeCalcPubVal, operation=CsmKey_Ssa_TrustModelEcuPublicCsr_StagingKey.KeyExchangeCalcPubVal
        OpEventKeyExchangeCalcPubVal_KeyExchangeCalcPubVal_CsmKey_Ssa_TrustModelEcuPublic_LiveKey: start-on-event=KeyExchangeCalcPubVal, operation=CsmKey_Ssa_TrustModelEcuPublic_LiveKey.KeyExchangeCalcPubVal
        OpEventKeyExchangeCalcPubVal_KeyExchangeCalcPubVal_CsmKey_Ssa_TrustModelPrivateEcuUnique_StagingKey: start-on-event=KeyExchangeCalcPubVal, operation=CsmKey_Ssa_TrustModelPrivateEcuUnique_StagingKey.KeyExchangeCalcPubVal
        OpEventKeyExchangeCalcPubVal_KeyExchangeCalcPubVal_CsmKey_Ssa_TrustModelPrivateEcu_LiveKey: start-on-event=KeyExchangeCalcPubVal, operation=CsmKey_Ssa_TrustModelPrivateEcu_LiveKey.KeyExchangeCalcPubVal
        OpEventKeyElementCopyPartial_KeyElementCopyPartial_CsmKey_Ssa_TrustModelEcuPublic_LiveKey: start-on-event=KeyElementCopyPartial, operation=CsmKey_Ssa_TrustModelEcuPublic_LiveKey.KeyElementCopyPartial
        OpEventKeyElementCopyPartial_KeyElementCopyPartial_CsmKey_Ssa_TrustModelPrivateEcuUnique_StagingKey: start-on-event=KeyElementCopyPartial, operation=CsmKey_Ssa_TrustModelPrivateEcuUnique_StagingKey.KeyElementCopyPartial
        OpEventKeyElementCopyPartial_KeyElementCopyPartial_CsmKey_Ssa_TrustModelEcuPublicCsr_StagingKey: start-on-event=KeyElementCopyPartial, operation=CsmKey_Ssa_TrustModelEcuPublicCsr_StagingKey.KeyElementCopyPartial
        OpEventKeyElementCopyPartial_KeyElementCopyPartial_CsmKey_Ssa_TrustModelPrivateEcu_LiveKey: start-on-event=KeyElementCopyPartial, operation=CsmKey_Ssa_TrustModelPrivateEcu_LiveKey.KeyElementCopyPartial
        OpEventKeyElementSet_KeyElementSet_CsmKey_Ssa_TrustModelPrivateEcu_LiveKey: start-on-event=KeyElementSet, operation=CsmKey_Ssa_TrustModelPrivateEcu_LiveKey.KeyElementSet
        OpEventKeyElementSet_KeyElementSet_CsmKey_Ssa_TrustModelEcuPublic_LiveKey: start-on-event=KeyElementSet, operation=CsmKey_Ssa_TrustModelEcuPublic_LiveKey.KeyElementSet
        OpEventKeyElementSet_KeyElementSet_CsmKey_Ssa_TrustModelPrivateEcuUnique_StagingKey: start-on-event=KeyElementSet, operation=CsmKey_Ssa_TrustModelPrivateEcuUnique_StagingKey.KeyElementSet
        OpEventKeyElementSet_KeyElementSet_CsmKey_Ssa_TrustModelEcuPublicCsr_StagingKey: start-on-event=KeyElementSet, operation=CsmKey_Ssa_TrustModelEcuPublicCsr_StagingKey.KeyElementSet
        OpEventCancelJob_CancelJob_Ssa_SigVerify_replacementAuthority_SignatureVerify: start-on-event=CancelJob, operation=Ssa_SigVerify_replacementAuthority_SignatureVerify.CancelJob
        OpEventSignatureVerify_SignatureVerify_Ssa_SigVerify_replacementAuthority_SignatureVerify: start-on-event=SignatureVerify, operation=Ssa_SigVerify_replacementAuthority_SignatureVerify.SignatureVerify
        OpEventCancelJob_CancelJob_Ssa_SigGenerate_KeyM_TrustModel_with_LiveKey_SignatureGenerate: start-on-event=CancelJob, operation=Ssa_SigGenerate_KeyM_TrustModel_with_LiveKey_SignatureGenerate.CancelJob
        OpEventSignatureGenerate_SignatureGenerate_Ssa_SigGenerate_KeyM_TrustModel_with_LiveKey_SignatureGenerate: start-on-event=SignatureGenerate, operation=Ssa_SigGenerate_KeyM_TrustModel_with_LiveKey_SignatureGenerate.SignatureGenerate
        OpEventKeyExchangeCalcPubVal_KeyExchangeCalcPubVal_CsmKey_Ssa_TrustModel_Ecu_CsrPrivateKey: start-on-event=KeyExchangeCalcPubVal, operation=CsmKey_Ssa_TrustModel_Ecu_CsrPrivateKey.KeyExchangeCalcPubVal
        OpEventCertificateVerify_CertificateVerify_CsmKey_Ssa_TrustModel_Ecu_CsrPrivateKey: start-on-event=CertificateVerify, operation=CsmKey_Ssa_TrustModel_Ecu_CsrPrivateKey.CertificateVerify
        OpEventKeyElementCopy_KeyElementCopy_CsmKey_Ssa_TrustModel_Ecu_CsrPrivateKey: start-on-event=KeyElementCopy, operation=CsmKey_Ssa_TrustModel_Ecu_CsrPrivateKey.KeyElementCopy
        OpEventKeyDerive_KeyDerive_CsmKey_Ssa_TrustModel_Ecu_CsrPrivateKey: start-on-event=KeyDerive, operation=CsmKey_Ssa_TrustModel_Ecu_CsrPrivateKey.KeyDerive
        OpEventKeyExchangeCalcSecret_KeyExchangeCalcSecret_CsmKey_Ssa_TrustModel_Ecu_CsrPrivateKey: start-on-event=KeyExchangeCalcSecret, operation=CsmKey_Ssa_TrustModel_Ecu_CsrPrivateKey.KeyExchangeCalcSecret
        OpEventKeyElementGet_KeyElementGet_CsmKey_Ssa_TrustModel_Ecu_CsrPrivateKey: start-on-event=KeyElementGet, operation=CsmKey_Ssa_TrustModel_Ecu_CsrPrivateKey.KeyElementGet
        OpEventKeyCopy_KeyCopy_CsmKey_Ssa_TrustModel_Ecu_CsrPrivateKey: start-on-event=KeyCopy, operation=CsmKey_Ssa_TrustModel_Ecu_CsrPrivateKey.KeyCopy
        OpEventRandomSeed_RandomSeed_CsmKey_Ssa_TrustModel_Ecu_CsrPrivateKey: start-on-event=RandomSeed, operation=CsmKey_Ssa_TrustModel_Ecu_CsrPrivateKey.RandomSeed
        OpEventKeySetValid_KeySetValid_CsmKey_Ssa_TrustModel_Ecu_CsrPrivateKey: start-on-event=KeySetValid, operation=CsmKey_Ssa_TrustModel_Ecu_CsrPrivateKey.KeySetValid
        OpEventKeyElementSet_KeyElementSet_CsmKey_Ssa_TrustModel_Ecu_CsrPrivateKey: start-on-event=KeyElementSet, operation=CsmKey_Ssa_TrustModel_Ecu_CsrPrivateKey.KeyElementSet
        OpEventKeyElementCopyPartial_KeyElementCopyPartial_CsmKey_Ssa_TrustModel_Ecu_CsrPrivateKey: start-on-event=KeyElementCopyPartial, operation=CsmKey_Ssa_TrustModel_Ecu_CsrPrivateKey.KeyElementCopyPartial
        OpEventKeyGenerate_KeyGenerate_CsmKey_Ssa_TrustModel_Ecu_CsrPrivateKey: start-on-event=KeyGenerate, operation=CsmKey_Ssa_TrustModel_Ecu_CsrPrivateKey.KeyGenerate
        OpEventCertificateParse_CertificateParse_CsmKey_Ssa_TrustModel_Ecu_CsrPrivateKey: start-on-event=CertificateParse, operation=CsmKey_Ssa_TrustModel_Ecu_CsrPrivateKey.CertificateParse
        OpEventKeyElementGet_KeyElementGet_CsmKey_Ssa_TrustModel_Ecu_CsrPublicKey: start-on-event=KeyElementGet, operation=CsmKey_Ssa_TrustModel_Ecu_CsrPublicKey.KeyElementGet
        OpEventKeyCopy_KeyCopy_CsmKey_Ssa_TrustModel_Ecu_CsrPublicKey: start-on-event=KeyCopy, operation=CsmKey_Ssa_TrustModel_Ecu_CsrPublicKey.KeyCopy
        OpEventRandomSeed_RandomSeed_CsmKey_Ssa_TrustModel_Ecu_CsrPublicKey: start-on-event=RandomSeed, operation=CsmKey_Ssa_TrustModel_Ecu_CsrPublicKey.RandomSeed
        OpEventKeyGenerate_KeyGenerate_CsmKey_Ssa_TrustModel_Ecu_CsrPublicKey: start-on-event=KeyGenerate, operation=CsmKey_Ssa_TrustModel_Ecu_CsrPublicKey.KeyGenerate
        OpEventKeySetValid_KeySetValid_CsmKey_Ssa_TrustModel_Ecu_CsrPublicKey: start-on-event=KeySetValid, operation=CsmKey_Ssa_TrustModel_Ecu_CsrPublicKey.KeySetValid
        OpEventKeyExchangeCalcSecret_KeyExchangeCalcSecret_CsmKey_Ssa_TrustModel_Ecu_CsrPublicKey: start-on-event=KeyExchangeCalcSecret, operation=CsmKey_Ssa_TrustModel_Ecu_CsrPublicKey.KeyExchangeCalcSecret
        OpEventKeyElementCopy_KeyElementCopy_CsmKey_Ssa_TrustModel_Ecu_CsrPublicKey: start-on-event=KeyElementCopy, operation=CsmKey_Ssa_TrustModel_Ecu_CsrPublicKey.KeyElementCopy
        OpEventKeyElementSet_KeyElementSet_CsmKey_Ssa_TrustModel_Ecu_CsrPublicKey: start-on-event=KeyElementSet, operation=CsmKey_Ssa_TrustModel_Ecu_CsrPublicKey.KeyElementSet
        OpEventCertificateVerify_CertificateVerify_CsmKey_Ssa_TrustModel_Ecu_CsrPublicKey: start-on-event=CertificateVerify, operation=CsmKey_Ssa_TrustModel_Ecu_CsrPublicKey.CertificateVerify
        OpEventKeyExchangeCalcPubVal_KeyExchangeCalcPubVal_CsmKey_Ssa_TrustModel_Ecu_CsrPublicKey: start-on-event=KeyExchangeCalcPubVal, operation=CsmKey_Ssa_TrustModel_Ecu_CsrPublicKey.KeyExchangeCalcPubVal
        OpEventKeyElementCopyPartial_KeyElementCopyPartial_CsmKey_Ssa_TrustModel_Ecu_CsrPublicKey: start-on-event=KeyElementCopyPartial, operation=CsmKey_Ssa_TrustModel_Ecu_CsrPublicKey.KeyElementCopyPartial
        OpEventKeyDerive_KeyDerive_CsmKey_Ssa_TrustModel_Ecu_CsrPublicKey: start-on-event=KeyDerive, operation=CsmKey_Ssa_TrustModel_Ecu_CsrPublicKey.KeyDerive
        OpEventCertificateParse_CertificateParse_CsmKey_Ssa_TrustModel_Ecu_CsrPublicKey: start-on-event=CertificateParse, operation=CsmKey_Ssa_TrustModel_Ecu_CsrPublicKey.CertificateParse
        OpEventCancelJob_CancelJob_Ssa_SigGenerate_KeyM_TrustModel_with_changeableKey_SignatureGenerate: start-on-event=CancelJob, operation=Ssa_SigGenerate_KeyM_TrustModel_with_changeableKey_SignatureGenerate.CancelJob
        OpEventSignatureGenerate_SignatureGenerate_Ssa_SigGenerate_KeyM_TrustModel_with_changeableKey_SignatureGenerate: start-on-event=SignatureGenerate, operation=Ssa_SigGenerate_KeyM_TrustModel_with_changeableKey_SignatureGenerate.SignatureGenerate
        OpEventKeyElementGet_KeyElementGet_CsmKey_Ssa_SignatureRamKey_replacementAuthority: start-on-event=KeyElementGet, operation=CsmKey_Ssa_SignatureRamKey_replacementAuthority.KeyElementGet
        OpEventKeySetValid_KeySetValid_CsmKey_Ssa_SignatureRamKey_replacementAuthority: start-on-event=KeySetValid, operation=CsmKey_Ssa_SignatureRamKey_replacementAuthority.KeySetValid
        OpEventKeyExchangeCalcSecret_KeyExchangeCalcSecret_CsmKey_Ssa_SignatureRamKey_replacementAuthority: start-on-event=KeyExchangeCalcSecret, operation=CsmKey_Ssa_SignatureRamKey_replacementAuthority.KeyExchangeCalcSecret
        OpEventKeyGenerate_KeyGenerate_CsmKey_Ssa_SignatureRamKey_replacementAuthority: start-on-event=KeyGenerate, operation=CsmKey_Ssa_SignatureRamKey_replacementAuthority.KeyGenerate
        OpEventKeyElementCopy_KeyElementCopy_CsmKey_Ssa_SignatureRamKey_replacementAuthority: start-on-event=KeyElementCopy, operation=CsmKey_Ssa_SignatureRamKey_replacementAuthority.KeyElementCopy
        OpEventKeyElementCopyPartial_KeyElementCopyPartial_CsmKey_Ssa_SignatureRamKey_replacementAuthority: start-on-event=KeyElementCopyPartial, operation=CsmKey_Ssa_SignatureRamKey_replacementAuthority.KeyElementCopyPartial
        OpEventCertificateVerify_CertificateVerify_CsmKey_Ssa_SignatureRamKey_replacementAuthority: start-on-event=CertificateVerify, operation=CsmKey_Ssa_SignatureRamKey_replacementAuthority.CertificateVerify
        OpEventKeyExchangeCalcPubVal_KeyExchangeCalcPubVal_CsmKey_Ssa_SignatureRamKey_replacementAuthority: start-on-event=KeyExchangeCalcPubVal, operation=CsmKey_Ssa_SignatureRamKey_replacementAuthority.KeyExchangeCalcPubVal
        OpEventKeyCopy_KeyCopy_CsmKey_Ssa_SignatureRamKey_replacementAuthority: start-on-event=KeyCopy, operation=CsmKey_Ssa_SignatureRamKey_replacementAuthority.KeyCopy
        OpEventKeyDerive_KeyDerive_CsmKey_Ssa_SignatureRamKey_replacementAuthority: start-on-event=KeyDerive, operation=CsmKey_Ssa_SignatureRamKey_replacementAuthority.KeyDerive
        OpEventRandomSeed_RandomSeed_CsmKey_Ssa_SignatureRamKey_replacementAuthority: start-on-event=RandomSeed, operation=CsmKey_Ssa_SignatureRamKey_replacementAuthority.RandomSeed
        OpEventCertificateParse_CertificateParse_CsmKey_Ssa_SignatureRamKey_replacementAuthority: start-on-event=CertificateParse, operation=CsmKey_Ssa_SignatureRamKey_replacementAuthority.CertificateParse
        OpEventKeyElementSet_KeyElementSet_CsmKey_Ssa_SignatureRamKey_replacementAuthority: start-on-event=KeyElementSet, operation=CsmKey_Ssa_SignatureRamKey_replacementAuthority.KeyElementSet
        OpEventRandomGenerate_RandomGenerate_Ssa_Random_TRNG_RandomGenerate: start-on-event=RandomGenerate, operation=Ssa_Random_TRNG_RandomGenerate.RandomGenerate
        OpEventCancelJobNoOpMode_CancelJob_Ssa_Random_TRNG_RandomGenerate: start-on-event=CancelJobNoOpMode, operation=Ssa_Random_TRNG_RandomGenerate.CancelJob
        OpEventCancelJob_CancelJob_Ssa_SigVerify_Coding_HWA_SignatureVerify: start-on-event=CancelJob, operation=Ssa_SigVerify_Coding_HWA_SignatureVerify.CancelJob
        OpEventSignatureVerify_SignatureVerify_Ssa_SigVerify_Coding_HWA_SignatureVerify: start-on-event=SignatureVerify, operation=Ssa_SigVerify_Coding_HWA_SignatureVerify.SignatureVerify
      port-api-options:
        {enable-take-address=true, indirect-api=false, port-defined-argument-value{value=keyId:48, value-type=uint32}, port=Ssa_TickCount}
        {enable-take-address=true, indirect-api=false, port-defined-argument-value{value=keyId:38, value-type=uint32}, port=Ssa_Authentication}
        {enable-take-address=true, indirect-api=false, port-defined-argument-value{value=keyId:49, value-type=uint32}, port=Ssa_VIN}
        {enable-take-address=true, indirect-api=false, port-defined-argument-value{value=keyId:42, value-type=uint32}, port=Ssa_RealTime}
        {enable-take-address=true, indirect-api=false, port-defined-argument-value{value=keyId:46, value-type=uint32}, port=Ssa_SharedSecretKeyExchange}
        {enable-take-address=true, indirect-api=false, port-defined-argument-value{value=keyId:39, value-type=uint32}, port=Ssa_BackendCert}
        {enable-take-address=true, indirect-api=false, port-defined-argument-value{value=keyId:43, value-type=uint32}, port=Ssa_RootCert}
        {enable-take-address=true, indirect-api=false, port-defined-argument-value{value=keyId:41, value-type=uint32}, port=Ssa_RandomSeed}
        {enable-take-address=true, indirect-api=false, port-defined-argument-value{value=keyId:37, value-type=uint32}, port=Ssa_AesRamKey}
        {enable-take-address=true, indirect-api=false, port-defined-argument-value{value=keyId:45, value-type=uint32}, port=Ssa_SharedSecretHash}
        {enable-take-address=true, indirect-api=false, port-defined-argument-value{value=keyId:47, value-type=uint32}, port=Ssa_SignatureRamKey}
        {enable-take-address=true, indirect-api=false, port-defined-argument-value{value=keyId:22, value-type=uint32}, port=KeyM_SigVerifyKey_TrustModelEcuPeer}
        {enable-take-address=true, indirect-api=false, port-defined-argument-value{value=keyId:44, value-type=uint32}, port=Ssa_SecurityAccessPublicKey}
        {enable-take-address=true, indirect-api=false, port-defined-argument-value{value=keyId:5, value-type=uint32}, port=CsmKey_Ssa_SignatureRamKey_replacementAuthority}
        {enable-take-address=true, indirect-api=false, port-defined-argument-value{value=keyId:11, value-type=uint32}, port=CsmKey_Ssa_TrustModelPrivateEcuUnique_StagingKey}
        {enable-take-address=true, indirect-api=false, port-defined-argument-value{value=keyId:9, value-type=uint32}, port=CsmKey_Ssa_TrustModelEcuPublic_LiveKey}
        {enable-take-address=true, indirect-api=false, port-defined-argument-value{value=keyId:8, value-type=uint32}, port=CsmKey_Ssa_TrustModelEcuPublicCsr_StagingKey}
        {enable-take-address=true, indirect-api=false, port-defined-argument-value{value=keyId:13, value-type=uint32}, port=CsmKey_Ssa_TrustModelPrivateEcu_LiveKey}
        {enable-take-address=true, indirect-api=false, port-defined-argument-value{value=keyId:15, value-type=uint32}, port=CsmKey_Ssa_TrustModel_Ecu_CsrPrivateKey}
        {enable-take-address=true, indirect-api=false, port-defined-argument-value{value=keyId:16, value-type=uint32}, port=CsmKey_Ssa_TrustModel_Ecu_CsrPublicKey}
        {enable-take-address=true, indirect-api=false, port-arg-values=[{value=36, value-type=uint32}, {value=7, value-type=Crypto_OperationModeType}], port=Ssa_SigVerify_Coding_SignatureVerify}
        {enable-take-address=true, indirect-api=false, port-arg-values=[{value=26, value-type=uint32}, {value=7, value-type=Crypto_OperationModeType}], port=Ssa_Hash_Sha2_512_Hash}
        {enable-take-address=true, indirect-api=false, port-arg-values=[{value=30, value-type=uint32}, {value=7, value-type=Crypto_OperationModeType}], port=Ssa_MacVerify_RealTime_MacVerify}
        {enable-take-address=true, indirect-api=false, port-arg-values=[{value=31, value-type=uint32}, {value=7, value-type=Crypto_OperationModeType}], port=Ssa_MacVerify_TickCount_MacVerify}
        {enable-take-address=true, indirect-api=false, port-arg-values=[{value=29, value-type=uint32}, {value=7, value-type=Crypto_OperationModeType}], port=Ssa_MacVerify_Authentication_MacVerify}
        {enable-take-address=true, indirect-api=false, port-arg-values=[{value=32, value-type=uint32}, {value=7, value-type=Crypto_OperationModeType}], port=Ssa_MacVerify_VIN_MacVerify}
        {enable-take-address=true, indirect-api=false, port-arg-values=[{value=25, value-type=uint32}, {value=7, value-type=Crypto_OperationModeType}], port=Ssa_Decrypt_Aes128_Decrypt}
        {enable-take-address=true, indirect-api=false, port-arg-values=[{value=28, value-type=uint32}, {value=7, value-type=Crypto_OperationModeType}], port=Ssa_MacGen_TickCount_MacGenerate}
        {enable-take-address=true, indirect-api=false, port-arg-values=[{value=27, value-type=uint32}, {value=7, value-type=Crypto_OperationModeType}], port=Ssa_MacGen_RealTime_MacGenerate}
        {enable-take-address=true, indirect-api=false, port-arg-values=[{value=38, value-type=uint32}, {value=7, value-type=Crypto_OperationModeType}], port=Ssa_SigVerify_RamKey_SignatureVerify}
        {enable-take-address=true, indirect-api=false, port-arg-values=[{value=40, value-type=uint32}, {value=7, value-type=Crypto_OperationModeType}], port=Ssa_SigVerify_SecurityAccess_SignatureVerify}
        {enable-take-address=true, indirect-api=false, port-arg-values=[{value=0, value-type=uint32}, {value=7, value-type=Crypto_OperationModeType}], port=KeyM_MacGenerate_PduKeyMac_MacGenerate}
        {enable-take-address=true, indirect-api=false, port-arg-values=[{value=24, value-type=uint32}, {value=7, value-type=Crypto_OperationModeType}], port=SSA_SigVerify_KeyM_TrustModel_SignatureVerify}
        {enable-take-address=true, indirect-api=false, port-arg-values=[{value=35, value-type=uint32}, {value=7, value-type=Crypto_OperationModeType}], port=Ssa_SigGenerate_KeyM_TrustModel_with_changeableKey_SignatureGenerate}
        {enable-take-address=true, indirect-api=false, port-arg-values=[{value=41, value-type=uint32}, {value=7, value-type=Crypto_OperationModeType}], port=Ssa_SigVerify_replacementAuthority_SignatureVerify}
        {enable-take-address=true, indirect-api=false, port-arg-values=[{value=34, value-type=uint32}, {value=7, value-type=Crypto_OperationModeType}], port=Ssa_SigGenerate_KeyM_TrustModel_with_LiveKey_SignatureGenerate}
        {enable-take-address=true, indirect-api=false, port-defined-argument-value{value=33, value-type=uint32}, port=Ssa_Random_TRNG_RandomGenerate}
        {enable-take-address=true, indirect-api=false, port-arg-values=[{value=37, value-type=uint32}, {value=7, value-type=Crypto_OperationModeType}], port=Ssa_SigVerify_Coding_HWA_SignatureVerify}
      23 x runnable:
        Csm_MainFunction
        CancelJob: can-be-invoked-concurrently=true, symbol=Csm_CancelJob
        KeySetValid: can-be-invoked-concurrently=true, symbol=Csm_KeySetValid
        RandomSeed: can-be-invoked-concurrently=true, symbol=Csm_RandomSeed
        KeyElementCopyPartial: can-be-invoked-concurrently=true, symbol=Csm_KeyElementCopyPartial
        KeyElementSet: can-be-invoked-concurrently=true, symbol=Csm_KeyElementSet
        Hash: can-be-invoked-concurrently=true, symbol=Csm_Hash
        MacVerify: can-be-invoked-concurrently=true, symbol=Csm_MacVerify
        RandomGenerate: can-be-invoked-concurrently=true, symbol=Csm_RandomGenerate
        MacGenerate: can-be-invoked-concurrently=true, symbol=Csm_MacGenerate
        SignatureGenerate: can-be-invoked-concurrently=true, symbol=Csm_SignatureGenerate
        CancelJobNoOpMode: can-be-invoked-concurrently=true, symbol=Csm_CancelJobNoOpMode
        Decrypt: can-be-invoked-concurrently=true, symbol=Csm_Decrypt
        KeyCopy: can-be-invoked-concurrently=true, symbol=Csm_KeyCopy
        CertificateParse: can-be-invoked-concurrently=true, symbol=Csm_CertificateParse
        CertificateVerify: can-be-invoked-concurrently=true, symbol=Csm_CertificateVerify
        KeyDerive: can-be-invoked-concurrently=true, symbol=Csm_KeyDerive
        KeyGenerate: can-be-invoked-concurrently=true, symbol=Csm_KeyGenerate
        KeyElementGet: can-be-invoked-concurrently=true, symbol=Csm_KeyElementGet
        KeyExchangeCalcSecret: can-be-invoked-concurrently=true, symbol=Csm_KeyExchangeCalcSecret
        KeyExchangeCalcPubVal: can-be-invoked-concurrently=true, symbol=Csm_KeyExchangeCalcPubVal
        KeyElementCopy: can-be-invoked-concurrently=true, symbol=Csm_KeyElementCopy
        SignatureVerify: can-be-invoked-concurrently=true, symbol=Csm_SignatureVerify
  swc implementation CsmImplementation: programming-language=C, behavior=CsmInternalBehavior
